AUTOSAR XML (schema 4-2-2)
package /DBC_SysDesc_Can_Network/Pkg_Cluster
  can cluster Can_Network: baudrate=500000, protocol-name=CAN
    can physical channel Can_Network_Channel: comm-connectors=Conn_Can_Network_CANNODE_0_BMS
      frame TMR_3: id 0x328, to BMS, frame-length=8, can-addressing-mode=STANDARD, can-frame-rx-behavior=ANY
        carries pdu TMR_3: packing-byte-order=big-endian, start-position=7, update-indication-bit-position=-1
        pdu TMR_3: length=8, transmission-mode-false-timing=cyclic-timing={time-offset=0.0, time-period=0.05}, transmission-mode-true-timing=cyclic-timing={time-offset=0.0, time-period=0.05}
          transmission-mode-conditions:
            {data-filter={data-filter-type=NEW-IS-WITHIN, max=1021, min=0, offset=0}, i-signal-in-i-pdu=TMR_VoltageHV}
            {data-filter={data-filter-type=NEW-IS-WITHIN, max=2044, min=0}, i-signal-in-i-pdu=TMR_CurrentHV}
          signal TMR_VoltageHV: start 12, 10 bit, big-endian, init-value=0, base-type=uint16, compu {raw=phys for phys 0..1021; unit V}, update-indication-bit-position=-1, to BMS  # HV voltage at the DC/AC converter"
          signal TMR_CurrentHV: start 7, 11 bit, big-endian, init-value=1023, base-type=uint16, compu {raw=phys+1023 for phys -1023..1021; unit Ampere}, update-indication-bit-position=-1, to BMS  # HV current at the DC/AC converter"
      frame EMS_4_G: id 0x4D9, to BMS, frame-length=8, can-addressing-mode=STANDARD, can-frame-rx-behavior=ANY  # Source network message is \"Cyclic, 100ms\". If no messages are received on source network, no messages are sent on the destination network."
        carries pdu EMS_4_G: packing-byte-order=big-endian, start-position=7, update-indication-bit-position=-1
        pdu EMS_4_G: length=8, transmission-mode-condition{data-filter={data-filter-type=NEW-IS-WITHIN, max=65532, min=0, offset=0}, i-signal-in-i-pdu=EMS_4_G_EngineSpeed_Actual}, transmission-mode-false-timing=cyclic-timing={time-offset=0.0, time-period=0.1}, transmission-mode-true-timing=cyclic-timing={time-offset=0.0, time-period=0.1}  # Source network message is \Cyclic, 100ms\. If no messages are received on source network, no messages are sent on the destination network.
          signal EMS_4_G_EngineSpeed_Actual: start 7, 16 bit, big-endian, init-value=0, base-type=uint16, compu {raw=phys*4 for phys 0..16383; unit rpm}, update-indication-bit-position=-1, to BMS  # PHEV:Actual Engine speed send by EMS to HCU"
      frame OBC_2: id 0x428, to BMS, frame-length=8, can-addressing-mode=STANDARD, can-frame-rx-behavior=ANY
        carries pdu OBC_2: packing-byte-order=big-endian, start-position=7, update-indication-bit-position=-1
        pdu OBC_2: length=8, transmission-mode-false-timing=cyclic-timing={time-offset=0.0, time-period=0.1}, transmission-mode-true-timing=cyclic-timing={time-offset=0.0, time-period=0.1}
          transmission-mode-conditions:
            {data-filter={data-filter-type=ALWAYS, max=1, min=0, offset=0}, i-signal-in-i-pdu=OBC_KL30_UnderVolt}
            {data-filter={data-filter-type=NEW-IS-WITHIN, max=20000, min=0, offset=0}, i-signal-in-i-pdu=OBC_InputVolt}
            {data-filter={data-filter-type=NEW-IS-WITHIN, max=8000, min=0, offset=0}, i-signal-in-i-pdu=OBC_InputCurr}
          signal OBC_KL30_UnderVolt: start 55, 1 bit, big-endian, init-value=0, base-type=uint8, compu {raw=phys for phys 0..1, 0=NOFAULT, 1=FAULT}, update-indication-bit-position=-1, to BMS  # KL30 under voltage"
          signal OBC_InputVolt: start 23, 16 bit, big-endian, init-value=0, base-type=uint16, compu {raw=phys*20 for phys 0..1000; unit V}, update-indication-bit-position=-1, to BMS  # OBC input voltage"
          signal OBC_InputCurr: start 7, 16 bit, big-endian, init-value=0, base-type=uint16, compu {raw=phys*20 for phys 0..400; unit Ampere}, update-indication-bit-position=-1, to BMS  # OBC input current"
      frame OBC_4: id 0x43C, to BMS, frame-length=8, can-addressing-mode=STANDARD, can-frame-rx-behavior=ANY
        carries pdu OBC_4: packing-byte-order=big-endian, start-position=7, update-indication-bit-position=-1
        pdu OBC_4: length=8, transmission-mode-false-timing=cyclic-timing={time-offset=0.0, time-period=0.1}, transmission-mode-true-timing=cyclic-timing={time-offset=0.0, time-period=0.1}
          transmission-mode-conditions:
            {data-filter={data-filter-type=ALWAYS, max=0, min=0, offset=0}, i-signal-in-i-pdu=OBC_ChargeSourceMode}
            {data-filter={data-filter-type=ALWAYS, max=255, min=0, offset=0}, i-signal-in-i-pdu=OBC_FaultCode}
            {data-filter={data-filter-type=NEW-IS-WITHIN, max=20000, min=0, offset=0}, i-signal-in-i-pdu=OBC_MaxOutputVoltage}
            {data-filter={data-filter-type=NEW-IS-WITHIN, max=8000, min=0, offset=0}, i-signal-in-i-pdu=OBC_MaxOutputCurrent}
          signal OBC_ChargeSourceMode: start 53, 2 bit, big-endian, init-value=0, base-type=uint8, compu-method=CompuMethod_OBC_ChargeSourceMode, update-indication-bit-position=-1, to BMS  # Charge Source Mode"
          signal OBC_FaultCode: start 39, 8 bit, big-endian, init-value=0, base-type=uint8, compu {raw=phys for phys 0..255}, update-indication-bit-position=-1, to BMS  # OBC fault matrix"
          signal OBC_MaxOutputVoltage: start 23, 16 bit, big-endian, init-value=0, base-type=uint16, compu {raw=phys*20 for phys 0..1000; unit V}, update-indication-bit-position=-1, to BMS  # OBC maximum output current"
          signal OBC_MaxOutputCurrent: start 7, 16 bit, big-endian, init-value=0, base-type=uint16, compu {raw=phys*20 for phys 0..400; unit Ampere}, update-indication-bit-position=-1, to BMS  # OBC maximum output voltage"
      frame ABS_ESP_G: id 0x502, to BMS, frame-length=7, can-addressing-mode=STANDARD, can-frame-rx-behavior=ANY  # Source network message is \"Cyclic, 100ms\". If no messages are received on source network, no messages are sent on the destination network."
        carries pdu ABS_ESP_G: packing-byte-order=big-endian, start-position=7, update-indication-bit-position=-1
        pdu ABS_ESP_G: length=7, transmission-mode-false-timing=cyclic-timing={time-offset=0.0, time-period=0.1}, transmission-mode-true-timing=cyclic-timing={time-offset=0.0, time-period=0.1}  # Source network message is \Cyclic, 100ms\. If no messages are received on source network, no messages are sent on the destination network.
          transmission-mode-conditions:
            {data-filter={data-filter-type=ALWAYS, max=1, min=0, offset=0}, i-signal-in-i-pdu=VehicleSpeedVSOSigValidData}
            {data-filter={data-filter-type=NEW-IS-WITHIN, max=8190, min=0, offset=0}, i-signal-in-i-pdu=VehicleSpeedVSOSig}
          signal VehicleSpeedVSOSigValidData: start 31, 1 bit, big-endian, init-value=1, base-type=uint8, compu {raw=phys for phys 0..1, 0=VALID, 1=NOTVALID}, update-indication-bit-position=-1, to BMS
          signal VehicleSpeedVSOSig: start 12, 13 bit, big-endian, init-value=0, base-type=uint16, compu {raw=phys*16 for phys 0..511.875; unit km_h}, update-indication-bit-position=-1, to BMS
      frame TMR_1: id 0x173, to BMS, frame-length=8, can-addressing-mode=STANDARD, can-frame-rx-behavior=ANY
        carries pdu TMR_1: packing-byte-order=big-endian, start-position=7, update-indication-bit-position=-1
        pdu TMR_1: length=8, transmission-mode-condition{data-filter={data-filter-type=ALWAYS, max=15, min=0, offset=0}, i-signal-in-i-pdu=TMR_State}, transmission-mode-false-timing=cyclic-timing={time-offset=0.0, time-period=0.01}, transmission-mode-true-timing=cyclic-timing={time-offset=0.0, time-period=0.01}
          signal TMR_State: start 55, 4 bit, big-endian, init-value=0, base-type=uint8, compu-method=CompuMethod_TMR_State, update-indication-bit-position=-1, to BMS  # actual state of TMR motor"
      frame OBC_1: id 0x425, to BMS, frame-length=8, can-addressing-mode=STANDARD, can-frame-rx-behavior=ANY
        carries pdu OBC_1: packing-byte-order=big-endian, start-position=7, update-indication-bit-position=-1
        pdu OBC_1: length=8, transmission-mode-false-timing=cyclic-timing={time-offset=0.0, time-period=0.1}, transmission-mode-true-timing=cyclic-timing={time-offset=0.0, time-period=0.1}
          transmission-mode-conditions:
            {data-filter={data-filter-type=ALWAYS, max=7, min=0, offset=0}, i-signal-in-i-pdu=OBC_FaultLevelSts}
            {data-filter={data-filter-type=NEW-IS-WITHIN, max=4000, min=0, offset=0}, i-signal-in-i-pdu=OBC_OutputPowerLimt}
            {data-filter={data-filter-type=NEW-IS-WITHIN, max=20000, min=0, offset=0}, i-signal-in-i-pdu=OBC_ChgVolt}
            {data-filter={data-filter-type=NEW-IS-WITHIN, max=8000, min=0, offset=0}, i-signal-in-i-pdu=OBC_ChgCurr}
          signal OBC_FaultLevelSts: start 41, 3 bit, big-endian, init-value=0, base-type=uint8, compu-method=CompuMethod_OBC_FaultLevelSts, update-indication-bit-position=-1, to BMS  # OBC fault states"
          signal OBC_OutputPowerLimt: start 39, 12 bit, big-endian, init-value=0, base-type=uint16, compu {raw=phys*10 for phys 0..400; unit KW}, update-indication-bit-position=-1, to BMS  # output power limit"
          signal OBC_ChgVolt: start 23, 16 bit, big-endian, init-value=0, base-type=uint16, compu {raw=phys*20 for phys 0..1000; unit V}, update-indication-bit-position=-1, to BMS  # output voltage"
          signal OBC_ChgCurr: start 7, 16 bit, big-endian, init-value=0, base-type=uint16, compu {raw=phys*20 for phys 0..400; unit Ampere}, update-indication-bit-position=-1, to BMS  # output current"
      frame TMF_3: id 0x31B, to BMS, frame-length=8, can-addressing-mode=STANDARD, can-frame-rx-behavior=ANY
        carries pdu TMF_3: packing-byte-order=big-endian, start-position=7, update-indication-bit-position=-1
        pdu TMF_3: length=8, transmission-mode-false-timing=cyclic-timing={time-offset=0.0, time-period=0.05}, transmission-mode-true-timing=cyclic-timing={time-offset=0.0, time-period=0.05}
          transmission-mode-conditions:
            {data-filter={data-filter-type=NEW-IS-WITHIN, max=1021, min=0, offset=0}, i-signal-in-i-pdu=TMF_UdcAct}
            {data-filter={data-filter-type=NEW-IS-WITHIN, max=2044, min=0}, i-signal-in-i-pdu=TMF_IdcAct}
          signal TMF_UdcAct: start 12, 10 bit, big-endian, init-value=0, base-type=uint16, compu {raw=phys for phys 0..1021; unit V}, update-indication-bit-position=-1, to BMS  # actual bus voltage"
          signal TMF_IdcAct: start 7, 11 bit, big-endian, init-value=1023, base-type=uint16, compu {raw=phys+1023 for phys -1023..1021; unit Ampere}, update-indication-bit-position=-1, to BMS  # actual HV current at generator"
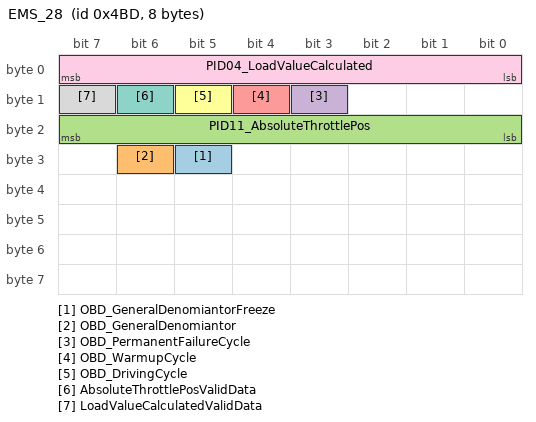
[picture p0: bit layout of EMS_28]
      frame EMS_28: id 0x4BD, to BMS, frame-length=8, can-addressing-mode=STANDARD, can-frame-rx-behavior=ANY  # Source network message is \"Cyclic, 100ms\". If no messages are received on source network, no messages are sent on the destination network."
        carries pdu EMS_28: packing-byte-order=big-endian, start-position=7, update-indication-bit-position=-1
        pdu EMS_28: length=8, transmission-mode-false-timing=cyclic-timing={time-offset=0.0, time-period=0.1}, transmission-mode-true-timing=cyclic-timing={time-offset=0.0, time-period=0.1}  # Source network message is \Cyclic, 100ms\. If no messages are received on source network, no messages are sent on the destination network.
          transmission-mode-conditions:
            {data-filter={data-filter-type=ALWAYS, max=1, min=0, offset=0}, i-signal-in-i-pdu=OBD_GeneralDenomiantorFreeze}
            {data-filter={data-filter-type=ALWAYS, max=1, min=0, offset=0}, i-signal-in-i-pdu=OBD_GeneralDenomiantor}
            {data-filter={data-filter-type=ALWAYS, max=255, min=0, offset=0}, i-signal-in-i-pdu=PID11_AbsoluteThrottlePos}
            {data-filter={data-filter-type=ALWAYS, max=1, min=0, offset=0}, i-signal-in-i-pdu=OBD_PermanentFailureCycle}
            {data-filter={data-filter-type=ALWAYS, max=1, min=0, offset=0}, i-signal-in-i-pdu=OBD_WarmupCycle}
            {data-filter={data-filter-type=ALWAYS, max=1, min=0, offset=0}, i-signal-in-i-pdu=OBD_DrivingCycle}
            {data-filter={data-filter-type=ALWAYS, max=1, min=0, offset=0}, i-signal-in-i-pdu=AbsoluteThrottlePosValidData}
            {data-filter={data-filter-type=ALWAYS, max=1, min=0, offset=0}, i-signal-in-i-pdu=LoadValueCalculatedValidData}
            {data-filter={data-filter-type=ALWAYS, max=255, min=0, offset=0}, i-signal-in-i-pdu=PID04_LoadValueCalculated}
          signal OBD_GeneralDenomiantorFreeze: start 29, 1 bit, big-endian, init-value=0, base-type=uint8, compu {raw=phys for phys 0..1, 0=NOTACTIVE, 1=ACTIVE}, update-indication-bit-position=-1, to BMS
          signal OBD_GeneralDenomiantor: start 30, 1 bit, big-endian, init-value=0, base-type=uint8, compu {raw=phys for phys 0..1, 0=NOTACTIVE, 1=ACTIVE}, update-indication-bit-position=-1, to BMS
          signal PID11_AbsoluteThrottlePos: start 23, 8 bit, big-endian, init-value=0, base-type=uint8, compu {raw=phys*2.551020408 for phys 0..99.96}, update-indication-bit-position=-1, to BMS  # ?????????¦Ë??"
          signal OBD_PermanentFailureCycle: start 11, 1 bit, big-endian, init-value=0, base-type=uint8, compu {raw=phys for phys 0..1, 0=NOTACTIVE, 1=ACTIVE}, update-indication-bit-position=-1, to BMS  # ???¨´????????"
          signal OBD_WarmupCycle: start 12, 1 bit, big-endian, init-value=0, base-type=uint8, compu {raw=phys for phys 0..1, 0=NOTACTIVE, 1=ACTIVE}, update-indication-bit-position=-1, to BMS  # ??????"
          signal OBD_DrivingCycle: start 13, 1 bit, big-endian, init-value=0, base-type=uint8, compu-method=CompuMethod_OBD_DrivingCycle, update-indication-bit-position=-1, to BMS  # DrivingCycle ??????"
          signal AbsoluteThrottlePosValidData: start 14, 1 bit, big-endian, init-value=0, base-type=uint8, compu {raw=phys for phys 0..1, 0=VALID, 1=INVALID}, update-indication-bit-position=-1, to BMS  # ?????????¦Ë????§¹¦Ë"
          signal LoadValueCalculatedValidData: start 15, 1 bit, big-endian, init-value=0, base-type=uint8, compu {raw=phys for phys 0..1, 0=VALID, 1=INVALID}, update-indication-bit-position=-1, to BMS  # ????????????§¹¦Ë"
          signal PID04_LoadValueCalculated: start 7, 8 bit, big-endian, init-value=0, base-type=uint8, compu {raw=phys*2.551020408 for phys 0..99.96}, update-indication-bit-position=-1, to BMS  # ??????????"
      frame CLM_2: id 0x535, to BMS, frame-length=8, can-addressing-mode=STANDARD, can-frame-rx-behavior=ANY  # Source network message is \"Cyclic, 100ms\". If no messages are received on source network, no messages are sent on the destination network."
        carries pdu CLM_2: packing-byte-order=big-endian, start-position=7, update-indication-bit-position=-1
        pdu CLM_2: length=8, transmission-mode-false-timing=cyclic-timing={time-offset=0.0, time-period=0.1}, transmission-mode-true-timing=cyclic-timing={time-offset=0.0, time-period=0.1}  # Source network message is \Cyclic, 100ms\. If no messages are received on source network, no messages are sent on the destination network.
          transmission-mode-conditions:
            {data-filter={data-filter-type=ALWAYS, max=250, min=0}, i-signal-in-i-pdu=ExternalTemperatureRaw_C}
            {data-filter={data-filter-type=ALWAYS, max=3, min=0, offset=0}, i-signal-in-i-pdu=ExternalTemperatureFailSts_GS}
          signal ExternalTemperatureRaw_C: start 55, 8 bit, big-endian, init-value=254, base-type=uint8, compu {raw=phys*2+80 for phys -40..85; unit C}, update-indication-bit-position=-1, to BMS  # Raw external temperature Invalid: When external temperature is fail, the signal value is 0xFF."
          signal ExternalTemperatureFailSts_GS: start 33, 2 bit, big-endian, init-value=0, base-type=uint8, compu-method=CompuMethod_ExternalTemperatureFailSts_GS, update-indication-bit-position=-1, to BMS  # ??????1?????? ???!mao!????????????"
      frame HCU_1_G: id 0x40A, to BMS, frame-length=8, can-addressing-mode=STANDARD, can-frame-rx-behavior=ANY
        carries pdu HCU_1_G: packing-byte-order=big-endian, start-position=7, update-indication-bit-position=-1
        pdu HCU_1_G: length=8, transmission-mode-false-timing=cyclic-timing={time-offset=0.0, time-period=0.1}, transmission-mode-true-timing=cyclic-timing={time-offset=0.0, time-period=0.1}
          transmission-mode-conditions:
            {data-filter={data-filter-type=ALWAYS, max=1, min=0, offset=0}, i-signal-in-i-pdu=HCU_PTReady}
            {data-filter={data-filter-type=ALWAYS, max=1, min=0, offset=0}, i-signal-in-i-pdu=HCU_HVReady}
          signal HCU_PTReady: start 49, 1 bit, big-endian, init-value=0, base-type=uint8, compu {raw=phys for phys 0..1, 0=LMPOFF, 1=LMPON}, update-indication-bit-position=-1, to BMS  # Drive Ready indication"
          signal HCU_HVReady: start 48, 1 bit, big-endian, init-value=0, base-type=uint8, compu {raw=phys for phys 0..1, 0=LMPOFF, 1=LMPON}, update-indication-bit-position=-1, to BMS  # HV Ready indication"
      frame TBOX_3: id 0x358, to BMS, frame-length=8, can-addressing-mode=STANDARD, can-frame-rx-behavior=ANY  # Source network message is \"Cyclic, 50ms\". If no messages are received on source network, no messages are sent on the destination network."
        carries pdu TBOX_3: packing-byte-order=big-endian, start-position=7, update-indication-bit-position=-1
        pdu TBOX_3: length=8, transmission-mode-condition{data-filter={data-filter-type=ALWAYS, max=1, min=0, offset=0}, i-signal-in-i-pdu=TBOX_ChargeAllow}, transmission-mode-false-timing=cyclic-timing={time-offset=0.0, time-period=0.05}, transmission-mode-true-timing=cyclic-timing={time-offset=0.0, time-period=0.05}  # Source network message is \Cyclic, 50ms\. If no messages are received on source network, no messages are sent on the destination network.
          signal TBOX_ChargeAllow: start 53, 1 bit, big-endian, init-value=0, base-type=uint8, compu {raw=phys for phys 0..1, 0=NOTALLOW, 1=ALLOW}, update-indication-bit-position=-1, to BMS
      frame DCDC_2: id 0x41E, to BMS, frame-length=8, can-addressing-mode=STANDARD, can-frame-rx-behavior=ANY
        carries pdu DCDC_2: packing-byte-order=big-endian, start-position=7, update-indication-bit-position=-1
        pdu DCDC_2: length=8, transmission-mode-false-timing=cyclic-timing={time-offset=0.0, time-period=0.1}, transmission-mode-true-timing=cyclic-timing={time-offset=0.0, time-period=0.1}
          transmission-mode-conditions:
            {data-filter={data-filter-type=NEW-IS-WITHIN, max=4000, min=0, offset=0}, i-signal-in-i-pdu=DCDC_HvCurr}
            {data-filter={data-filter-type=NEW-IS-WITHIN, max=10000, min=0, offset=0}, i-signal-in-i-pdu=DCDC_HvVolt}
          signal DCDC_HvCurr: start 23, 16 bit, big-endian, init-value=0, base-type=uint16, compu {raw=phys*10 for phys 0..400; unit Ampere}, update-indication-bit-position=-1, to BMS  # DCDC input current"
          signal DCDC_HvVolt: start 7, 16 bit, big-endian, init-value=0, base-type=uint16, compu {raw=phys*10 for phys 0..1000; unit V}, update-indication-bit-position=-1, to BMS  # DCDC input voltage"
      frame Diag_BMS_REQ: id 0x7E5, to BMS, frame-length=8, can-addressing-mode=STANDARD, can-frame-rx-behavior=ANY  # Source network message is \"NoMsgSendType\". If no messages are received on source network, no messages are sent on the destination network."
        carries pdu Diag_BMS_REQ: packing-byte-order=big-endian, start-position=7, update-indication-bit-position=-1
        dcm i pdu Diag_BMS_REQ: length=8, diag-pdu-type=DIAG-REQUEST  # Source network message is \NoMsgSendType\. If no messages are received on source network, no messages are sent on the destination network.
      frame ICM_1: id 0x430, to BMS, frame-length=8, can-addressing-mode=STANDARD, can-frame-rx-behavior=ANY  # Source network message is \"Cyclic, 20ms\". If no messages are received on source network, no messages are sent on the destination network."
        carries pdu ICM_1: packing-byte-order=big-endian, start-position=7, update-indication-bit-position=-1
        pdu ICM_1: length=8, transmission-mode-false-timing=cyclic-timing={time-offset=0.0, time-period=0.02}, transmission-mode-true-timing=cyclic-timing={time-offset=0.0, time-period=0.02}  # Source network message is \Cyclic, 20ms\. If no messages are received on source network, no messages are sent on the destination network.
          transmission-mode-conditions:
            {data-filter={data-filter-type=NEW-IS-WITHIN, max=999999, min=0, offset=0}, i-signal-in-i-pdu=TotalOdometer_km}
            {data-filter={data-filter-type=ALWAYS, max=254, min=0, offset=0}, i-signal-in-i-pdu=BatteryVoltage}
          signal TotalOdometer_km: start 43, 20 bit, big-endian, init-value=0, base-type=uint32, compu {raw=phys for phys 0..999999; unit km}, update-indication-bit-position=-1, to BMS
          signal BatteryVoltage: start 23, 8 bit, big-endian, init-value=0, base-type=uint8, compu {raw=phys*10 for phys 0..25.4; unit V}, update-indication-bit-position=-1, to BMS  # ????????????????"
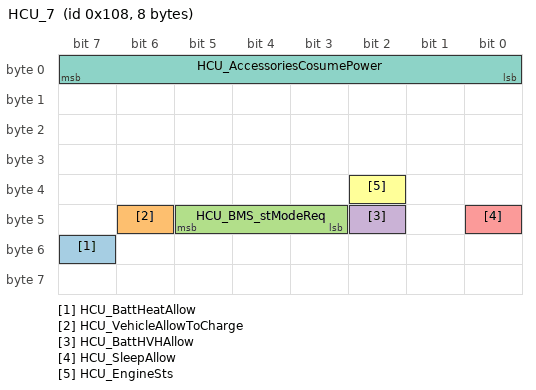
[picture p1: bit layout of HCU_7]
      frame HCU_7: id 0x108, to BMS, frame-length=8, can-addressing-mode=STANDARD, can-frame-rx-behavior=ANY
        carries pdu HCU_7: packing-byte-order=big-endian, start-position=7, update-indication-bit-position=-1
        pdu HCU_7: length=8, transmission-mode-false-timing=cyclic-timing={time-offset=0.0, time-period=0.01}, transmission-mode-true-timing=cyclic-timing={time-offset=0.0, time-period=0.01}
          transmission-mode-conditions:
            {data-filter={data-filter-type=ALWAYS, max=1, min=0, offset=0}, i-signal-in-i-pdu=HCU_BattHeatAllow}
            {data-filter={data-filter-type=ALWAYS, max=1, min=0, offset=0}, i-signal-in-i-pdu=HCU_VehicleAllowToCharge}
            {data-filter={data-filter-type=ALWAYS, max=7, min=0, offset=0}, i-signal-in-i-pdu=HCU_BMS_stModeReq}
            {data-filter={data-filter-type=ALWAYS, max=1, min=0, offset=0}, i-signal-in-i-pdu=HCU_BattHVHAllow}
            {data-filter={data-filter-type=ALWAYS, max=1, min=0, offset=0}, i-signal-in-i-pdu=HCU_SleepAllow}
            {data-filter={data-filter-type=ALWAYS, max=1, min=0, offset=0}, i-signal-in-i-pdu=HCU_EngineSts}
            {data-filter={data-filter-type=ALWAYS, max=200, min=0, offset=0}, i-signal-in-i-pdu=HCU_AccessoriesCosumePower}
          signal HCU_BattHeatAllow: start 55, 1 bit, big-endian, init-value=0, base-type=uint8, compu {raw=phys for phys 0..1, 0=NOREQUEST, 1=REQUEST}, update-indication-bit-position=-1, to BMS  # Battery pack heat request"
          signal HCU_VehicleAllowToCharge: start 46, 1 bit, big-endian, init-value=0, base-type=uint8, compu {raw=phys for phys 0..1, 0=NOTALLOWED, 1=ALLOWED}, update-indication-bit-position=-1, to BMS  # Indication of vehicle condition allow to charge or not"
          signal HCU_BMS_stModeReq: start 45, 3 bit, big-endian, init-value=0, base-type=uint8, compu-method=CompuMethod_HCU_BMS_stModeReq, update-indication-bit-position=-1, to BMS  # BMS recieves State request from HCU for power Up / power Down."
          signal HCU_BattHVHAllow: start 42, 1 bit, big-endian, init-value=0, base-type=uint8, compu {raw=phys for phys 0..1, 0=NOTALLOWED, 1=ALLOWED}, update-indication-bit-position=-1, to BMS  # high voltage heat allow"
          signal HCU_SleepAllow: start 40, 1 bit, big-endian, init-value=0, base-type=uint8, compu {raw=phys for phys 0..1, 0=ALLOWED, 1=NOTALLOWED}, update-indication-bit-position=-1, to BMS  # sleep allow command"
          signal HCU_EngineSts: start 34, 1 bit, big-endian, init-value=0, base-type=uint8, compu {raw=phys for phys 0..1, 0=NOTRUN, 1=RUN}, update-indication-bit-position=-1, to BMS  # actual engine status"
          signal HCU_AccessoriesCosumePower: start 7, 8 bit, big-endian, init-value=0, base-type=uint8, compu {raw=phys*10 for phys 0..20; unit KW}, update-indication-bit-position=-1, to BMS  # Accessories Consume Power"
      frame EMS_1_G: id 0x280, to BMS, frame-length=8, can-addressing-mode=STANDARD, can-frame-rx-behavior=ANY  # Source network message is \"Cyclic, 100ms\". If no messages are received on source network, no messages are sent on the destination network."
        carries pdu EMS_1_G: packing-byte-order=big-endian, start-position=7, update-indication-bit-position=-1
        pdu EMS_1_G: length=8, transmission-mode-false-timing=cyclic-timing={time-offset=0.0, time-period=0.1}, transmission-mode-true-timing=cyclic-timing={time-offset=0.0, time-period=0.1}  # Source network message is \Cyclic, 100ms\. If no messages are received on source network, no messages are sent on the destination network.
          transmission-mode-conditions:
            {data-filter={data-filter-type=ALWAYS, max=254, min=0}, i-signal-in-i-pdu=EngineCoolantTemperture}
            {data-filter={data-filter-type=ALWAYS, max=1, min=0, offset=0}, i-signal-in-i-pdu=EngineCoolantTempertureFailSts}
          signal EngineCoolantTemperture: start 23, 8 bit, big-endian, init-value=91, base-type=uint8, compu {raw=phys*1.333333333+64 for phys -48..142.5}, update-indication-bit-position=-1, to BMS
          signal EngineCoolantTempertureFailSts: start 11, 1 bit, big-endian, init-value=91, base-type=uint8, compu {raw=phys for phys 0..1, 0=FAILNOTPRESENT, 1=FAILPRESENT}, update-indication-bit-position=-1, to BMS
      frame DCDC_1: id 0x418, to BMS, frame-length=8, can-addressing-mode=STANDARD, can-frame-rx-behavior=ANY
        carries pdu DCDC_1: packing-byte-order=big-endian, start-position=7, update-indication-bit-position=-1
        pdu DCDC_1: length=8, transmission-mode-false-timing=cyclic-timing={time-offset=0.0, time-period=0.1}, transmission-mode-true-timing=cyclic-timing={time-offset=0.0, time-period=0.1}
          transmission-mode-conditions:
            {data-filter={data-filter-type=NEW-IS-WITHIN, max=510, min=0, offset=0}, i-signal-in-i-pdu=DCDC_LvSideCurr}
            {data-filter={data-filter-type=ALWAYS, max=253, min=0, offset=0}, i-signal-in-i-pdu=DCDC_LvSideVolt}
          signal DCDC_LvSideCurr: start 31, 9 bit, big-endian, init-value=0, base-type=uint16, compu {raw=phys for phys 0..510; unit Ampere}, update-indication-bit-position=-1, to BMS  # DCDC output current"
          signal DCDC_LvSideVolt: start 7, 8 bit, big-endian, init-value=0, base-type=uint8, compu {raw=phys*10 for phys 0..25.3; unit V}, update-indication-bit-position=-1, to BMS  # DCDC output voltage"
      frame DIAG_OBD_REQ_Broadcast: id 0x7DF, to BMS, frame-length=8, can-addressing-mode=STANDARD, can-frame-rx-behavior=ANY  # Source network message is \"NoMsgSendType,/\". If no messages are received on source network, no messages are sent on the destination network."
        carries pdu DIAG_OBD_REQ_Broadcast: packing-byte-order=big-endian, start-position=7, update-indication-bit-position=-1
        dcm i pdu DIAG_OBD_REQ_Broadcast: length=8, diag-pdu-type=DIAG-RESPONSE  # Source network message is \NoMsgSendType,/\. If no messages are received on source network, no messages are sent on the destination network.
      frame ISGF_3: id 0x312, to BMS, frame-length=8, can-addressing-mode=STANDARD, can-frame-rx-behavior=ANY
        carries pdu ISGF_3: packing-byte-order=big-endian, start-position=7, update-indication-bit-position=-1
        pdu ISGF_3: length=8, transmission-mode-false-timing=cyclic-timing={time-offset=0.0, time-period=0.05}, transmission-mode-true-timing=cyclic-timing={time-offset=0.0, time-period=0.05}
          transmission-mode-conditions:
            {data-filter={data-filter-type=NEW-IS-WITHIN, max=1021, min=0, offset=0}, i-signal-in-i-pdu=ISGF_UdcAct}
            {data-filter={data-filter-type=NEW-IS-WITHIN, max=2044, min=0}, i-signal-in-i-pdu=ISGF_IdcAct}
          signal ISGF_UdcAct: start 12, 10 bit, big-endian, init-value=0, base-type=uint16, compu {raw=phys for phys 0..1021; unit V}, update-indication-bit-position=-1, to BMS  # actual bus voltage"
          signal ISGF_IdcAct: start 7, 11 bit, big-endian, init-value=1023, base-type=uint16, compu {raw=phys+1023 for phys -1023..1021; unit Ampere}, update-indication-bit-position=-1, to BMS  # actual HV current at generator"
      frame TBOX_2: id 0x4F2, to BMS, frame-length=8, can-addressing-mode=STANDARD, can-frame-rx-behavior=ANY  # Source network message is \"NoMsgSendType, /\". If no messages are received on source network, no messages are sent on the destination network."
        carries pdu TBOX_2: packing-byte-order=big-endian, start-position=7, update-indication-bit-position=-1
        pdu TBOX_2: length=8, transmission-mode-condition{data-filter={data-filter-type=ALWAYS, max=3, min=0, offset=0}, i-signal-in-i-pdu=TBOX_BattHeatReq}  # Source network message is \NoMsgSendType, /\. If no messages are received on source network, no messages are sent on the destination network.
          signal TBOX_BattHeatReq: start 41, 2 bit, big-endian, init-value=0, base-type=uint8, compu {raw=phys for phys 0..3, 0=NOTACTIVE, 1=REQUEST, 2=NOREQUEST, 3=NOTUSED}, update-indication-bit-position=-1, to BMS  # ????????????"
      frame ISGF_1: id 0x146, to BMS, frame-length=8, can-addressing-mode=STANDARD, can-frame-rx-behavior=ANY
        carries pdu ISGF_1: packing-byte-order=big-endian, start-position=7, update-indication-bit-position=-1
        pdu ISGF_1: length=8, transmission-mode-condition{data-filter={data-filter-type=ALWAYS, max=15, min=0, offset=0}, i-signal-in-i-pdu=ISGF_ModeSt}, transmission-mode-false-timing=cyclic-timing={time-offset=0.0, time-period=0.01}, transmission-mode-true-timing=cyclic-timing={time-offset=0.0, time-period=0.01}
          signal ISGF_ModeSt: start 55, 4 bit, big-endian, init-value=0, base-type=uint8, compu-method=CompuMethod_ISGF_ModeSt, update-indication-bit-position=-1, to BMS  # actual state of ISG motor"
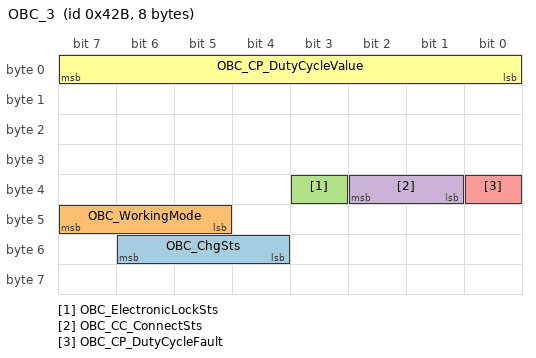
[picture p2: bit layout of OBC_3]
      frame OBC_3: id 0x42B, to BMS, frame-length=8, can-addressing-mode=STANDARD, can-frame-rx-behavior=ANY
        carries pdu OBC_3: packing-byte-order=big-endian, start-position=7, update-indication-bit-position=-1
        pdu OBC_3: length=8, transmission-mode-false-timing=cyclic-timing={time-offset=0.0, time-period=0.1}, transmission-mode-true-timing=cyclic-timing={time-offset=0.0, time-period=0.1}
          transmission-mode-conditions:
            {data-filter={data-filter-type=ALWAYS, max=7, min=0, offset=0}, i-signal-in-i-pdu=OBC_ChgSts}
            {data-filter={data-filter-type=ALWAYS, max=7, min=0, offset=0}, i-signal-in-i-pdu=OBC_WorkingMode}
            {data-filter={data-filter-type=ALWAYS, max=1, min=0, offset=0}, i-signal-in-i-pdu=OBC_ElectronicLockSts}
            {data-filter={data-filter-type=ALWAYS, max=3, min=0, offset=0}, i-signal-in-i-pdu=OBC_CC_ConnectSts}
            {data-filter={data-filter-type=ALWAYS, max=1, min=0, offset=0}, i-signal-in-i-pdu=OBC_CP_DutyCycleFault}
            {data-filter={data-filter-type=ALWAYS, max=100, min=0, offset=0}, i-signal-in-i-pdu=OBC_CP_DutyCycleValue}
          signal OBC_ChgSts: start 54, 3 bit, big-endian, init-value=0, base-type=uint8, compu-method=CompuMethod_OBC_ChgSts, update-indication-bit-position=-1, to BMS  # OBC charge stated"
          signal OBC_WorkingMode: start 47, 3 bit, big-endian, init-value=0, base-type=uint8, compu-method=CompuMethod_OBC_WorkingMode, update-indication-bit-position=-1, to BMS  # OBC working states"
          signal OBC_ElectronicLockSts: start 35, 1 bit, big-endian, init-value=0, base-type=uint8, compu {raw=phys for phys 0..1, 0=UNLOCK, 1=LOCK}, update-indication-bit-position=-1, to BMS  # Electronic Lock Sts"
          signal OBC_CC_ConnectSts: start 34, 2 bit, big-endian, init-value=0, base-type=uint8, compu-method=CompuMethod_OBC_CC_ConnectSts, update-indication-bit-position=-1, to BMS  # CC connect states"
          signal OBC_CP_DutyCycleFault: start 32, 1 bit, big-endian, init-value=0, base-type=uint8, compu {raw=phys for phys 0..1, 0=NOFAULT, 1=FAULT}, update-indication-bit-position=-1, to BMS  # CP pwm fault"
          signal OBC_CP_DutyCycleValue: start 7, 8 bit, big-endian, init-value=0, base-type=uint8, compu {raw=phys for phys 0..100; unit pct}, update-indication-bit-position=-1, to BMS  # CP pwm"
      frame TMF_1: id 0x15C, to BMS, frame-length=8, can-addressing-mode=STANDARD, can-frame-rx-behavior=ANY
        carries pdu TMF_1: packing-byte-order=big-endian, start-position=7, update-indication-bit-position=-1
        pdu TMF_1: length=8, transmission-mode-condition{data-filter={data-filter-type=ALWAYS, max=15, min=0, offset=0}, i-signal-in-i-pdu=TMF_ModeSt}, transmission-mode-false-timing=cyclic-timing={time-offset=0.0, time-period=0.01}, transmission-mode-true-timing=cyclic-timing={time-offset=0.0, time-period=0.01}
          signal TMF_ModeSt: start 55, 4 bit, big-endian, init-value=0, base-type=uint8, compu-method=CompuMethod_TMF_ModeSt, update-indication-bit-position=-1, to BMS  # actual state of TMF motor"
      frame ABM_1: id 0x320, to BMS, frame-length=4, can-addressing-mode=STANDARD, can-frame-rx-behavior=ANY  # Source network message is \"Cyclic, 500ms\". If no messages are received on source network, no messages are sent on the destination network."
        carries pdu ABM_1: packing-byte-order=big-endian, start-position=7, update-indication-bit-position=-1
        pdu ABM_1: length=4, transmission-mode-false-timing=cyclic-timing={time-offset=0.0, time-period=0.5}, transmission-mode-true-timing=cyclic-timing={time-offset=0.0, time-period=0.5}  # Source network message is \Cyclic, 500ms\. If no messages are received on source network, no messages are sent on the destination network.
          transmission-mode-conditions:
            {data-filter={data-filter-type=ALWAYS, max=255, min=0, offset=0}, i-signal-in-i-pdu=CrashOutputSts}
            {data-filter={data-filter-type=ALWAYS, max=255, min=0, offset=0}, i-signal-in-i-pdu=ABM_1_CheckSum}
            {data-filter={data-filter-type=ALWAYS, max=15, min=0, offset=0}, i-signal-in-i-pdu=ABM_1_MessageCounter}
          signal CrashOutputSts: start 31, 8 bit, big-endian, init-value=0, base-type=uint8, compu-method=CompuMethod_CrashOutputSts, update-indication-bit-position=-1, to BMS  # Crash????????bit???????: ?????§Ø???????????!dou!????????????????????¦Ë??????1.????????????????!dou!?????????????00001100"
          signal ABM_1_CheckSum: start 23, 8 bit, big-endian, init-value=0, base-type=uint8, compu {raw=phys for phys 0..255}, update-indication-bit-position=-1, to BMS  # ((Byte0+Byte1+Byte3) AND 0xFF) XOR 0xFF Note: Details Please refer to specification??Standard Specification for CAN Data Link Layer_v1.1??section 2.3.3"
          signal ABM_1_MessageCounter: start 15, 4 bit, big-endian, init-value=0, base-type=uint8, compu {raw=phys for phys 0..15}, update-indication-bit-position=-1, to BMS  # Rolling message counter(the maximum value of Alive counter is 15) Note: Details Please refer to specification??Standard Specification for CAN Data Link Layer_v1.1??section 2.3.1"
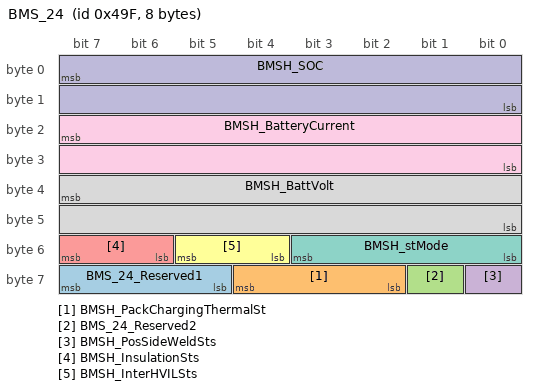
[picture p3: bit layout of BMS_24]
      frame BMS_24: id 0x49F, from BMS, frame-length=8, can-addressing-mode=STANDARD
        carries pdu BMS_24: packing-byte-order=big-endian, start-position=7, update-indication-bit-position=-1
        pdu BMS_24: length=8, transmission-mode-false-timing=cyclic-timing={time-offset=0.0, time-period=0.1}, transmission-mode-true-timing=cyclic-timing={time-offset=0.0, time-period=0.1}
          transmission-mode-conditions:
            {data-filter={data-filter-type=ALWAYS, max=0, min=0, offset=0}, i-signal-in-i-pdu=BMS_24_Reserved1}
            {data-filter={data-filter-type=ALWAYS, max=7, min=0, offset=0}, i-signal-in-i-pdu=BMSH_PackChargingThermalSt}
            {data-filter={data-filter-type=ALWAYS, max=0, min=0, offset=0}, i-signal-in-i-pdu=BMS_24_Reserved2}
            {data-filter={data-filter-type=ALWAYS, max=1, min=0, offset=0}, i-signal-in-i-pdu=BMS_24/BMSH_PosSideWeldSts}
            {data-filter={data-filter-type=ALWAYS, max=3, min=0, offset=0}, i-signal-in-i-pdu=BMS_24/BMSH_InsulationSts}
            {data-filter={data-filter-type=ALWAYS, max=3, min=0, offset=0}, i-signal-in-i-pdu=BMS_24/BMSH_InterHVILSts}
            {data-filter={data-filter-type=ALWAYS, max=15, min=0, offset=0}, i-signal-in-i-pdu=BMS_24/BMSH_stMode}
            {data-filter={data-filter-type=NEW-IS-WITHIN, max=20000, min=0, offset=0}, i-signal-in-i-pdu=BMS_24/BMSH_BattVolt}
            {data-filter={data-filter-type=NEW-IS-WITHIN, max=44000, min=20000}, i-signal-in-i-pdu=BMS_24/BMSH_BatteryCurrent}
            {data-filter={data-filter-type=NEW-IS-WITHIN, max=10000, min=0, offset=0}, i-signal-in-i-pdu=BMS_24/BMSH_SOC}
          signal BMS_24_Reserved1: start 63, 3 bit, big-endian, init-value=0, base-type=uint8, compu {raw=phys for phys 0}, update-indication-bit-position=-1
          signal BMSH_PackChargingThermalSt: start 60, 3 bit, big-endian, init-value=0, base-type=uint8, compu-method=CompuMethod_BMSH_PackChargingThermalSt, update-indication-bit-position=-1  # Pack Charging Thermal Status"
          signal BMS_24_Reserved2: start 57, 1 bit, big-endian, init-value=0, base-type=uint8, compu {raw=phys for phys 0}, update-indication-bit-position=-1
          signal BMSH_PosSideWeldSts: start 56, 1 bit, big-endian, init-value=0, base-type=uint8, compu {raw=phys for phys 0..1, 0=NOWELDED, 1=WELDED}, update-indication-bit-position=-1  # main Positive Side Weld Status"
          signal BMSH_InsulationSts: start 55, 2 bit, big-endian, init-value=0, base-type=uint8, compu-method=CompuMethod_BMSH_InsulationSts, update-indication-bit-position=-1  # Insulation Status"
          signal BMSH_InterHVILSts: start 53, 2 bit, big-endian, init-value=0, base-type=uint8, compu-method=CompuMethod_BMSH_InterHVILSts, update-indication-bit-position=-1  # Inter HV interlock Status"
          signal BMSH_stMode: start 51, 4 bit, big-endian, init-value=0, base-type=uint8, compu-method=CompuMethod_BMSH_stMode, update-indication-bit-position=-1  # state mode"
          signal BMSH_BattVolt: start 39, 16 bit, big-endian, init-value=0, base-type=uint16, compu {raw=phys*20 for phys 0..1000; unit V}, update-indication-bit-position=-1  # Battery Voltage"
          signal BMSH_BatteryCurrent: start 23, 16 bit, big-endian, init-value=32000, base-type=uint16, compu {raw=phys*20+32000 for phys -600..600; unit Ampere}, update-indication-bit-position=-1  # Battery Current"
          signal BMSH_SOC: start 7, 16 bit, big-endian, init-value=0, base-type=uint16, compu {raw=phys*100 for phys 0..100; unit pct}, update-indication-bit-position=-1  # SOC"
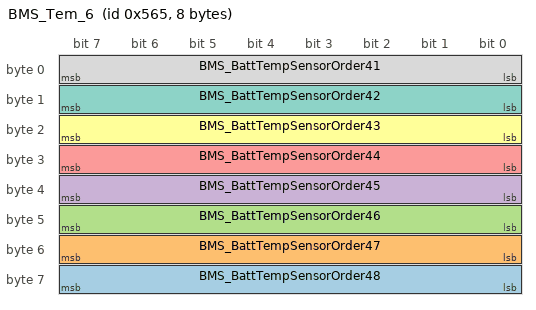
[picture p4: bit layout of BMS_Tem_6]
      frame BMS_Tem_6: id 0x565, from BMS, frame-length=8, can-addressing-mode=STANDARD
        carries pdu BMS_Tem_6: packing-byte-order=big-endian, start-position=7, update-indication-bit-position=-1
        pdu BMS_Tem_6: length=8, transmission-mode-false-timing=cyclic-timing={time-offset=0.0, time-period=1.0}, transmission-mode-true-timing=cyclic-timing={time-offset=0.0, time-period=1.0}
          transmission-mode-conditions:
            {data-filter={data-filter-type=ALWAYS, max=253, min=0}, i-signal-in-i-pdu=BMS_BattTempSensorOrder48}
            {data-filter={data-filter-type=ALWAYS, max=253, min=0}, i-signal-in-i-pdu=BMS_BattTempSensorOrder47}
            {data-filter={data-filter-type=ALWAYS, max=253, min=0}, i-signal-in-i-pdu=BMS_BattTempSensorOrder46}
            {data-filter={data-filter-type=ALWAYS, max=253, min=0}, i-signal-in-i-pdu=BMS_BattTempSensorOrder45}
            {data-filter={data-filter-type=ALWAYS, max=253, min=0}, i-signal-in-i-pdu=BMS_BattTempSensorOrder44}
            {data-filter={data-filter-type=ALWAYS, max=253, min=0}, i-signal-in-i-pdu=BMS_BattTempSensorOrder43}
            {data-filter={data-filter-type=ALWAYS, max=253, min=0}, i-signal-in-i-pdu=BMS_BattTempSensorOrder42}
            {data-filter={data-filter-type=ALWAYS, max=253, min=0}, i-signal-in-i-pdu=BMS_BattTempSensorOrder41}
          signal BMS_BattTempSensorOrder48: start 63, 8 bit, big-endian, init-value=0, base-type=uint8, compu {raw=phys+40 for phys -40..213; unit oC}, update-indication-bit-position=-1  # Battery Temperature Sensor Order48"
          signal BMS_BattTempSensorOrder47: start 55, 8 bit, big-endian, init-value=0, base-type=uint8, compu {raw=phys+40 for phys -40..213; unit oC}, update-indication-bit-position=-1  # Battery Temperature Sensor Order47"
          signal BMS_BattTempSensorOrder46: start 47, 8 bit, big-endian, init-value=0, base-type=uint8, compu {raw=phys+40 for phys -40..213; unit oC}, update-indication-bit-position=-1  # Battery Temperature Sensor Order46"
          signal BMS_BattTempSensorOrder45: start 39, 8 bit, big-endian, init-value=0, base-type=uint8, compu {raw=phys+40 for phys -40..213; unit oC}, update-indication-bit-position=-1  # Battery Temperature Sensor Order45"
          signal BMS_BattTempSensorOrder44: start 31, 8 bit, big-endian, init-value=0, base-type=uint8, compu {raw=phys+40 for phys -40..213; unit oC}, update-indication-bit-position=-1  # Battery Temperature Sensor Order44"
          signal BMS_BattTempSensorOrder43: start 23, 8 bit, big-endian, init-value=0, base-type=uint8, compu {raw=phys+40 for phys -40..213; unit oC}, update-indication-bit-position=-1  # Battery Temperature Sensor Order43"
          signal BMS_BattTempSensorOrder42: start 15, 8 bit, big-endian, init-value=0, base-type=uint8, compu {raw=phys+40 for phys -40..213; unit oC}, update-indication-bit-position=-1  # Battery Temperature Sensor Order42"
          signal BMS_BattTempSensorOrder41: start 7, 8 bit, big-endian, init-value=0, base-type=uint8, compu {raw=phys+40 for phys -40..213; unit oC}, update-indication-bit-position=-1  # Battery Temperature Sensor Order41"
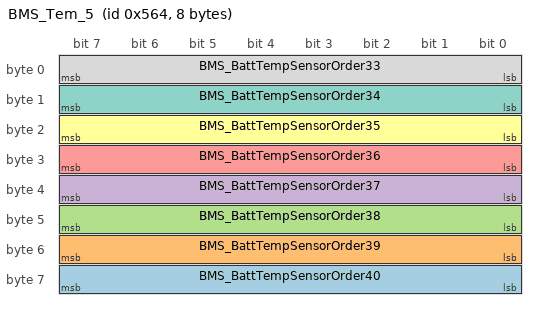
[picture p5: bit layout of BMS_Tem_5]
      frame BMS_Tem_5: id 0x564, from BMS, frame-length=8, can-addressing-mode=STANDARD
        carries pdu BMS_Tem_5: packing-byte-order=big-endian, start-position=7, update-indication-bit-position=-1
        pdu BMS_Tem_5: length=8, transmission-mode-false-timing=cyclic-timing={time-offset=0.0, time-period=1.0}, transmission-mode-true-timing=cyclic-timing={time-offset=0.0, time-period=1.0}
          transmission-mode-conditions:
            {data-filter={data-filter-type=ALWAYS, max=253, min=0}, i-signal-in-i-pdu=BMS_BattTempSensorOrder40}
            {data-filter={data-filter-type=ALWAYS, max=253, min=0}, i-signal-in-i-pdu=BMS_BattTempSensorOrder39}
            {data-filter={data-filter-type=ALWAYS, max=253, min=0}, i-signal-in-i-pdu=BMS_BattTempSensorOrder38}
            {data-filter={data-filter-type=ALWAYS, max=253, min=0}, i-signal-in-i-pdu=BMS_BattTempSensorOrder37}
            {data-filter={data-filter-type=ALWAYS, max=253, min=0}, i-signal-in-i-pdu=BMS_BattTempSensorOrder36}
            {data-filter={data-filter-type=ALWAYS, max=253, min=0}, i-signal-in-i-pdu=BMS_BattTempSensorOrder35}
            {data-filter={data-filter-type=ALWAYS, max=253, min=0}, i-signal-in-i-pdu=BMS_BattTempSensorOrder34}
            {data-filter={data-filter-type=ALWAYS, max=253, min=0}, i-signal-in-i-pdu=BMS_BattTempSensorOrder33}
          signal BMS_BattTempSensorOrder40: start 63, 8 bit, big-endian, init-value=0, base-type=uint8, compu {raw=phys+40 for phys -40..213; unit oC}, update-indication-bit-position=-1  # Battery Temperature Sensor Order40"
          signal BMS_BattTempSensorOrder39: start 55, 8 bit, big-endian, init-value=0, base-type=uint8, compu {raw=phys+40 for phys -40..213; unit oC}, update-indication-bit-position=-1  # Battery Temperature Sensor Order39"
          signal BMS_BattTempSensorOrder38: start 47, 8 bit, big-endian, init-value=0, base-type=uint8, compu {raw=phys+40 for phys -40..213; unit oC}, update-indication-bit-position=-1  # Battery Temperature Sensor Order38"
          signal BMS_BattTempSensorOrder37: start 39, 8 bit, big-endian, init-value=0, base-type=uint8, compu {raw=phys+40 for phys -40..213; unit oC}, update-indication-bit-position=-1  # Battery Temperature Sensor Order37"
          signal BMS_BattTempSensorOrder36: start 31, 8 bit, big-endian, init-value=0, base-type=uint8, compu {raw=phys+40 for phys -40..213; unit oC}, update-indication-bit-position=-1  # Battery Temperature Sensor Order36"
          signal BMS_BattTempSensorOrder35: start 23, 8 bit, big-endian, init-value=0, base-type=uint8, compu {raw=phys+40 for phys -40..213; unit oC}, update-indication-bit-position=-1  # Battery Temperature Sensor Order35"
          signal BMS_BattTempSensorOrder34: start 15, 8 bit, big-endian, init-value=0, base-type=uint8, compu {raw=phys+40 for phys -40..213; unit oC}, update-indication-bit-position=-1  # Battery Temperature Sensor Order34"
          signal BMS_BattTempSensorOrder33: start 7, 8 bit, big-endian, init-value=0, base-type=uint8, compu {raw=phys+40 for phys -40..213; unit oC}, update-indication-bit-position=-1  # Battery Temperature Sensor Order33"
      frame BMS_19: id 0x5B2, from BMS, frame-length=8, can-addressing-mode=STANDARD
        carries pdu BMS_19: packing-byte-order=big-endian, start-position=7, update-indication-bit-position=-1
        pdu BMS_19: length=8, transmission-mode-false-timing=cyclic-timing={time-offset=0.0, time-period=1.0}, transmission-mode-true-timing=cyclic-timing={time-offset=0.0, time-period=1.0}
          transmission-mode-conditions:
            {data-filter={data-filter-type=NEW-IS-WITHIN, max=0, min=0, offset=0}, i-signal-in-i-pdu=BMS_DTCOrder6}
            {data-filter={data-filter-type=NEW-IS-WITHIN, max=0, min=0, offset=0}, i-signal-in-i-pdu=BMS_DTCOrder5}
          signal BMS_DTCOrder6: start 39, 24 bit, big-endian, init-value=0, base-type=uint32, compu {raw=phys for phys 0}, update-indication-bit-position=-1  # DTC Order6"
          signal BMS_DTCOrder5: start 7, 24 bit, big-endian, init-value=0, base-type=uint32, compu {raw=phys for phys 0}, update-indication-bit-position=-1  # DTC Order5"
      frame Diag_BMS_RES: id 0x7ED, from BMS, frame-length=8, can-addressing-mode=STANDARD
        carries pdu Diag_BMS_RES: packing-byte-order=big-endian, start-position=7, update-indication-bit-position=-1
        dcm i pdu Diag_BMS_RES: length=8, diag-pdu-type=DIAG-RESPONSE
      frame BMS_18: id 0x5B1, from BMS, frame-length=8, can-addressing-mode=STANDARD
        carries pdu BMS_18: packing-byte-order=big-endian, start-position=7, update-indication-bit-position=-1
        pdu BMS_18: length=8, transmission-mode-false-timing=cyclic-timing={time-offset=0.0, time-period=1.0}, transmission-mode-true-timing=cyclic-timing={time-offset=0.0, time-period=1.0}
          transmission-mode-conditions:
            {data-filter={data-filter-type=NEW-IS-WITHIN, max=0, min=0, offset=0}, i-signal-in-i-pdu=BMS_DTCOrder4}
            {data-filter={data-filter-type=NEW-IS-WITHIN, max=0, min=0, offset=0}, i-signal-in-i-pdu=BMS_DTCOrder3}
          signal BMS_DTCOrder4: start 39, 24 bit, big-endian, init-value=0, base-type=uint32, compu {raw=phys for phys 0}, update-indication-bit-position=-1  # DTC Order4"
          signal BMS_DTCOrder3: start 7, 24 bit, big-endian, init-value=0, base-type=uint32, compu {raw=phys for phys 0}, update-indication-bit-position=-1  # DTC Order3"
      frame BMS_17: id 0x5B0, from BMS, frame-length=8, can-addressing-mode=STANDARD
        carries pdu BMS_17: packing-byte-order=big-endian, start-position=7, update-indication-bit-position=-1
        pdu BMS_17: length=8, transmission-mode-false-timing=cyclic-timing={time-offset=0.0, time-period=1.0}, transmission-mode-true-timing=cyclic-timing={time-offset=0.0, time-period=1.0}
          transmission-mode-conditions:
            {data-filter={data-filter-type=ALWAYS, max=255, min=0, offset=0}, i-signal-in-i-pdu=BMS_DTCTotalNum}
            {data-filter={data-filter-type=NEW-IS-WITHIN, max=0, min=0, offset=0}, i-signal-in-i-pdu=BMS_DTCOrder2}
            {data-filter={data-filter-type=NEW-IS-WITHIN, max=0, min=0, offset=0}, i-signal-in-i-pdu=BMS_DTCOrder1}
          signal BMS_DTCTotalNum: start 63, 8 bit, big-endian, init-value=0, base-type=uint8, compu {raw=phys for phys 0..255}, update-indication-bit-position=-1  # DTC Total Number"
          signal BMS_DTCOrder2: start 39, 24 bit, big-endian, init-value=0, base-type=uint32, compu {raw=phys for phys 0}, update-indication-bit-position=-1  # DTC Order2"
          signal BMS_DTCOrder1: start 7, 24 bit, big-endian, init-value=0, base-type=uint32, compu {raw=phys for phys 0}, update-indication-bit-position=-1  # DTC Order1"
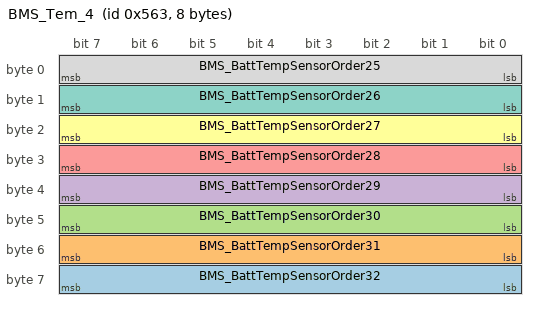
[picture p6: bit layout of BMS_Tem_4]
      frame BMS_Tem_4: id 0x563, from BMS, frame-length=8, can-addressing-mode=STANDARD
        carries pdu BMS_Tem_4: packing-byte-order=big-endian, start-position=7, update-indication-bit-position=-1
        pdu BMS_Tem_4: length=8, transmission-mode-false-timing=cyclic-timing={time-offset=0.0, time-period=1.0}, transmission-mode-true-timing=cyclic-timing={time-offset=0.0, time-period=1.0}
          transmission-mode-conditions:
            {data-filter={data-filter-type=ALWAYS, max=253, min=0}, i-signal-in-i-pdu=BMS_BattTempSensorOrder32}
            {data-filter={data-filter-type=ALWAYS, max=253, min=0}, i-signal-in-i-pdu=BMS_BattTempSensorOrder31}
            {data-filter={data-filter-type=ALWAYS, max=253, min=0}, i-signal-in-i-pdu=BMS_BattTempSensorOrder30}
            {data-filter={data-filter-type=ALWAYS, max=253, min=0}, i-signal-in-i-pdu=BMS_BattTempSensorOrder29}
            {data-filter={data-filter-type=ALWAYS, max=253, min=0}, i-signal-in-i-pdu=BMS_BattTempSensorOrder28}
            {data-filter={data-filter-type=ALWAYS, max=253, min=0}, i-signal-in-i-pdu=BMS_BattTempSensorOrder27}
            {data-filter={data-filter-type=ALWAYS, max=253, min=0}, i-signal-in-i-pdu=BMS_BattTempSensorOrder26}
            {data-filter={data-filter-type=ALWAYS, max=253, min=0}, i-signal-in-i-pdu=BMS_BattTempSensorOrder25}
          signal BMS_BattTempSensorOrder32: start 63, 8 bit, big-endian, init-value=0, base-type=uint8, compu {raw=phys+40 for phys -40..213; unit oC}, update-indication-bit-position=-1  # Battery Temperature Sensor Order32"
          signal BMS_BattTempSensorOrder31: start 55, 8 bit, big-endian, init-value=0, base-type=uint8, compu {raw=phys+40 for phys -40..213; unit oC}, update-indication-bit-position=-1  # Battery Temperature Sensor Order31"
          signal BMS_BattTempSensorOrder30: start 47, 8 bit, big-endian, init-value=0, base-type=uint8, compu {raw=phys+40 for phys -40..213; unit oC}, update-indication-bit-position=-1  # Battery Temperature Sensor Order30"
          signal BMS_BattTempSensorOrder29: start 39, 8 bit, big-endian, init-value=0, base-type=uint8, compu {raw=phys+40 for phys -40..213; unit oC}, update-indication-bit-position=-1  # Battery Temperature Sensor Order29"
          signal BMS_BattTempSensorOrder28: start 31, 8 bit, big-endian, init-value=0, base-type=uint8, compu {raw=phys+40 for phys -40..213; unit oC}, update-indication-bit-position=-1  # Battery Temperature Sensor Order28"
          signal BMS_BattTempSensorOrder27: start 23, 8 bit, big-endian, init-value=0, base-type=uint8, compu {raw=phys+40 for phys -40..213; unit oC}, update-indication-bit-position=-1  # Battery Temperature Sensor Order27"
          signal BMS_BattTempSensorOrder26: start 15, 8 bit, big-endian, init-value=0, base-type=uint8, compu {raw=phys+40 for phys -40..213; unit oC}, update-indication-bit-position=-1  # Battery Temperature Sensor Order26"
          signal BMS_BattTempSensorOrder25: start 7, 8 bit, big-endian, init-value=0, base-type=uint8, compu {raw=phys+40 for phys -40..213; unit oC}, update-indication-bit-position=-1  # Battery Temperature Sensor Order25"
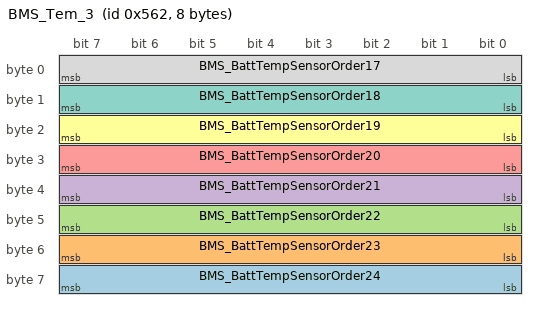
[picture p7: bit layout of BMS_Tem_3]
      frame BMS_Tem_3: id 0x562, from BMS, frame-length=8, can-addressing-mode=STANDARD
        carries pdu BMS_Tem_3: packing-byte-order=big-endian, start-position=7, update-indication-bit-position=-1
        pdu BMS_Tem_3: length=8, transmission-mode-false-timing=cyclic-timing={time-offset=0.0, time-period=1.0}, transmission-mode-true-timing=cyclic-timing={time-offset=0.0, time-period=1.0}
          transmission-mode-conditions:
            {data-filter={data-filter-type=ALWAYS, max=253, min=0}, i-signal-in-i-pdu=BMS_BattTempSensorOrder24}
            {data-filter={data-filter-type=ALWAYS, max=253, min=0}, i-signal-in-i-pdu=BMS_BattTempSensorOrder23}
            {data-filter={data-filter-type=ALWAYS, max=253, min=0}, i-signal-in-i-pdu=BMS_BattTempSensorOrder22}
            {data-filter={data-filter-type=ALWAYS, max=253, min=0}, i-signal-in-i-pdu=BMS_BattTempSensorOrder21}
            {data-filter={data-filter-type=ALWAYS, max=253, min=0}, i-signal-in-i-pdu=BMS_BattTempSensorOrder20}
            {data-filter={data-filter-type=ALWAYS, max=253, min=0}, i-signal-in-i-pdu=BMS_BattTempSensorOrder19}
            {data-filter={data-filter-type=ALWAYS, max=253, min=0}, i-signal-in-i-pdu=BMS_BattTempSensorOrder18}
            {data-filter={data-filter-type=ALWAYS, max=253, min=0}, i-signal-in-i-pdu=BMS_BattTempSensorOrder17}
          signal BMS_BattTempSensorOrder24: start 63, 8 bit, big-endian, init-value=0, base-type=uint8, compu {raw=phys+40 for phys -40..213; unit oC}, update-indication-bit-position=-1  # Battery Temperature Sensor Order24"
          signal BMS_BattTempSensorOrder23: start 55, 8 bit, big-endian, init-value=0, base-type=uint8, compu {raw=phys+40 for phys -40..213; unit oC}, update-indication-bit-position=-1  # Battery Temperature Sensor Order23"
          signal BMS_BattTempSensorOrder22: start 47, 8 bit, big-endian, init-value=0, base-type=uint8, compu {raw=phys+40 for phys -40..213; unit oC}, update-indication-bit-position=-1  # Battery Temperature Sensor Order22"
          signal BMS_BattTempSensorOrder21: start 39, 8 bit, big-endian, init-value=0, base-type=uint8, compu {raw=phys+40 for phys -40..213; unit oC}, update-indication-bit-position=-1  # Battery Temperature Sensor Order21"
          signal BMS_BattTempSensorOrder20: start 31, 8 bit, big-endian, init-value=0, base-type=uint8, compu {raw=phys+40 for phys -40..213; unit oC}, update-indication-bit-position=-1  # Battery Temperature Sensor Order20"
          signal BMS_BattTempSensorOrder19: start 23, 8 bit, big-endian, init-value=0, base-type=uint8, compu {raw=phys+40 for phys -40..213; unit oC}, update-indication-bit-position=-1  # Battery Temperature Sensor Order19"
          signal BMS_BattTempSensorOrder18: start 15, 8 bit, big-endian, init-value=0, base-type=uint8, compu {raw=phys+40 for phys -40..213; unit oC}, update-indication-bit-position=-1  # Battery Temperature Sensor Order18"
          signal BMS_BattTempSensorOrder17: start 7, 8 bit, big-endian, init-value=0, base-type=uint8, compu {raw=phys+40 for phys -40..213; unit oC}, update-indication-bit-position=-1  # Battery Temperature Sensor Order17"
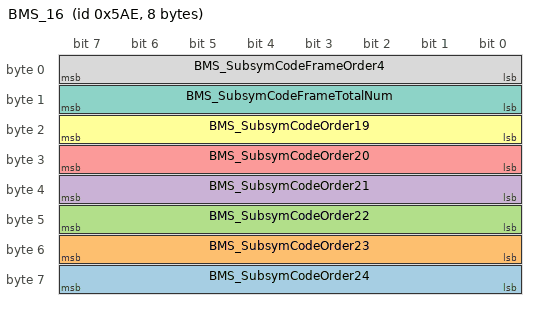
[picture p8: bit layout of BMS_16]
      frame BMS_16: id 0x5AE, from BMS, frame-length=8, can-addressing-mode=STANDARD
        carries pdu BMS_16: packing-byte-order=big-endian, start-position=7, update-indication-bit-position=-1
        pdu BMS_16: length=8, transmission-mode-false-timing=cyclic-timing={time-offset=0.0, time-period=1.0}, transmission-mode-true-timing=cyclic-timing={time-offset=0.0, time-period=1.0}
          transmission-mode-conditions:
            {data-filter={data-filter-type=ALWAYS, max=255, min=0, offset=0}, i-signal-in-i-pdu=BMS_SubsymCodeOrder24}
            {data-filter={data-filter-type=ALWAYS, max=255, min=0, offset=0}, i-signal-in-i-pdu=BMS_SubsymCodeOrder23}
            {data-filter={data-filter-type=ALWAYS, max=255, min=0, offset=0}, i-signal-in-i-pdu=BMS_SubsymCodeOrder22}
            {data-filter={data-filter-type=ALWAYS, max=255, min=0, offset=0}, i-signal-in-i-pdu=BMS_SubsymCodeOrder21}
            {data-filter={data-filter-type=ALWAYS, max=255, min=0, offset=0}, i-signal-in-i-pdu=BMS_SubsymCodeOrder20}
            {data-filter={data-filter-type=ALWAYS, max=255, min=0, offset=0}, i-signal-in-i-pdu=BMS_SubsymCodeOrder19}
            {data-filter={data-filter-type=ALWAYS, max=255, min=0, offset=0}, i-signal-in-i-pdu=BMS_16/BMS_SubsymCodeFrameTotalNum}
            {data-filter={data-filter-type=ALWAYS, max=255, min=0, offset=0}, i-signal-in-i-pdu=BMS_SubsymCodeFrameOrder4}
          signal BMS_SubsymCodeOrder24: start 63, 8 bit, big-endian, init-value=0, base-type=uint8, compu {raw=phys for phys 0..255}, update-indication-bit-position=-1  # Subsym Code number Order24"
          signal BMS_SubsymCodeOrder23: start 55, 8 bit, big-endian, init-value=0, base-type=uint8, compu {raw=phys for phys 0..255}, update-indication-bit-position=-1  # Subsym Code number Order23"
          signal BMS_SubsymCodeOrder22: start 47, 8 bit, big-endian, init-value=0, base-type=uint8, compu {raw=phys for phys 0..255}, update-indication-bit-position=-1  # Subsym Code number Order22"
          signal BMS_SubsymCodeOrder21: start 39, 8 bit, big-endian, init-value=0, base-type=uint8, compu {raw=phys for phys 0..255}, update-indication-bit-position=-1  # Subsym Code number Order21"
          signal BMS_SubsymCodeOrder20: start 31, 8 bit, big-endian, init-value=0, base-type=uint8, compu {raw=phys for phys 0..255}, update-indication-bit-position=-1  # Subsym Code number Order20"
          signal BMS_SubsymCodeOrder19: start 23, 8 bit, big-endian, init-value=0, base-type=uint8, compu {raw=phys for phys 0..255}, update-indication-bit-position=-1  # Subsym Code number Order19"
          signal BMS_SubsymCodeFrameTotalNum: start 15, 8 bit, big-endian, init-value=0, base-type=uint8, compu {raw=phys for phys 0..255}, update-indication-bit-position=-1  # Subsym Code Frame Total Number"
          signal BMS_SubsymCodeFrameOrder4: start 7, 8 bit, big-endian, init-value=0, base-type=uint8, compu {raw=phys for phys 0..255}, update-indication-bit-position=-1  # Subsym Code Frame Order4"
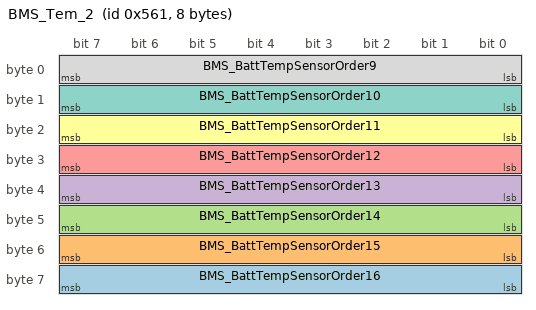
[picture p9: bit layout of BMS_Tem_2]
      frame BMS_Tem_2: id 0x561, from BMS, frame-length=8, can-addressing-mode=STANDARD
        carries pdu BMS_Tem_2: packing-byte-order=big-endian, start-position=7, update-indication-bit-position=-1
        pdu BMS_Tem_2: length=8, transmission-mode-false-timing=cyclic-timing={time-offset=0.0, time-period=1.0}, transmission-mode-true-timing=cyclic-timing={time-offset=0.0, time-period=1.0}
          transmission-mode-conditions:
            {data-filter={data-filter-type=ALWAYS, max=253, min=0}, i-signal-in-i-pdu=BMS_BattTempSensorOrder16}
            {data-filter={data-filter-type=ALWAYS, max=253, min=0}, i-signal-in-i-pdu=BMS_BattTempSensorOrder15}
            {data-filter={data-filter-type=ALWAYS, max=253, min=0}, i-signal-in-i-pdu=BMS_BattTempSensorOrder14}
            {data-filter={data-filter-type=ALWAYS, max=253, min=0}, i-signal-in-i-pdu=BMS_BattTempSensorOrder13}
            {data-filter={data-filter-type=ALWAYS, max=253, min=0}, i-signal-in-i-pdu=BMS_BattTempSensorOrder12}
            {data-filter={data-filter-type=ALWAYS, max=253, min=0}, i-signal-in-i-pdu=BMS_BattTempSensorOrder11}
            {data-filter={data-filter-type=ALWAYS, max=253, min=0}, i-signal-in-i-pdu=BMS_BattTempSensorOrder10}
            {data-filter={data-filter-type=ALWAYS, max=253, min=0}, i-signal-in-i-pdu=BMS_BattTempSensorOrder9}
          signal BMS_BattTempSensorOrder16: start 63, 8 bit, big-endian, init-value=0, base-type=uint8, compu {raw=phys+40 for phys -40..213; unit oC}, update-indication-bit-position=-1  # Battery Temperature Sensor Order16"
          signal BMS_BattTempSensorOrder15: start 55, 8 bit, big-endian, init-value=0, base-type=uint8, compu {raw=phys+40 for phys -40..213; unit oC}, update-indication-bit-position=-1  # Battery Temperature Sensor Order15"
          signal BMS_BattTempSensorOrder14: start 47, 8 bit, big-endian, init-value=0, base-type=uint8, compu {raw=phys+40 for phys -40..213; unit oC}, update-indication-bit-position=-1  # Battery Temperature Sensor Order14"
          signal BMS_BattTempSensorOrder13: start 39, 8 bit, big-endian, init-value=0, base-type=uint8, compu {raw=phys+40 for phys -40..213; unit oC}, update-indication-bit-position=-1  # Battery Temperature Sensor Order13"
          signal BMS_BattTempSensorOrder12: start 31, 8 bit, big-endian, init-value=0, base-type=uint8, compu {raw=phys+40 for phys -40..213; unit oC}, update-indication-bit-position=-1  # Battery Temperature Sensor Order12"
          signal BMS_BattTempSensorOrder11: start 23, 8 bit, big-endian, init-value=0, base-type=uint8, compu {raw=phys+40 for phys -40..213; unit oC}, update-indication-bit-position=-1  # Battery Temperature Sensor Order11"
          signal BMS_BattTempSensorOrder10: start 15, 8 bit, big-endian, init-value=0, base-type=uint8, compu {raw=phys+40 for phys -40..213; unit oC}, update-indication-bit-position=-1  # Battery Temperature Sensor Order10"
          signal BMS_BattTempSensorOrder9: start 7, 8 bit, big-endian, init-value=0, base-type=uint8, compu {raw=phys+40 for phys -40..213; unit oC}, update-indication-bit-position=-1  # Battery Temperature Sensor Order9"
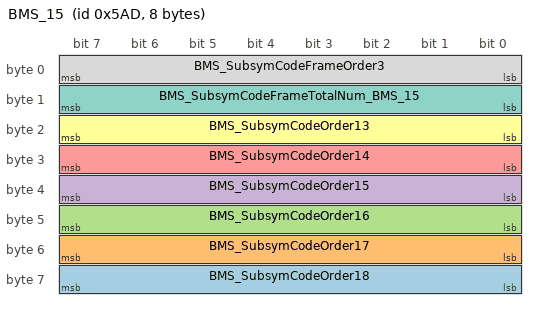
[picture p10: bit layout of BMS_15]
      frame BMS_15: id 0x5AD, from BMS, frame-length=8, can-addressing-mode=STANDARD
        carries pdu BMS_15: packing-byte-order=big-endian, start-position=7, update-indication-bit-position=-1
        pdu BMS_15: length=8, transmission-mode-false-timing=cyclic-timing={time-offset=0.0, time-period=1.0}, transmission-mode-true-timing=cyclic-timing={time-offset=0.0, time-period=1.0}
          transmission-mode-conditions:
            {data-filter={data-filter-type=ALWAYS, max=255, min=0, offset=0}, i-signal-in-i-pdu=BMS_SubsymCodeOrder18}
            {data-filter={data-filter-type=ALWAYS, max=255, min=0, offset=0}, i-signal-in-i-pdu=BMS_SubsymCodeOrder17}
            {data-filter={data-filter-type=ALWAYS, max=255, min=0, offset=0}, i-signal-in-i-pdu=BMS_SubsymCodeOrder16}
            {data-filter={data-filter-type=ALWAYS, max=255, min=0, offset=0}, i-signal-in-i-pdu=BMS_SubsymCodeOrder15}
            {data-filter={data-filter-type=ALWAYS, max=255, min=0, offset=0}, i-signal-in-i-pdu=BMS_SubsymCodeOrder14}
            {data-filter={data-filter-type=ALWAYS, max=255, min=0, offset=0}, i-signal-in-i-pdu=BMS_SubsymCodeOrder13}
            {data-filter={data-filter-type=ALWAYS, max=255, min=0, offset=0}, i-signal-in-i-pdu=BMS_15/BMS_SubsymCodeFrameTotalNum}
            {data-filter={data-filter-type=ALWAYS, max=255, min=0, offset=0}, i-signal-in-i-pdu=BMS_SubsymCodeFrameOrder3}
          signal BMS_SubsymCodeOrder18: start 63, 8 bit, big-endian, init-value=0, base-type=uint8, compu {raw=phys for phys 0..255}, update-indication-bit-position=-1  # Subsym Code number Order18"
          signal BMS_SubsymCodeOrder17: start 55, 8 bit, big-endian, init-value=0, base-type=uint8, compu {raw=phys for phys 0..255}, update-indication-bit-position=-1  # Subsym Code number Order17"
          signal BMS_SubsymCodeOrder16: start 47, 8 bit, big-endian, init-value=0, base-type=uint8, compu {raw=phys for phys 0..255}, update-indication-bit-position=-1  # Subsym Code number Order16"
          signal BMS_SubsymCodeOrder15: start 39, 8 bit, big-endian, init-value=0, base-type=uint8, compu {raw=phys for phys 0..255}, update-indication-bit-position=-1  # Subsym Code number Order15"
          signal BMS_SubsymCodeOrder14: start 31, 8 bit, big-endian, init-value=0, base-type=uint8, compu {raw=phys for phys 0..255}, update-indication-bit-position=-1  # Subsym Code number Order14"
          signal BMS_SubsymCodeOrder13: start 23, 8 bit, big-endian, init-value=0, base-type=uint8, compu {raw=phys for phys 0..255}, update-indication-bit-position=-1  # Subsym Code number Order13"
          signal BMS_SubsymCodeFrameTotalNum_BMS_15: start 15, 8 bit, big-endian, init-value=0, base-type=uint8, compu {raw=phys for phys 0..255}, update-indication-bit-position=-1  # Subsym Code Frame Total Number"
          signal BMS_SubsymCodeFrameOrder3: start 7, 8 bit, big-endian, init-value=0, base-type=uint8, compu {raw=phys for phys 0..255}, update-indication-bit-position=-1  # Subsym Code Frame Order3"
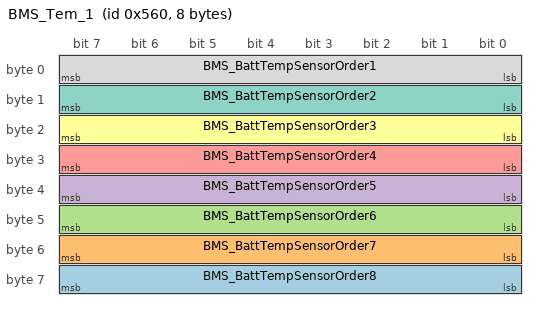
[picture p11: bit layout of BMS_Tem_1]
      frame BMS_Tem_1: id 0x560, from BMS, frame-length=8, can-addressing-mode=STANDARD
        carries pdu BMS_Tem_1: packing-byte-order=big-endian, start-position=7, update-indication-bit-position=-1
        pdu BMS_Tem_1: length=8, transmission-mode-false-timing=cyclic-timing={time-offset=0.0, time-period=1.0}, transmission-mode-true-timing=cyclic-timing={time-offset=0.0, time-period=1.0}
          transmission-mode-conditions:
            {data-filter={data-filter-type=ALWAYS, max=253, min=0}, i-signal-in-i-pdu=BMS_BattTempSensorOrder8}
            {data-filter={data-filter-type=ALWAYS, max=253, min=0}, i-signal-in-i-pdu=BMS_BattTempSensorOrder7}
            {data-filter={data-filter-type=ALWAYS, max=253, min=0}, i-signal-in-i-pdu=BMS_BattTempSensorOrder6}
            {data-filter={data-filter-type=ALWAYS, max=253, min=0}, i-signal-in-i-pdu=BMS_BattTempSensorOrder5}
            {data-filter={data-filter-type=ALWAYS, max=253, min=0}, i-signal-in-i-pdu=BMS_BattTempSensorOrder4}
            {data-filter={data-filter-type=ALWAYS, max=253, min=0}, i-signal-in-i-pdu=BMS_BattTempSensorOrder3}
            {data-filter={data-filter-type=ALWAYS, max=253, min=0}, i-signal-in-i-pdu=BMS_BattTempSensorOrder2}
            {data-filter={data-filter-type=ALWAYS, max=253, min=0}, i-signal-in-i-pdu=BMS_BattTempSensorOrder1}
          signal BMS_BattTempSensorOrder8: start 63, 8 bit, big-endian, init-value=0, base-type=uint8, compu {raw=phys+40 for phys -40..213; unit oC}, update-indication-bit-position=-1  # Battery Temperature Sensor Order8"
          signal BMS_BattTempSensorOrder7: start 55, 8 bit, big-endian, init-value=0, base-type=uint8, compu {raw=phys+40 for phys -40..213; unit oC}, update-indication-bit-position=-1  # Battery Temperature Sensor Order7"
          signal BMS_BattTempSensorOrder6: start 47, 8 bit, big-endian, init-value=0, base-type=uint8, compu {raw=phys+40 for phys -40..213; unit oC}, update-indication-bit-position=-1  # Battery Temperature Sensor Order6"
          signal BMS_BattTempSensorOrder5: start 39, 8 bit, big-endian, init-value=0, base-type=uint8, compu {raw=phys+40 for phys -40..213; unit oC}, update-indication-bit-position=-1  # Battery Temperature Sensor Order5"
          signal BMS_BattTempSensorOrder4: start 31, 8 bit, big-endian, init-value=0, base-type=uint8, compu {raw=phys+40 for phys -40..213; unit oC}, update-indication-bit-position=-1  # Battery Temperature Sensor Order4"
          signal BMS_BattTempSensorOrder3: start 23, 8 bit, big-endian, init-value=0, base-type=uint8, compu {raw=phys+40 for phys -40..213; unit oC}, update-indication-bit-position=-1  # Battery Temperature Sensor Order3"
          signal BMS_BattTempSensorOrder2: start 15, 8 bit, big-endian, init-value=0, base-type=uint8, compu {raw=phys+40 for phys -40..213; unit oC}, update-indication-bit-position=-1  # Battery Temperature Sensor Order2"
          signal BMS_BattTempSensorOrder1: start 7, 8 bit, big-endian, init-value=0, base-type=uint8, compu {raw=phys+40 for phys -40..213; unit oC}, update-indication-bit-position=-1  # Battery Temperature Sensor Order1"
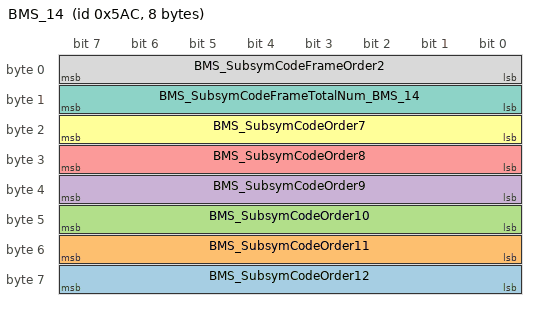
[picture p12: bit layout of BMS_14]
      frame BMS_14: id 0x5AC, from BMS, frame-length=8, can-addressing-mode=STANDARD
        carries pdu BMS_14: packing-byte-order=big-endian, start-position=7, update-indication-bit-position=-1
        pdu BMS_14: length=8, transmission-mode-false-timing=cyclic-timing={time-offset=0.0, time-period=1.0}, transmission-mode-true-timing=cyclic-timing={time-offset=0.0, time-period=1.0}
          transmission-mode-conditions:
            {data-filter={data-filter-type=ALWAYS, max=255, min=0, offset=0}, i-signal-in-i-pdu=BMS_SubsymCodeOrder12}
            {data-filter={data-filter-type=ALWAYS, max=255, min=0, offset=0}, i-signal-in-i-pdu=BMS_SubsymCodeOrder11}
            {data-filter={data-filter-type=ALWAYS, max=255, min=0, offset=0}, i-signal-in-i-pdu=BMS_SubsymCodeOrder10}
            {data-filter={data-filter-type=ALWAYS, max=255, min=0, offset=0}, i-signal-in-i-pdu=BMS_SubsymCodeOrder9}
            {data-filter={data-filter-type=ALWAYS, max=255, min=0, offset=0}, i-signal-in-i-pdu=BMS_SubsymCodeOrder8}
            {data-filter={data-filter-type=ALWAYS, max=255, min=0, offset=0}, i-signal-in-i-pdu=BMS_SubsymCodeOrder7}
            {data-filter={data-filter-type=ALWAYS, max=255, min=0, offset=0}, i-signal-in-i-pdu=BMS_14/BMS_SubsymCodeFrameTotalNum}
            {data-filter={data-filter-type=ALWAYS, max=255, min=0, offset=0}, i-signal-in-i-pdu=BMS_SubsymCodeFrameOrder2}
          signal BMS_SubsymCodeOrder12: start 63, 8 bit, big-endian, init-value=0, base-type=uint8, compu {raw=phys for phys 0..255}, update-indication-bit-position=-1  # Subsym Code number Order12"
          signal BMS_SubsymCodeOrder11: start 55, 8 bit, big-endian, init-value=0, base-type=uint8, compu {raw=phys for phys 0..255}, update-indication-bit-position=-1  # Subsym Code number Order11"
          signal BMS_SubsymCodeOrder10: start 47, 8 bit, big-endian, init-value=0, base-type=uint8, compu {raw=phys for phys 0..255}, update-indication-bit-position=-1  # Subsym Code number Order10"
          signal BMS_SubsymCodeOrder9: start 39, 8 bit, big-endian, init-value=0, base-type=uint8, compu {raw=phys for phys 0..255}, update-indication-bit-position=-1  # Subsym Code number Order9"
          signal BMS_SubsymCodeOrder8: start 31, 8 bit, big-endian, init-value=0, base-type=uint8, compu {raw=phys for phys 0..255}, update-indication-bit-position=-1  # Subsym Code number Order8"
          signal BMS_SubsymCodeOrder7: start 23, 8 bit, big-endian, init-value=0, base-type=uint8, compu {raw=phys for phys 0..255}, update-indication-bit-position=-1  # Subsym Code number Order7"
          signal BMS_SubsymCodeFrameTotalNum_BMS_14: start 15, 8 bit, big-endian, init-value=0, base-type=uint8, compu {raw=phys for phys 0..255}, update-indication-bit-position=-1  # Subsym Code Frame Total Number"
          signal BMS_SubsymCodeFrameOrder2: start 7, 8 bit, big-endian, init-value=0, base-type=uint8, compu {raw=phys for phys 0..255}, update-indication-bit-position=-1  # Subsym Code Frame Order2"
      frame BMS_Vol_9: id 0x548, from BMS, frame-length=8, can-addressing-mode=STANDARD
        carries pdu BMS_Vol_9: packing-byte-order=big-endian, start-position=7, update-indication-bit-position=-1
        pdu BMS_Vol_9: length=8, transmission-mode-false-timing=cyclic-timing={time-offset=0.0, time-period=1.0}, transmission-mode-true-timing=cyclic-timing={time-offset=0.0, time-period=1.0}
          transmission-mode-conditions:
            {data-filter={data-filter-type=NEW-IS-WITHIN, max=5000, min=0, offset=0}, i-signal-in-i-pdu=BMS_BattCellOrder36Vol}
            {data-filter={data-filter-type=NEW-IS-WITHIN, max=5000, min=0, offset=0}, i-signal-in-i-pdu=BMS_BattCellOrder35Vol}
            {data-filter={data-filter-type=NEW-IS-WITHIN, max=5000, min=0, offset=0}, i-signal-in-i-pdu=BMS_BattCellOrder34Vol}
            {data-filter={data-filter-type=NEW-IS-WITHIN, max=5000, min=0, offset=0}, i-signal-in-i-pdu=BMS_BattCellOrder33Vol}
          signal BMS_BattCellOrder36Vol: start 55, 16 bit, big-endian, init-value=0, base-type=uint16, compu {raw=phys for phys 0..5000; unit mV}, update-indication-bit-position=-1  # Battery Cell voltage Order36"
          signal BMS_BattCellOrder35Vol: start 39, 16 bit, big-endian, init-value=0, base-type=uint16, compu {raw=phys for phys 0..5000; unit mV}, update-indication-bit-position=-1  # Battery Cell voltage Order35"
          signal BMS_BattCellOrder34Vol: start 23, 16 bit, big-endian, init-value=0, base-type=uint16, compu {raw=phys for phys 0..5000; unit mV}, update-indication-bit-position=-1  # Battery Cell voltage Order34"
          signal BMS_BattCellOrder33Vol: start 7, 16 bit, big-endian, init-value=0, base-type=uint16, compu {raw=phys for phys 0..5000; unit mV}, update-indication-bit-position=-1  # Battery Cell voltage Order33"
      frame BMS_21: id 0x5C1, from BMS, frame-length=8, can-addressing-mode=STANDARD
        carries pdu BMS_21: packing-byte-order=big-endian, start-position=7, update-indication-bit-position=-1
        pdu BMS_21: length=8, transmission-mode-false-timing=cyclic-timing={time-offset=0.0, time-period=1.0}, transmission-mode-true-timing=cyclic-timing={time-offset=0.0, time-period=1.0}
          transmission-mode-conditions:
            {data-filter={data-filter-type=NEW-IS-WITHIN, max=16777210, min=0, offset=0}, i-signal-in-i-pdu=BMSH_BPTotalDischargeEnergy}
            {data-filter={data-filter-type=NEW-IS-WITHIN, max=1048570, min=0, offset=0}, i-signal-in-i-pdu=BMSH_TotalFeedbackEnergy}
            {data-filter={data-filter-type=NEW-IS-WITHIN, max=1048570, min=0, offset=0}, i-signal-in-i-pdu=BMSH_TotalChargeEnergy}
          signal BMSH_BPTotalDischargeEnergy: start 47, 24 bit, big-endian, init-value=0, base-type=uint32, compu {raw=phys*10 for phys 0..1677721; unit KWH}, update-indication-bit-position=-1  # Battery Pack Total Discharge Energy"
          signal BMSH_TotalFeedbackEnergy: start 19, 20 bit, big-endian, init-value=0, base-type=uint32, compu {raw=phys*10 for phys 0..104857; unit KWH}, update-indication-bit-position=-1  # Total Feedback Energy"
          signal BMSH_TotalChargeEnergy: start 7, 20 bit, big-endian, init-value=0, base-type=uint32, compu {raw=phys*10 for phys 0..104857; unit KWH}, update-indication-bit-position=-1  # Total Charge Energy"
      frame BMS_Vol_8: id 0x547, from BMS, frame-length=8, can-addressing-mode=STANDARD
        carries pdu BMS_Vol_8: packing-byte-order=big-endian, start-position=7, update-indication-bit-position=-1
        pdu BMS_Vol_8: length=8, transmission-mode-false-timing=cyclic-timing={time-offset=0.0, time-period=1.0}, transmission-mode-true-timing=cyclic-timing={time-offset=0.0, time-period=1.0}
          transmission-mode-conditions:
            {data-filter={data-filter-type=NEW-IS-WITHIN, max=5000, min=0, offset=0}, i-signal-in-i-pdu=BMS_BattCellOrder32Vol}
            {data-filter={data-filter-type=NEW-IS-WITHIN, max=5000, min=0, offset=0}, i-signal-in-i-pdu=BMS_BattCellOrder31Vol}
            {data-filter={data-filter-type=NEW-IS-WITHIN, max=5000, min=0, offset=0}, i-signal-in-i-pdu=BMS_BattCellOrder30Vol}
            {data-filter={data-filter-type=NEW-IS-WITHIN, max=5000, min=0, offset=0}, i-signal-in-i-pdu=BMS_BattCellOrder29Vol}
          signal BMS_BattCellOrder32Vol: start 55, 16 bit, big-endian, init-value=0, base-type=uint16, compu {raw=phys for phys 0..5000; unit mV}, update-indication-bit-position=-1  # Battery Cell voltage Order32"
          signal BMS_BattCellOrder31Vol: start 39, 16 bit, big-endian, init-value=0, base-type=uint16, compu {raw=phys for phys 0..5000; unit mV}, update-indication-bit-position=-1  # Battery Cell voltage Order31"
          signal BMS_BattCellOrder30Vol: start 23, 16 bit, big-endian, init-value=0, base-type=uint16, compu {raw=phys for phys 0..5000; unit mV}, update-indication-bit-position=-1  # Battery Cell voltage Order30"
          signal BMS_BattCellOrder29Vol: start 7, 16 bit, big-endian, init-value=0, base-type=uint16, compu {raw=phys for phys 0..5000; unit mV}, update-indication-bit-position=-1  # Battery Cell voltage Order29"
      frame BMS_20: id 0x5C0, from BMS, frame-length=8, can-addressing-mode=STANDARD
        carries pdu BMS_20: packing-byte-order=big-endian, start-position=7, update-indication-bit-position=-1
        pdu BMS_20: length=8, transmission-mode-false-timing=cyclic-timing={time-offset=0.0, time-period=1.0}, transmission-mode-true-timing=cyclic-timing={time-offset=0.0, time-period=1.0}
          transmission-mode-conditions:
            {data-filter={data-filter-type=ALWAYS, max=0, min=0, offset=0}, i-signal-in-i-pdu=BMSH_19_Reserved1}
            {data-filter={data-filter-type=ALWAYS, max=255, min=0, offset=0}, i-signal-in-i-pdu=BMSH_CellSensor_TotalNum}
            {data-filter={data-filter-type=NEW-IS-WITHIN, max=65500, min=0, offset=0}, i-signal-in-i-pdu=BMSH_SingleFeedbackEnergy}
            {data-filter={data-filter-type=NEW-IS-WITHIN, max=65500, min=0, offset=0}, i-signal-in-i-pdu=BMSH_SingleDisChargeEnergy}
            {data-filter={data-filter-type=NEW-IS-WITHIN, max=65500, min=0, offset=0}, i-signal-in-i-pdu=BMSH_SingleChargeEnergy}
          signal BMSH_19_Reserved1: start 63, 8 bit, big-endian, init-value=0, base-type=uint8, compu {raw=phys for phys 0}, update-indication-bit-position=-1
          signal BMSH_CellSensor_TotalNum: start 55, 8 bit, big-endian, init-value=0, base-type=uint8, compu {raw=phys for phys 0..255}, update-indication-bit-position=-1  # Cell voltage Sensor Total Number"
          signal BMSH_SingleFeedbackEnergy: start 39, 16 bit, big-endian, init-value=0, base-type=uint16, compu {raw=phys*100 for phys 0..655; unit KWH}, update-indication-bit-position=-1  # Single Feedback Energy"
          signal BMSH_SingleDisChargeEnergy: start 23, 16 bit, big-endian, init-value=0, base-type=uint16, compu {raw=phys*100 for phys 0..655; unit KWH}, update-indication-bit-position=-1  # Single DisCharge Energy"
          signal BMSH_SingleChargeEnergy: start 7, 16 bit, big-endian, init-value=0, base-type=uint16, compu {raw=phys*100 for phys 0..655; unit KWH}, update-indication-bit-position=-1  # Single Charge Energy"
      frame BMS_Vol_7: id 0x546, from BMS, frame-length=8, can-addressing-mode=STANDARD
        carries pdu BMS_Vol_7: packing-byte-order=big-endian, start-position=7, update-indication-bit-position=-1
        pdu BMS_Vol_7: length=8, transmission-mode-false-timing=cyclic-timing={time-offset=0.0, time-period=1.0}, transmission-mode-true-timing=cyclic-timing={time-offset=0.0, time-period=1.0}
          transmission-mode-conditions:
            {data-filter={data-filter-type=NEW-IS-WITHIN, max=5000, min=0, offset=0}, i-signal-in-i-pdu=BMS_BattCellOrder28Vol}
            {data-filter={data-filter-type=NEW-IS-WITHIN, max=5000, min=0, offset=0}, i-signal-in-i-pdu=BMS_BattCellOrder27Vol}
            {data-filter={data-filter-type=NEW-IS-WITHIN, max=5000, min=0, offset=0}, i-signal-in-i-pdu=BMS_BattCellOrder26Vol}
            {data-filter={data-filter-type=NEW-IS-WITHIN, max=5000, min=0, offset=0}, i-signal-in-i-pdu=BMS_BattCellOrder25Vol}
          signal BMS_BattCellOrder28Vol: start 55, 16 bit, big-endian, init-value=0, base-type=uint16, compu {raw=phys for phys 0..5000; unit mV}, update-indication-bit-position=-1  # Battery Cell voltage Order28"
          signal BMS_BattCellOrder27Vol: start 39, 16 bit, big-endian, init-value=0, base-type=uint16, compu {raw=phys for phys 0..5000; unit mV}, update-indication-bit-position=-1  # Battery Cell voltage Order27"
          signal BMS_BattCellOrder26Vol: start 23, 16 bit, big-endian, init-value=0, base-type=uint16, compu {raw=phys for phys 0..5000; unit mV}, update-indication-bit-position=-1  # Battery Cell voltage Order26"
          signal BMS_BattCellOrder25Vol: start 7, 16 bit, big-endian, init-value=0, base-type=uint16, compu {raw=phys for phys 0..5000; unit mV}, update-indication-bit-position=-1  # Battery Cell voltage Order25"
      frame BMS_Vol_6: id 0x545, from BMS, frame-length=8, can-addressing-mode=STANDARD
        carries pdu BMS_Vol_6: packing-byte-order=big-endian, start-position=7, update-indication-bit-position=-1
        pdu BMS_Vol_6: length=8, transmission-mode-false-timing=cyclic-timing={time-offset=0.0, time-period=1.0}, transmission-mode-true-timing=cyclic-timing={time-offset=0.0, time-period=1.0}
          transmission-mode-conditions:
            {data-filter={data-filter-type=NEW-IS-WITHIN, max=5000, min=0, offset=0}, i-signal-in-i-pdu=BMS_BattCellOrder24Vol}
            {data-filter={data-filter-type=NEW-IS-WITHIN, max=5000, min=0, offset=0}, i-signal-in-i-pdu=BMS_BattCellOrder23Vol}
            {data-filter={data-filter-type=NEW-IS-WITHIN, max=5000, min=0, offset=0}, i-signal-in-i-pdu=BMS_BattCellOrder22Vol}
            {data-filter={data-filter-type=NEW-IS-WITHIN, max=5000, min=0, offset=0}, i-signal-in-i-pdu=BMS_BattCellOrder21Vol}
          signal BMS_BattCellOrder24Vol: start 55, 16 bit, big-endian, init-value=0, base-type=uint16, compu {raw=phys for phys 0..5000; unit mV}, update-indication-bit-position=-1  # Battery Cell voltage Order24"
          signal BMS_BattCellOrder23Vol: start 39, 16 bit, big-endian, init-value=0, base-type=uint16, compu {raw=phys for phys 0..5000; unit mV}, update-indication-bit-position=-1  # Battery Cell voltage Order23"
          signal BMS_BattCellOrder22Vol: start 23, 16 bit, big-endian, init-value=0, base-type=uint16, compu {raw=phys for phys 0..5000; unit mV}, update-indication-bit-position=-1  # Battery Cell voltage Order22"
          signal BMS_BattCellOrder21Vol: start 7, 16 bit, big-endian, init-value=0, base-type=uint16, compu {raw=phys for phys 0..5000; unit mV}, update-indication-bit-position=-1  # Battery Cell voltage Order21"
      frame BMS_Vol_5: id 0x544, from BMS, frame-length=8, can-addressing-mode=STANDARD
        carries pdu BMS_Vol_5: packing-byte-order=big-endian, start-position=7, update-indication-bit-position=-1
        pdu BMS_Vol_5: length=8, transmission-mode-false-timing=cyclic-timing={time-offset=0.0, time-period=1.0}, transmission-mode-true-timing=cyclic-timing={time-offset=0.0, time-period=1.0}
          transmission-mode-conditions:
            {data-filter={data-filter-type=NEW-IS-WITHIN, max=5000, min=0, offset=0}, i-signal-in-i-pdu=BMS_BattCellOrder20Vol}
            {data-filter={data-filter-type=NEW-IS-WITHIN, max=5000, min=0, offset=0}, i-signal-in-i-pdu=BMS_BattCellOrder19Vol}
            {data-filter={data-filter-type=NEW-IS-WITHIN, max=5000, min=0, offset=0}, i-signal-in-i-pdu=BMS_BattCellOrder18Vol}
            {data-filter={data-filter-type=NEW-IS-WITHIN, max=5000, min=0, offset=0}, i-signal-in-i-pdu=BMS_BattCellOrder17Vol}
          signal BMS_BattCellOrder20Vol: start 55, 16 bit, big-endian, init-value=0, base-type=uint16, compu {raw=phys for phys 0..5000; unit mV}, update-indication-bit-position=-1  # Battery Cell voltage Order20"
          signal BMS_BattCellOrder19Vol: start 39, 16 bit, big-endian, init-value=0, base-type=uint16, compu {raw=phys for phys 0..5000; unit mV}, update-indication-bit-position=-1  # Battery Cell voltage Order19"
          signal BMS_BattCellOrder18Vol: start 23, 16 bit, big-endian, init-value=0, base-type=uint16, compu {raw=phys for phys 0..5000; unit mV}, update-indication-bit-position=-1  # Battery Cell voltage Order18"
          signal BMS_BattCellOrder17Vol: start 7, 16 bit, big-endian, init-value=0, base-type=uint16, compu {raw=phys for phys 0..5000; unit mV}, update-indication-bit-position=-1  # Battery Cell voltage Order17"
      frame BMS_Vol_4: id 0x543, from BMS, frame-length=8, can-addressing-mode=STANDARD
        carries pdu BMS_Vol_4: packing-byte-order=big-endian, start-position=7, update-indication-bit-position=-1
        pdu BMS_Vol_4: length=8, transmission-mode-false-timing=cyclic-timing={time-offset=0.0, time-period=1.0}, transmission-mode-true-timing=cyclic-timing={time-offset=0.0, time-period=1.0}
          transmission-mode-conditions:
            {data-filter={data-filter-type=NEW-IS-WITHIN, max=5000, min=0, offset=0}, i-signal-in-i-pdu=BMS_BattCellOrder16Vol}
            {data-filter={data-filter-type=NEW-IS-WITHIN, max=5000, min=0, offset=0}, i-signal-in-i-pdu=BMS_BattCellOrder15Vol}
            {data-filter={data-filter-type=NEW-IS-WITHIN, max=5000, min=0, offset=0}, i-signal-in-i-pdu=BMS_BattCellOrder14Vol}
            {data-filter={data-filter-type=NEW-IS-WITHIN, max=5000, min=0, offset=0}, i-signal-in-i-pdu=BMS_BattCellOrder13Vol}
          signal BMS_BattCellOrder16Vol: start 55, 16 bit, big-endian, init-value=0, base-type=uint16, compu {raw=phys for phys 0..5000; unit mV}, update-indication-bit-position=-1  # Battery Cell voltage Order16"
          signal BMS_BattCellOrder15Vol: start 39, 16 bit, big-endian, init-value=0, base-type=uint16, compu {raw=phys for phys 0..5000; unit mV}, update-indication-bit-position=-1  # Battery Cell voltage Order15"
          signal BMS_BattCellOrder14Vol: start 23, 16 bit, big-endian, init-value=0, base-type=uint16, compu {raw=phys for phys 0..5000; unit mV}, update-indication-bit-position=-1  # Battery Cell voltage Order14"
          signal BMS_BattCellOrder13Vol: start 7, 16 bit, big-endian, init-value=0, base-type=uint16, compu {raw=phys for phys 0..5000; unit mV}, update-indication-bit-position=-1  # Battery Cell voltage Order13"
      frame BMS_Vol_3: id 0x542, from BMS, frame-length=8, can-addressing-mode=STANDARD
        carries pdu BMS_Vol_3: packing-byte-order=big-endian, start-position=7, update-indication-bit-position=-1
        pdu BMS_Vol_3: length=8, transmission-mode-false-timing=cyclic-timing={time-offset=0.0, time-period=1.0}, transmission-mode-true-timing=cyclic-timing={time-offset=0.0, time-period=1.0}
          transmission-mode-conditions:
            {data-filter={data-filter-type=NEW-IS-WITHIN, max=5000, min=0, offset=0}, i-signal-in-i-pdu=BMS_BattCellOrder12Vol}
            {data-filter={data-filter-type=NEW-IS-WITHIN, max=5000, min=0, offset=0}, i-signal-in-i-pdu=BMS_BattCellOrder11Vol}
            {data-filter={data-filter-type=NEW-IS-WITHIN, max=5000, min=0, offset=0}, i-signal-in-i-pdu=BMS_BattCellOrder10Vol}
            {data-filter={data-filter-type=NEW-IS-WITHIN, max=5000, min=0, offset=0}, i-signal-in-i-pdu=BMS_BattCellOrder9Vol}
          signal BMS_BattCellOrder12Vol: start 55, 16 bit, big-endian, init-value=0, base-type=uint16, compu {raw=phys for phys 0..5000; unit mV}, update-indication-bit-position=-1  # Battery Cell voltage Order12"
          signal BMS_BattCellOrder11Vol: start 39, 16 bit, big-endian, init-value=0, base-type=uint16, compu {raw=phys for phys 0..5000; unit mV}, update-indication-bit-position=-1  # Battery Cell voltage Order11"
          signal BMS_BattCellOrder10Vol: start 23, 16 bit, big-endian, init-value=0, base-type=uint16, compu {raw=phys for phys 0..5000; unit mV}, update-indication-bit-position=-1  # Battery Cell voltage Order10"
          signal BMS_BattCellOrder9Vol: start 7, 16 bit, big-endian, init-value=0, base-type=uint16, compu {raw=phys for phys 0..5000; unit mV}, update-indication-bit-position=-1  # Battery Cell voltage Order9"
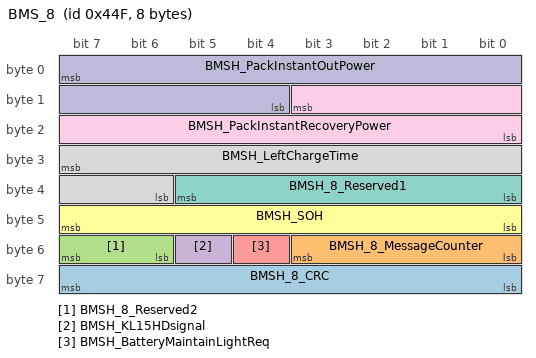
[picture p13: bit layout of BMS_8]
      frame BMS_8: id 0x44F, from BMS, frame-length=8, can-addressing-mode=STANDARD
        carries pdu BMS_8: packing-byte-order=big-endian, start-position=7, update-indication-bit-position=-1
        pdu BMS_8: length=8, transmission-mode-false-timing=cyclic-timing={time-offset=0.0, time-period=0.1}, transmission-mode-true-timing=cyclic-timing={time-offset=0.0, time-period=0.1}
          transmission-mode-conditions:
            {data-filter={data-filter-type=ALWAYS, max=255, min=0, offset=0}, i-signal-in-i-pdu=BMSH_8_CRC}
            {data-filter={data-filter-type=ALWAYS, max=15, min=0, offset=0}, i-signal-in-i-pdu=BMSH_8_MessageCounter}
            {data-filter={data-filter-type=ALWAYS, max=0, min=0, offset=0}, i-signal-in-i-pdu=BMSH_8_Reserved2}
            {data-filter={data-filter-type=ALWAYS, max=1, min=0, offset=0}, i-signal-in-i-pdu=BMSH_KL15HDsignal}
            {data-filter={data-filter-type=ALWAYS, max=1, min=0, offset=0}, i-signal-in-i-pdu=BMSH_BatteryMaintainLightReq}
            {data-filter={data-filter-type=ALWAYS, max=100, min=0, offset=0}, i-signal-in-i-pdu=BMSH_SOH}
            {data-filter={data-filter-type=ALWAYS, max=0, min=0, offset=0}, i-signal-in-i-pdu=BMSH_8_Reserved1}
            {data-filter={data-filter-type=NEW-IS-WITHIN, max=1022, min=0, offset=0}, i-signal-in-i-pdu=BMSH_LeftChargeTime}
            {data-filter={data-filter-type=NEW-IS-WITHIN, max=3200, min=0, offset=0}, i-signal-in-i-pdu=BMSH_PackInstantRecoveryPower}
            {data-filter={data-filter-type=NEW-IS-WITHIN, max=3200, min=0, offset=0}, i-signal-in-i-pdu=BMSH_PackInstantOutPower}
          signal BMSH_8_CRC: start 63, 8 bit, big-endian, init-value=0, base-type=uint8, compu {raw=phys for phys 0..255}, update-indication-bit-position=-1  # SAE J1850 CRC-8"
          signal BMSH_8_MessageCounter: start 51, 4 bit, big-endian, init-value=0, base-type=uint8, compu {raw=phys for phys 0..15}, update-indication-bit-position=-1  # Alivecounter"
          signal BMSH_8_Reserved2: start 55, 2 bit, big-endian, init-value=0, base-type=uint8, compu {raw=phys for phys 0}, update-indication-bit-position=-1
          signal BMSH_KL15HDsignal: start 53, 1 bit, big-endian, init-value=0, base-type=uint8, compu {raw=phys for phys 0..1, 0=BMSKL15OFF, 1=BMSKL15ON}, update-indication-bit-position=-1  # BMS KL15 flag"
          signal BMSH_BatteryMaintainLightReq: start 52, 1 bit, big-endian, init-value=0, base-type=uint8, compu {raw=phys for phys 0..1, 0=NOREQUEST, 1=MAINTAINREQUEST}, update-indication-bit-position=-1  # Battery Maintain Light Request"
          signal BMSH_SOH: start 47, 8 bit, big-endian, init-value=0, base-type=uint8, compu {raw=phys for phys 0..100; unit pct}, update-indication-bit-position=-1  # Battery SOH"
          signal BMSH_8_Reserved1: start 37, 6 bit, big-endian, init-value=0, base-type=uint8, compu {raw=phys for phys 0}, update-indication-bit-position=-1
          signal BMSH_LeftChargeTime: start 31, 10 bit, big-endian, init-value=1022, base-type=uint16, compu {raw=phys for phys 0..1022, 1=CHARGINGMAINTAIN; unit Minute}, update-indication-bit-position=-1  # Left Charge Time 0x1:charging maintain"
          signal BMSH_PackInstantRecoveryPower: start 11, 12 bit, big-endian, init-value=0, base-type=uint16, compu {raw=phys*10 for phys 0..320; unit KW}, update-indication-bit-position=-1  # Pack instantaneous Recovery Power"
          signal BMSH_PackInstantOutPower: start 7, 12 bit, big-endian, init-value=0, base-type=uint16, compu {raw=phys*10 for phys 0..320; unit KW}, update-indication-bit-position=-1  # Pack instantaneous Output Power"
      frame BMS_Vol_2: id 0x541, from BMS, frame-length=8, can-addressing-mode=STANDARD
        carries pdu BMS_Vol_2: packing-byte-order=big-endian, start-position=7, update-indication-bit-position=-1
        pdu BMS_Vol_2: length=8, transmission-mode-false-timing=cyclic-timing={time-offset=0.0, time-period=1.0}, transmission-mode-true-timing=cyclic-timing={time-offset=0.0, time-period=1.0}
          transmission-mode-conditions:
            {data-filter={data-filter-type=NEW-IS-WITHIN, max=5000, min=0, offset=0}, i-signal-in-i-pdu=BMS_BattCellOrder8Vol}
            {data-filter={data-filter-type=NEW-IS-WITHIN, max=5000, min=0, offset=0}, i-signal-in-i-pdu=BMS_BattCellOrder7Vol}
            {data-filter={data-filter-type=NEW-IS-WITHIN, max=5000, min=0, offset=0}, i-signal-in-i-pdu=BMS_BattCellOrder6Vol}
            {data-filter={data-filter-type=NEW-IS-WITHIN, max=5000, min=0, offset=0}, i-signal-in-i-pdu=BMS_BattCellOrder5Vol}
          signal BMS_BattCellOrder8Vol: start 55, 16 bit, big-endian, init-value=0, base-type=uint16, compu {raw=phys for phys 0..5000; unit mV}, update-indication-bit-position=-1  # Battery Cell voltage Order8"
          signal BMS_BattCellOrder7Vol: start 39, 16 bit, big-endian, init-value=0, base-type=uint16, compu {raw=phys for phys 0..5000; unit mV}, update-indication-bit-position=-1  # Battery Cell voltage Order7"
          signal BMS_BattCellOrder6Vol: start 23, 16 bit, big-endian, init-value=0, base-type=uint16, compu {raw=phys for phys 0..5000; unit mV}, update-indication-bit-position=-1  # Battery Cell voltage Order6"
          signal BMS_BattCellOrder5Vol: start 7, 16 bit, big-endian, init-value=0, base-type=uint16, compu {raw=phys for phys 0..5000; unit mV}, update-indication-bit-position=-1  # Battery Cell voltage Order5"
      frame BMS_Vol_1: id 0x540, from BMS, frame-length=8, can-addressing-mode=STANDARD
        carries pdu BMS_Vol_1: packing-byte-order=big-endian, start-position=7, update-indication-bit-position=-1
        pdu BMS_Vol_1: length=8, transmission-mode-false-timing=cyclic-timing={time-offset=0.0, time-period=1.0}, transmission-mode-true-timing=cyclic-timing={time-offset=0.0, time-period=1.0}
          transmission-mode-conditions:
            {data-filter={data-filter-type=NEW-IS-WITHIN, max=5000, min=0, offset=0}, i-signal-in-i-pdu=BMS_BattCellOrder4Vol}
            {data-filter={data-filter-type=NEW-IS-WITHIN, max=5000, min=0, offset=0}, i-signal-in-i-pdu=BMS_BattCellOrder3Vol}
            {data-filter={data-filter-type=NEW-IS-WITHIN, max=5000, min=0, offset=0}, i-signal-in-i-pdu=BMS_BattCellOrder2Vol}
            {data-filter={data-filter-type=NEW-IS-WITHIN, max=5000, min=0, offset=0}, i-signal-in-i-pdu=BMS_BattCellOrder1Vol}
          signal BMS_BattCellOrder4Vol: start 55, 16 bit, big-endian, init-value=0, base-type=uint16, compu {raw=phys for phys 0..5000; unit mV}, update-indication-bit-position=-1  # Battery Cell voltage Order4"
          signal BMS_BattCellOrder3Vol: start 39, 16 bit, big-endian, init-value=0, base-type=uint16, compu {raw=phys for phys 0..5000; unit mV}, update-indication-bit-position=-1  # Battery Cell voltage Order3"
          signal BMS_BattCellOrder2Vol: start 23, 16 bit, big-endian, init-value=0, base-type=uint16, compu {raw=phys for phys 0..5000; unit mV}, update-indication-bit-position=-1  # Battery Cell voltage Order2"
          signal BMS_BattCellOrder1Vol: start 7, 16 bit, big-endian, init-value=0, base-type=uint16, compu {raw=phys for phys 0..5000; unit mV}, update-indication-bit-position=-1  # Battery Cell voltage Order1"
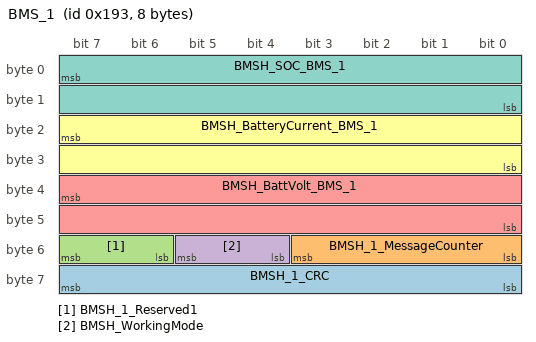
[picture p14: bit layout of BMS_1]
      frame BMS_1: id 0x193, from BMS, frame-length=8, can-addressing-mode=STANDARD
        carries pdu BMS_1: packing-byte-order=big-endian, start-position=7, update-indication-bit-position=-1
        pdu BMS_1: length=8, transmission-mode-false-timing=cyclic-timing={time-offset=0.0, time-period=0.01}, transmission-mode-true-timing=cyclic-timing={time-offset=0.0, time-period=0.01}
          transmission-mode-conditions:
            {data-filter={data-filter-type=ALWAYS, max=255, min=0, offset=0}, i-signal-in-i-pdu=BMSH_1_CRC}
            {data-filter={data-filter-type=ALWAYS, max=15, min=0, offset=0}, i-signal-in-i-pdu=BMSH_1_MessageCounter}
            {data-filter={data-filter-type=ALWAYS, max=0, min=0, offset=0}, i-signal-in-i-pdu=BMSH_1_Reserved1}
            {data-filter={data-filter-type=ALWAYS, max=3, min=0, offset=0}, i-signal-in-i-pdu=BMSH_WorkingMode}
            {data-filter={data-filter-type=NEW-IS-WITHIN, max=20000, min=0, offset=0}, i-signal-in-i-pdu=BMS_1/BMSH_BattVolt}
            {data-filter={data-filter-type=NEW-IS-WITHIN, max=44000, min=20000}, i-signal-in-i-pdu=BMS_1/BMSH_BatteryCurrent}
            {data-filter={data-filter-type=NEW-IS-WITHIN, max=10000, min=0, offset=0}, i-signal-in-i-pdu=BMS_1/BMSH_SOC}
          signal BMSH_1_CRC: start 63, 8 bit, big-endian, init-value=0, base-type=uint8, compu {raw=phys for phys 0..255}, update-indication-bit-position=-1  # SAE J1850 CRC-8"
          signal BMSH_1_MessageCounter: start 51, 4 bit, big-endian, init-value=0, base-type=uint8, compu {raw=phys for phys 0..15}, update-indication-bit-position=-1  # Alivecounter"
          signal BMSH_1_Reserved1: start 55, 2 bit, big-endian, init-value=0, base-type=uint8, compu {raw=phys for phys 0}, update-indication-bit-position=-1
          signal BMSH_WorkingMode: start 53, 2 bit, big-endian, init-value=0, base-type=uint8, compu-method=CompuMethod_BMSH_WorkingMode, update-indication-bit-position=-1  # Working Mode"
          signal BMSH_BattVolt_BMS_1: start 39, 16 bit, big-endian, init-value=0, base-type=uint16, compu {raw=phys*20 for phys 0..1000; unit V}, update-indication-bit-position=-1  # Battery voltage"
          signal BMSH_BatteryCurrent_BMS_1: start 23, 16 bit, big-endian, init-value=32000, base-type=uint16, compu {raw=phys*20+32000 for phys -600..600; unit Ampere}, update-indication-bit-position=-1  # Battery Current"
          signal BMSH_SOC_BMS_1: start 7, 16 bit, big-endian, init-value=0, base-type=uint16, compu {raw=phys*100 for phys 0..100; unit pct}, update-indication-bit-position=-1  # State of charge"
      frame BMS_Vol_20: id 0x553, from BMS, frame-length=8, can-addressing-mode=STANDARD
        carries pdu BMS_Vol_20: packing-byte-order=big-endian, start-position=7, update-indication-bit-position=-1
        pdu BMS_Vol_20: length=8, transmission-mode-false-timing=cyclic-timing={time-offset=0.0, time-period=1.0}, transmission-mode-true-timing=cyclic-timing={time-offset=0.0, time-period=1.0}
          transmission-mode-conditions:
            {data-filter={data-filter-type=NEW-IS-WITHIN, max=5000, min=0, offset=0}, i-signal-in-i-pdu=BMS_BattCellOrder80Vol}
            {data-filter={data-filter-type=NEW-IS-WITHIN, max=5000, min=0, offset=0}, i-signal-in-i-pdu=BMS_BattCellOrder79Vol}
            {data-filter={data-filter-type=NEW-IS-WITHIN, max=5000, min=0, offset=0}, i-signal-in-i-pdu=BMS_BattCellOrder78Vol}
            {data-filter={data-filter-type=NEW-IS-WITHIN, max=5000, min=0, offset=0}, i-signal-in-i-pdu=BMS_BattCellOrder77Vol}
          signal BMS_BattCellOrder80Vol: start 55, 16 bit, big-endian, init-value=0, base-type=uint16, compu {raw=phys for phys 0..5000; unit mV}, update-indication-bit-position=-1  # Battery Cell voltage Order80"
          signal BMS_BattCellOrder79Vol: start 39, 16 bit, big-endian, init-value=0, base-type=uint16, compu {raw=phys for phys 0..5000; unit mV}, update-indication-bit-position=-1  # Battery Cell voltage Order79"
          signal BMS_BattCellOrder78Vol: start 23, 16 bit, big-endian, init-value=0, base-type=uint16, compu {raw=phys for phys 0..5000; unit mV}, update-indication-bit-position=-1  # Battery Cell voltage Order78"
          signal BMS_BattCellOrder77Vol: start 7, 16 bit, big-endian, init-value=0, base-type=uint16, compu {raw=phys for phys 0..5000; unit mV}, update-indication-bit-position=-1  # Battery Cell voltage Order77"
      frame BMS_Vol_19: id 0x552, from BMS, frame-length=8, can-addressing-mode=STANDARD
        carries pdu BMS_Vol_19: packing-byte-order=big-endian, start-position=7, update-indication-bit-position=-1
        pdu BMS_Vol_19: length=8, transmission-mode-false-timing=cyclic-timing={time-offset=0.0, time-period=1.0}, transmission-mode-true-timing=cyclic-timing={time-offset=0.0, time-period=1.0}
          transmission-mode-conditions:
            {data-filter={data-filter-type=NEW-IS-WITHIN, max=5000, min=0, offset=0}, i-signal-in-i-pdu=BMS_BattCellOrder76Vol}
            {data-filter={data-filter-type=NEW-IS-WITHIN, max=5000, min=0, offset=0}, i-signal-in-i-pdu=BMS_BattCellOrder75Vol}
            {data-filter={data-filter-type=NEW-IS-WITHIN, max=5000, min=0, offset=0}, i-signal-in-i-pdu=BMS_BattCellOrder74Vol}
            {data-filter={data-filter-type=NEW-IS-WITHIN, max=5000, min=0, offset=0}, i-signal-in-i-pdu=BMS_BattCellOrder73Vol}
          signal BMS_BattCellOrder76Vol: start 55, 16 bit, big-endian, init-value=0, base-type=uint16, compu {raw=phys for phys 0..5000; unit mV}, update-indication-bit-position=-1  # Battery Cell voltage Order76"
          signal BMS_BattCellOrder75Vol: start 39, 16 bit, big-endian, init-value=0, base-type=uint16, compu {raw=phys for phys 0..5000; unit mV}, update-indication-bit-position=-1  # Battery Cell voltage Order75"
          signal BMS_BattCellOrder74Vol: start 23, 16 bit, big-endian, init-value=0, base-type=uint16, compu {raw=phys for phys 0..5000; unit mV}, update-indication-bit-position=-1  # Battery Cell voltage Order74"
          signal BMS_BattCellOrder73Vol: start 7, 16 bit, big-endian, init-value=0, base-type=uint16, compu {raw=phys for phys 0..5000; unit mV}, update-indication-bit-position=-1  # Battery Cell voltage Order73"
      frame BMS_Vol_18: id 0x551, from BMS, frame-length=8, can-addressing-mode=STANDARD
        carries pdu BMS_Vol_18: packing-byte-order=big-endian, start-position=7, update-indication-bit-position=-1
        pdu BMS_Vol_18: length=8, transmission-mode-false-timing=cyclic-timing={time-offset=0.0, time-period=1.0}, transmission-mode-true-timing=cyclic-timing={time-offset=0.0, time-period=1.0}
          transmission-mode-conditions:
            {data-filter={data-filter-type=NEW-IS-WITHIN, max=5000, min=0, offset=0}, i-signal-in-i-pdu=BMS_BattCellOrder72Vol}
            {data-filter={data-filter-type=NEW-IS-WITHIN, max=5000, min=0, offset=0}, i-signal-in-i-pdu=BMS_BattCellOrder71Vol}
            {data-filter={data-filter-type=NEW-IS-WITHIN, max=5000, min=0, offset=0}, i-signal-in-i-pdu=BMS_BattCellOrder70Vol}
            {data-filter={data-filter-type=NEW-IS-WITHIN, max=5000, min=0, offset=0}, i-signal-in-i-pdu=BMS_BattCellOrder69Vol}
          signal BMS_BattCellOrder72Vol: start 55, 16 bit, big-endian, init-value=0, base-type=uint16, compu {raw=phys for phys 0..5000; unit mV}, update-indication-bit-position=-1  # Battery Cell voltage Order72"
          signal BMS_BattCellOrder71Vol: start 39, 16 bit, big-endian, init-value=0, base-type=uint16, compu {raw=phys for phys 0..5000; unit mV}, update-indication-bit-position=-1  # Battery Cell voltage Order71"
          signal BMS_BattCellOrder70Vol: start 23, 16 bit, big-endian, init-value=0, base-type=uint16, compu {raw=phys for phys 0..5000; unit mV}, update-indication-bit-position=-1  # Battery Cell voltage Order70"
          signal BMS_BattCellOrder69Vol: start 7, 16 bit, big-endian, init-value=0, base-type=uint16, compu {raw=phys for phys 0..5000; unit mV}, update-indication-bit-position=-1  # Battery Cell voltage Order69"
      frame BMS_Vol_17: id 0x550, from BMS, frame-length=8, can-addressing-mode=STANDARD
        carries pdu BMS_Vol_17: packing-byte-order=big-endian, start-position=7, update-indication-bit-position=-1
        pdu BMS_Vol_17: length=8, transmission-mode-false-timing=cyclic-timing={time-offset=0.0, time-period=1.0}, transmission-mode-true-timing=cyclic-timing={time-offset=0.0, time-period=1.0}
          transmission-mode-conditions:
            {data-filter={data-filter-type=NEW-IS-WITHIN, max=5000, min=0, offset=0}, i-signal-in-i-pdu=BMS_BattCellOrder68Vol}
            {data-filter={data-filter-type=NEW-IS-WITHIN, max=5000, min=0, offset=0}, i-signal-in-i-pdu=BMS_BattCellOrder67Vol}
            {data-filter={data-filter-type=NEW-IS-WITHIN, max=5000, min=0, offset=0}, i-signal-in-i-pdu=BMS_BattCellOrder66Vol}
            {data-filter={data-filter-type=NEW-IS-WITHIN, max=5000, min=0, offset=0}, i-signal-in-i-pdu=BMS_BattCellOrder65Vol}
          signal BMS_BattCellOrder68Vol: start 55, 16 bit, big-endian, init-value=0, base-type=uint16, compu {raw=phys for phys 0..5000; unit mV}, update-indication-bit-position=-1  # Battery Cell voltage Order68"
          signal BMS_BattCellOrder67Vol: start 39, 16 bit, big-endian, init-value=0, base-type=uint16, compu {raw=phys for phys 0..5000; unit mV}, update-indication-bit-position=-1  # Battery Cell voltage Order67"
          signal BMS_BattCellOrder66Vol: start 23, 16 bit, big-endian, init-value=0, base-type=uint16, compu {raw=phys for phys 0..5000; unit mV}, update-indication-bit-position=-1  # Battery Cell voltage Order66"
          signal BMS_BattCellOrder65Vol: start 7, 16 bit, big-endian, init-value=0, base-type=uint16, compu {raw=phys for phys 0..5000; unit mV}, update-indication-bit-position=-1  # Battery Cell voltage Order65"
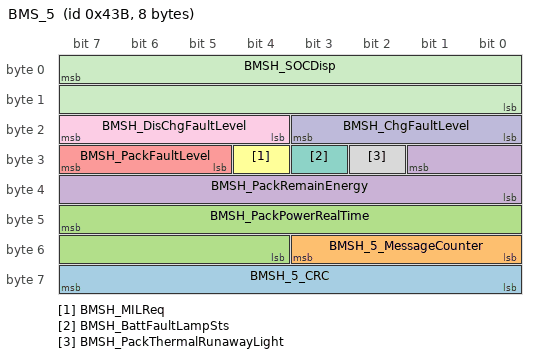
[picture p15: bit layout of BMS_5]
      frame BMS_5: id 0x43B, from BMS, frame-length=8, can-addressing-mode=STANDARD
        carries pdu BMS_5: packing-byte-order=big-endian, start-position=7, update-indication-bit-position=-1
        pdu BMS_5: length=8, transmission-mode-false-timing=cyclic-timing={time-offset=0.0, time-period=0.1}, transmission-mode-true-timing=cyclic-timing={time-offset=0.0, time-period=0.1}
          transmission-mode-conditions:
            {data-filter={data-filter-type=ALWAYS, max=255, min=0, offset=0}, i-signal-in-i-pdu=BMSH_5_CRC}
            {data-filter={data-filter-type=ALWAYS, max=15, min=0, offset=0}, i-signal-in-i-pdu=BMSH_5_MessageCounter}
            {data-filter={data-filter-type=NEW-IS-WITHIN, max=2400, min=1600}, i-signal-in-i-pdu=BMSH_PackPowerRealTime}
            {data-filter={data-filter-type=NEW-IS-WITHIN, max=1000, min=0, offset=0}, i-signal-in-i-pdu=BMSH_PackRemainEnergy}
            {data-filter={data-filter-type=ALWAYS, max=7, min=0, offset=0}, i-signal-in-i-pdu=BMSH_PackFaultLevel}
            {data-filter={data-filter-type=ALWAYS, max=1, min=0, offset=0}, i-signal-in-i-pdu=BMSH_MILReq}
            {data-filter={data-filter-type=ALWAYS, max=1, min=0, offset=0}, i-signal-in-i-pdu=BMSH_BattFaultLampSts}
            {data-filter={data-filter-type=ALWAYS, max=1, min=0, offset=0}, i-signal-in-i-pdu=BMSH_PackThermalRunawayLight}
            {data-filter={data-filter-type=ALWAYS, max=15, min=0, offset=0}, i-signal-in-i-pdu=BMSH_DisChgFaultLevel}
            {data-filter={data-filter-type=ALWAYS, max=15, min=0, offset=0}, i-signal-in-i-pdu=BMSH_ChgFaultLevel}
            {data-filter={data-filter-type=NEW-IS-WITHIN, max=10000, min=0, offset=0}, i-signal-in-i-pdu=BMSH_SOCDisp}
          signal BMSH_5_CRC: start 63, 8 bit, big-endian, init-value=0, base-type=uint8, compu {raw=phys for phys 0..255}, update-indication-bit-position=-1  # SAE J1850 CRC-8"
          signal BMSH_5_MessageCounter: start 51, 4 bit, big-endian, init-value=0, base-type=uint8, compu {raw=phys for phys 0..15}, update-indication-bit-position=-1  # Alivecounter"
          signal BMSH_PackPowerRealTime: start 47, 12 bit, big-endian, init-value=2000, base-type=uint16, compu {raw=phys+2000 for phys -400..400; unit Kw}, update-indication-bit-position=-1  # Pack Power RealTime"
          signal BMSH_PackRemainEnergy: start 25, 10 bit, big-endian, init-value=0, base-type=uint16, compu {raw=phys*10 for phys 0..100; unit KwH}, update-indication-bit-position=-1  # Pack Remain Energy"
          signal BMSH_PackFaultLevel: start 31, 3 bit, big-endian, init-value=0, base-type=uint8, compu-method=CompuMethod_BMSH_PackFaultLevel, update-indication-bit-position=-1  # Pack Fault Level"
          signal BMSH_MILReq: start 28, 1 bit, big-endian, init-value=0, base-type=uint8, compu {raw=phys for phys 0..1, 0=INACTIVE, 1=ACTIVE}, update-indication-bit-position=-1  # MIL request"
          signal BMSH_BattFaultLampSts: start 27, 1 bit, big-endian, init-value=0, base-type=uint8, compu {raw=phys for phys 0..1, 0=LAMPOFF, 1=LAMPON}, update-indication-bit-position=-1  # Battery system Fault Lamp Status"
          signal BMSH_PackThermalRunawayLight: start 26, 1 bit, big-endian, init-value=0, base-type=uint8, compu {raw=phys for phys 0..1, 0=LAMPOFF, 1=LAMPON}, update-indication-bit-position=-1  # Pack Thermal Runaway Light"
          signal BMSH_DisChgFaultLevel: start 23, 4 bit, big-endian, init-value=0, base-type=uint8, compu-method=CompuMethod_BMSH_DisChgFaultLevel, update-indication-bit-position=-1  # DisCharge Fault Level"
          signal BMSH_ChgFaultLevel: start 19, 4 bit, big-endian, init-value=0, base-type=uint8, compu-method=CompuMethod_BMSH_ChgFaultLevel, update-indication-bit-position=-1  # Charge Fault Level"
          signal BMSH_SOCDisp: start 7, 16 bit, big-endian, init-value=0, base-type=uint16, compu {raw=phys*100 for phys 0..100; unit pct}, update-indication-bit-position=-1  # SOC display"
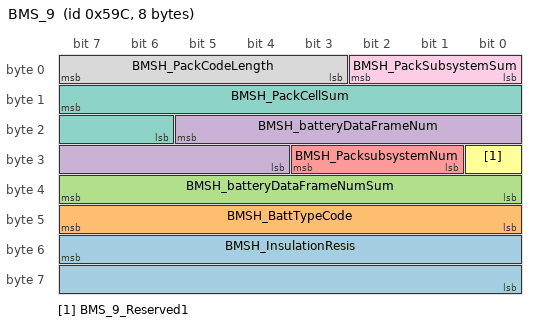
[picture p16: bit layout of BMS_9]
      frame BMS_9: id 0x59C, from BMS, frame-length=8, can-addressing-mode=STANDARD
        carries pdu BMS_9: packing-byte-order=big-endian, start-position=7, update-indication-bit-position=-1
        pdu BMS_9: length=8, transmission-mode-false-timing=cyclic-timing={time-offset=0.0, time-period=1.0}, transmission-mode-true-timing=cyclic-timing={time-offset=0.0, time-period=1.0}
          transmission-mode-conditions:
            {data-filter={data-filter-type=NEW-IS-WITHIN, max=6553, min=0, offset=0}, i-signal-in-i-pdu=BMSH_InsulationResis}
            {data-filter={data-filter-type=ALWAYS, max=255, min=0, offset=0}, i-signal-in-i-pdu=BMSH_BattTypeCode}
            {data-filter={data-filter-type=ALWAYS, max=255, min=0, offset=0}, i-signal-in-i-pdu=BMSH_batteryDataFrameNumSum}
            {data-filter={data-filter-type=NEW-IS-WITHIN, max=1023, min=0, offset=0}, i-signal-in-i-pdu=BMSH_batteryDataFrameNum}
            {data-filter={data-filter-type=ALWAYS, max=7, min=0, offset=0}, i-signal-in-i-pdu=BMSH_PacksubsystemNum}
            {data-filter={data-filter-type=ALWAYS, max=0, min=0, offset=0}, i-signal-in-i-pdu=BMS_9_Reserved1}
            {data-filter={data-filter-type=NEW-IS-WITHIN, max=1023, min=0, offset=0}, i-signal-in-i-pdu=BMSH_PackCellSum}
            {data-filter={data-filter-type=ALWAYS, max=31, min=0, offset=0}, i-signal-in-i-pdu=BMSH_PackCodeLength}
            {data-filter={data-filter-type=ALWAYS, max=7, min=0, offset=0}, i-signal-in-i-pdu=BMSH_PackSubsystemSum}
          signal BMSH_InsulationResis: start 55, 16 bit, big-endian, init-value=0, base-type=uint16, compu {raw=phys*0.1 for phys 0..65533; unit k}, update-indication-bit-position=-1  # Insulation Resistance"
          signal BMSH_BattTypeCode: start 47, 8 bit, big-endian, init-value=0, base-type=uint8, compu-method=CompuMethod_BMSH_BattTypeCode, update-indication-bit-position=-1  # Batt Type Code"
          signal BMSH_batteryDataFrameNumSum: start 39, 8 bit, big-endian, init-value=0, base-type=uint8, compu {raw=phys for phys 0..255}, update-indication-bit-position=-1  # battery Data Frame Number Sum"
          signal BMSH_batteryDataFrameNum: start 21, 10 bit, big-endian, init-value=0, base-type=uint16, compu {raw=phys for phys 0..1023}, update-indication-bit-position=-1  # battery DataFrame Number"
          signal BMSH_PacksubsystemNum: start 27, 3 bit, big-endian, init-value=0, base-type=uint8, compu {raw=phys for phys 0..7}, update-indication-bit-position=-1  # Pack subsystem Number"
          signal BMS_9_Reserved1: start 24, 1 bit, big-endian, init-value=0, base-type=uint8, compu {raw=phys for phys 0}, update-indication-bit-position=-1
          signal BMSH_PackCellSum: start 15, 10 bit, big-endian, init-value=0, base-type=uint16, compu {raw=phys for phys 0..1023}, update-indication-bit-position=-1  # Pack Cell Sum"
          signal BMSH_PackCodeLength: start 7, 5 bit, big-endian, init-value=0, base-type=uint8, compu {raw=phys for phys 0..31}, update-indication-bit-position=-1  # Pack Code Length"
          signal BMSH_PackSubsystemSum: start 2, 3 bit, big-endian, init-value=0, base-type=uint8, compu {raw=phys for phys 0..7}, update-indication-bit-position=-1  # Pack Subsystem Sum"
      frame BMS_Vol_16: id 0x54F, from BMS, frame-length=8, can-addressing-mode=STANDARD
        carries pdu BMS_Vol_16: packing-byte-order=big-endian, start-position=7, update-indication-bit-position=-1
        pdu BMS_Vol_16: length=8, transmission-mode-false-timing=cyclic-timing={time-offset=0.0, time-period=1.0}, transmission-mode-true-timing=cyclic-timing={time-offset=0.0, time-period=1.0}
          transmission-mode-conditions:
            {data-filter={data-filter-type=NEW-IS-WITHIN, max=5000, min=0, offset=0}, i-signal-in-i-pdu=BMS_BattCellOrder64Vol}
            {data-filter={data-filter-type=NEW-IS-WITHIN, max=5000, min=0, offset=0}, i-signal-in-i-pdu=BMS_BattCellOrder63Vol}
            {data-filter={data-filter-type=NEW-IS-WITHIN, max=5000, min=0, offset=0}, i-signal-in-i-pdu=BMS_BattCellOrder62Vol}
            {data-filter={data-filter-type=NEW-IS-WITHIN, max=5000, min=0, offset=0}, i-signal-in-i-pdu=BMS_BattCellOrder61Vol}
          signal BMS_BattCellOrder64Vol: start 55, 16 bit, big-endian, init-value=0, base-type=uint16, compu {raw=phys for phys 0..5000; unit mV}, update-indication-bit-position=-1  # Battery Cell voltage Order64"
          signal BMS_BattCellOrder63Vol: start 39, 16 bit, big-endian, init-value=0, base-type=uint16, compu {raw=phys for phys 0..5000; unit mV}, update-indication-bit-position=-1  # Battery Cell voltage Order63"
          signal BMS_BattCellOrder62Vol: start 23, 16 bit, big-endian, init-value=0, base-type=uint16, compu {raw=phys for phys 0..5000; unit mV}, update-indication-bit-position=-1  # Battery Cell voltage Order62"
          signal BMS_BattCellOrder61Vol: start 7, 16 bit, big-endian, init-value=0, base-type=uint16, compu {raw=phys for phys 0..5000; unit mV}, update-indication-bit-position=-1  # Battery Cell voltage Order61"
      frame BMS_Vol_15: id 0x54E, from BMS, frame-length=8, can-addressing-mode=STANDARD
        carries pdu BMS_Vol_15: packing-byte-order=big-endian, start-position=7, update-indication-bit-position=-1
        pdu BMS_Vol_15: length=8, transmission-mode-false-timing=cyclic-timing={time-offset=0.0, time-period=1.0}, transmission-mode-true-timing=cyclic-timing={time-offset=0.0, time-period=1.0}
          transmission-mode-conditions:
            {data-filter={data-filter-type=NEW-IS-WITHIN, max=5000, min=0, offset=0}, i-signal-in-i-pdu=BMS_BattCellOrder60Vol}
            {data-filter={data-filter-type=NEW-IS-WITHIN, max=5000, min=0, offset=0}, i-signal-in-i-pdu=BMS_BattCellOrder59Vol}
            {data-filter={data-filter-type=NEW-IS-WITHIN, max=5000, min=0, offset=0}, i-signal-in-i-pdu=BMS_BattCellOrder58Vol}
            {data-filter={data-filter-type=NEW-IS-WITHIN, max=5000, min=0, offset=0}, i-signal-in-i-pdu=BMS_BattCellOrder57Vol}
          signal BMS_BattCellOrder60Vol: start 55, 16 bit, big-endian, init-value=0, base-type=uint16, compu {raw=phys for phys 0..5000; unit mV}, update-indication-bit-position=-1  # Battery Cell voltage Order60"
          signal BMS_BattCellOrder59Vol: start 39, 16 bit, big-endian, init-value=0, base-type=uint16, compu {raw=phys for phys 0..5000; unit mV}, update-indication-bit-position=-1  # Battery Cell voltage Order59"
          signal BMS_BattCellOrder58Vol: start 23, 16 bit, big-endian, init-value=0, base-type=uint16, compu {raw=phys for phys 0..5000; unit mV}, update-indication-bit-position=-1  # Battery Cell voltage Order58"
          signal BMS_BattCellOrder57Vol: start 7, 16 bit, big-endian, init-value=0, base-type=uint16, compu {raw=phys for phys 0..5000; unit mV}, update-indication-bit-position=-1  # Battery Cell voltage Order57"
      frame BMS_Vol_14: id 0x54D, from BMS, frame-length=8, can-addressing-mode=STANDARD
        carries pdu BMS_Vol_14: packing-byte-order=big-endian, start-position=7, update-indication-bit-position=-1
        pdu BMS_Vol_14: length=8, transmission-mode-false-timing=cyclic-timing={time-offset=0.0, time-period=1.0}, transmission-mode-true-timing=cyclic-timing={time-offset=0.0, time-period=1.0}
          transmission-mode-conditions:
            {data-filter={data-filter-type=NEW-IS-WITHIN, max=5000, min=0, offset=0}, i-signal-in-i-pdu=BMS_BattCellOrder56Vol}
            {data-filter={data-filter-type=NEW-IS-WITHIN, max=5000, min=0, offset=0}, i-signal-in-i-pdu=BMS_BattCellOrder55Vol}
            {data-filter={data-filter-type=NEW-IS-WITHIN, max=5000, min=0, offset=0}, i-signal-in-i-pdu=BMS_BattCellOrder54Vol}
            {data-filter={data-filter-type=NEW-IS-WITHIN, max=5000, min=0, offset=0}, i-signal-in-i-pdu=BMS_BattCellOrder53Vol}
          signal BMS_BattCellOrder56Vol: start 55, 16 bit, big-endian, init-value=0, base-type=uint16, compu {raw=phys for phys 0..5000; unit mV}, update-indication-bit-position=-1  # Battery Cell voltage Order56"
          signal BMS_BattCellOrder55Vol: start 39, 16 bit, big-endian, init-value=0, base-type=uint16, compu {raw=phys for phys 0..5000; unit mV}, update-indication-bit-position=-1  # Battery Cell voltage Order55"
          signal BMS_BattCellOrder54Vol: start 23, 16 bit, big-endian, init-value=0, base-type=uint16, compu {raw=phys for phys 0..5000; unit mV}, update-indication-bit-position=-1  # Battery Cell voltage Order54"
          signal BMS_BattCellOrder53Vol: start 7, 16 bit, big-endian, init-value=0, base-type=uint16, compu {raw=phys for phys 0..5000; unit mV}, update-indication-bit-position=-1  # Battery Cell voltage Order53"
      frame BMS_2: id 0x19B, from BMS, frame-length=8, can-addressing-mode=STANDARD
        carries pdu BMS_2: packing-byte-order=big-endian, start-position=7, update-indication-bit-position=-1
        pdu BMS_2: length=8, transmission-mode-false-timing=cyclic-timing={time-offset=0.0, time-period=0.01}, transmission-mode-true-timing=cyclic-timing={time-offset=0.0, time-period=0.01}
          transmission-mode-conditions:
            {data-filter={data-filter-type=ALWAYS, max=255, min=0, offset=0}, i-signal-in-i-pdu=BMSH_2_CRC}
            {data-filter={data-filter-type=ALWAYS, max=15, min=0, offset=0}, i-signal-in-i-pdu=BMSH_2_MessageCounter}
            {data-filter={data-filter-type=ALWAYS, max=1, min=0, offset=0}, i-signal-in-i-pdu=BMSH_BookSetReq}
            {data-filter={data-filter-type=ALWAYS, max=1, min=0, offset=0}, i-signal-in-i-pdu=BMSH_PTCRelayWeldSts}
            {data-filter={data-filter-type=ALWAYS, max=1, min=0, offset=0}, i-signal-in-i-pdu=BMSH_CHGPrechargeWeldSts}
            {data-filter={data-filter-type=ALWAYS, max=1, min=0, offset=0}, i-signal-in-i-pdu=BMSH_PreChargeWeldSts}
            {data-filter={data-filter-type=ALWAYS, max=1, min=0, offset=0}, i-signal-in-i-pdu=BMSH_NegSideWeldSts}
            {data-filter={data-filter-type=ALWAYS, max=1, min=0, offset=0}, i-signal-in-i-pdu=BMS_2/BMSH_PosSideWeldSts}
            {data-filter={data-filter-type=ALWAYS, max=1, min=0, offset=0}, i-signal-in-i-pdu=BMSH_PTCRelaySts}
            {data-filter={data-filter-type=ALWAYS, max=1, min=0, offset=0}, i-signal-in-i-pdu=BMSH_CHGPrechargeRelaySts}
            {data-filter={data-filter-type=ALWAYS, max=1, min=0, offset=0}, i-signal-in-i-pdu=BMSH_PrechargeRelaySts}
            {data-filter={data-filter-type=ALWAYS, max=1, min=0, offset=0}, i-signal-in-i-pdu=BMSH_NegMainRelaySts}
            {data-filter={data-filter-type=ALWAYS, max=1, min=0, offset=0}, i-signal-in-i-pdu=BMSH_PosMainRelaySts}
            {data-filter={data-filter-type=ALWAYS, max=1, min=0, offset=0}, i-signal-in-i-pdu=BMSH_IntelligentChargeReq}
            {data-filter={data-filter-type=ALWAYS, max=7, min=0, offset=0}, i-signal-in-i-pdu=BMSH_OBCPrechgSt}
            {data-filter={data-filter-type=ALWAYS, max=7, min=0, offset=0}, i-signal-in-i-pdu=BMSH_MainPrechgSt}
            {data-filter={data-filter-type=ALWAYS, max=3, min=0, offset=0}, i-signal-in-i-pdu=BMS_2/BMSH_InsulationSts}
            {data-filter={data-filter-type=ALWAYS, max=3, min=0, offset=0}, i-signal-in-i-pdu=BMSH_VehicleHVILSts}
            {data-filter={data-filter-type=ALWAYS, max=3, min=0, offset=0}, i-signal-in-i-pdu=BMS_2/BMSH_InterHVILSts}
            {data-filter={data-filter-type=ALWAYS, max=15, min=0, offset=0}, i-signal-in-i-pdu=BMS_2/BMSH_stMode}
            {data-filter={data-filter-type=ALWAYS, max=100, min=0, offset=0}, i-signal-in-i-pdu=Reserved_BMSH_SOH}
            {data-filter={data-filter-type=NEW-IS-WITHIN, max=20000, min=0, offset=0}, i-signal-in-i-pdu=BMSH_HVBusVolt}
          signal BMSH_2_CRC: start 63, 8 bit, big-endian, init-value=0, base-type=uint8, compu {raw=phys for phys 0..255}, update-indication-bit-position=-1  # SAE J1850 CRC-8"
          signal BMSH_2_MessageCounter: start 51, 4 bit, big-endian, init-value=0, base-type=uint8, compu {raw=phys for phys 0..15}, update-indication-bit-position=-1  # Alivecounter"
          signal BMSH_BookSetReq: start 55, 1 bit, big-endian, init-value=0, base-type=uint8, compu {raw=phys for phys 0..1, 0=NOREQUEST, 1=REQUEST}, update-indication-bit-position=-1  # Book charge Set Request"
          signal BMSH_PTCRelayWeldSts: start 54, 1 bit, big-endian, init-value=0, base-type=uint8, compu {raw=phys for phys 0..1, 0=NOWELDED, 1=WELDED}, update-indication-bit-position=-1  # PTC Relay Weld Sts"
          signal BMSH_CHGPrechargeWeldSts: start 53, 1 bit, big-endian, init-value=0, base-type=uint8, compu {raw=phys for phys 0..1, 0=NOWELDED, 1=WELDED}, update-indication-bit-position=-1  # charge Precharge Weld Status"
          signal BMSH_PreChargeWeldSts: start 52, 1 bit, big-endian, init-value=0, base-type=uint8, compu {raw=phys for phys 0..1, 0=NOWELDED, 1=WELDED}, update-indication-bit-position=-1  # main precharge Weld Status"
          signal BMSH_NegSideWeldSts: start 47, 1 bit, big-endian, init-value=0, base-type=uint8, compu {raw=phys for phys 0..1, 0=NOWELDED, 1=WELDED}, update-indication-bit-position=-1  # main negtive Side Weld Status"
          signal BMSH_PosSideWeldSts_BMS_2: start 46, 1 bit, big-endian, init-value=0, base-type=uint8, compu {raw=phys for phys 0..1, 0=NOWELDED, 1=WELDED}, update-indication-bit-position=-1  # main Positive Side Weld Status"
          signal BMSH_PTCRelaySts: start 45, 1 bit, big-endian, init-value=0, base-type=uint8, compu {raw=phys for phys 0..1, 0=OPEN, 1=CLOSED}, update-indication-bit-position=-1  # PTC Relay Sts"
          signal BMSH_CHGPrechargeRelaySts: start 44, 1 bit, big-endian, init-value=0, base-type=uint8, compu {raw=phys for phys 0..1, 0=OPEN, 1=CLOSED}, update-indication-bit-position=-1  # charge precharge relay status"
          signal BMSH_PrechargeRelaySts: start 43, 1 bit, big-endian, init-value=0, base-type=uint8, compu {raw=phys for phys 0..1, 0=OPEN, 1=CLOSED}, update-indication-bit-position=-1  # main precharge relay status"
          signal BMSH_NegMainRelaySts: start 42, 1 bit, big-endian, init-value=0, base-type=uint8, compu {raw=phys for phys 0..1, 0=OPEN, 1=CLOSED}, update-indication-bit-position=-1  # main negtive relay status"
          signal BMSH_PosMainRelaySts: start 41, 1 bit, big-endian, init-value=0, base-type=uint8, compu {raw=phys for phys 0..1, 0=OPEN, 1=CLOSED}, update-indication-bit-position=-1  # main positive relay status"
          signal BMSH_IntelligentChargeReq: start 40, 1 bit, big-endian, init-value=0, base-type=uint8, compu {raw=phys for phys 0..1, 0=NOREQUEST_DEFAULT_, 1=REQUEST}, update-indication-bit-position=-1  # 12V Battery Intelligent Charge Request"
          signal BMSH_OBCPrechgSt: start 39, 3 bit, big-endian, init-value=0, base-type=uint8, compu-method=CompuMethod_BMSH_OBCPrechgSt, update-indication-bit-position=-1  # OBC precharge status"
          signal BMSH_MainPrechgSt: start 36, 3 bit, big-endian, init-value=0, base-type=uint8, compu-method=CompuMethod_BMSH_MainPrechgSt, update-indication-bit-position=-1  # main precharge status"
          signal BMSH_InsulationSts_BMS_2: start 33, 2 bit, big-endian, init-value=0, base-type=uint8, compu-method=CompuMethod_BMSH_InsulationSts_BMS_2, update-indication-bit-position=-1  # HV Insulation Status"
          signal BMSH_VehicleHVILSts: start 31, 2 bit, big-endian, init-value=0, base-type=uint8, compu-method=CompuMethod_BMSH_VehicleHVILSts, update-indication-bit-position=-1  # Vehicle HV interlock Status"
          signal BMSH_InterHVILSts_BMS_2: start 29, 2 bit, big-endian, init-value=0, base-type=uint8, compu-method=CompuMethod_BMSH_InterHVILSts_BMS_2, update-indication-bit-position=-1  # Inter HV interlock Status"
          signal BMSH_stMode_BMS_2: start 27, 4 bit, big-endian, init-value=0, base-type=uint8, compu-method=CompuMethod_BMSH_stMode_BMS_2, update-indication-bit-position=-1  # state mode"
          signal Reserved_BMSH_SOH: start 23, 8 bit, big-endian, init-value=0, base-type=uint8, compu {raw=phys for phys 0..100; unit pct}, update-indication-bit-position=-1  # Battery of health"
          signal BMSH_HVBusVolt: start 7, 16 bit, big-endian, init-value=0, base-type=uint16, compu {raw=phys*20 for phys 0..1000; unit V}, update-indication-bit-position=-1  # HV Bus Voltage"
      frame BMS_Vol_13: id 0x54C, from BMS, frame-length=8, can-addressing-mode=STANDARD
        carries pdu BMS_Vol_13: packing-byte-order=big-endian, start-position=7, update-indication-bit-position=-1
        pdu BMS_Vol_13: length=8, transmission-mode-false-timing=cyclic-timing={time-offset=0.0, time-period=1.0}, transmission-mode-true-timing=cyclic-timing={time-offset=0.0, time-period=1.0}
          transmission-mode-conditions:
            {data-filter={data-filter-type=NEW-IS-WITHIN, max=5000, min=0, offset=0}, i-signal-in-i-pdu=BMS_BattCellOrder52Vol}
            {data-filter={data-filter-type=NEW-IS-WITHIN, max=5000, min=0, offset=0}, i-signal-in-i-pdu=BMS_BattCellOrder51Vol}
            {data-filter={data-filter-type=NEW-IS-WITHIN, max=5000, min=0, offset=0}, i-signal-in-i-pdu=BMS_BattCellOrder50Vol}
            {data-filter={data-filter-type=NEW-IS-WITHIN, max=5000, min=0, offset=0}, i-signal-in-i-pdu=BMS_BattCellOrder49Vol}
          signal BMS_BattCellOrder52Vol: start 55, 16 bit, big-endian, init-value=0, base-type=uint16, compu {raw=phys for phys 0..5000; unit mV}, update-indication-bit-position=-1  # Battery Cell voltage Order52"
          signal BMS_BattCellOrder51Vol: start 39, 16 bit, big-endian, init-value=0, base-type=uint16, compu {raw=phys for phys 0..5000; unit mV}, update-indication-bit-position=-1  # Battery Cell voltage Order51"
          signal BMS_BattCellOrder50Vol: start 23, 16 bit, big-endian, init-value=0, base-type=uint16, compu {raw=phys for phys 0..5000; unit mV}, update-indication-bit-position=-1  # Battery Cell voltage Order50"
          signal BMS_BattCellOrder49Vol: start 7, 16 bit, big-endian, init-value=0, base-type=uint16, compu {raw=phys for phys 0..5000; unit mV}, update-indication-bit-position=-1  # Battery Cell voltage Order49"
      frame BMS_Vol_12: id 0x54B, from BMS, frame-length=8, can-addressing-mode=STANDARD
        carries pdu BMS_Vol_12: packing-byte-order=big-endian, start-position=7, update-indication-bit-position=-1
        pdu BMS_Vol_12: length=8, transmission-mode-false-timing=cyclic-timing={time-offset=0.0, time-period=1.0}, transmission-mode-true-timing=cyclic-timing={time-offset=0.0, time-period=1.0}
          transmission-mode-conditions:
            {data-filter={data-filter-type=NEW-IS-WITHIN, max=5000, min=0, offset=0}, i-signal-in-i-pdu=BMS_BattCellOrder48Vol}
            {data-filter={data-filter-type=NEW-IS-WITHIN, max=5000, min=0, offset=0}, i-signal-in-i-pdu=BMS_BattCellOrder47Vol}
            {data-filter={data-filter-type=NEW-IS-WITHIN, max=5000, min=0, offset=0}, i-signal-in-i-pdu=BMS_BattCellOrder46Vol}
            {data-filter={data-filter-type=NEW-IS-WITHIN, max=5000, min=0, offset=0}, i-signal-in-i-pdu=BMS_BattCellOrder45Vol}
          signal BMS_BattCellOrder48Vol: start 55, 16 bit, big-endian, init-value=0, base-type=uint16, compu {raw=phys for phys 0..5000; unit mV}, update-indication-bit-position=-1  # Battery Cell voltage Order48"
          signal BMS_BattCellOrder47Vol: start 39, 16 bit, big-endian, init-value=0, base-type=uint16, compu {raw=phys for phys 0..5000; unit mV}, update-indication-bit-position=-1  # Battery Cell voltage Order47"
          signal BMS_BattCellOrder46Vol: start 23, 16 bit, big-endian, init-value=0, base-type=uint16, compu {raw=phys for phys 0..5000; unit mV}, update-indication-bit-position=-1  # Battery Cell voltage Order46"
          signal BMS_BattCellOrder45Vol: start 7, 16 bit, big-endian, init-value=0, base-type=uint16, compu {raw=phys for phys 0..5000; unit mV}, update-indication-bit-position=-1  # Battery Cell voltage Order45"
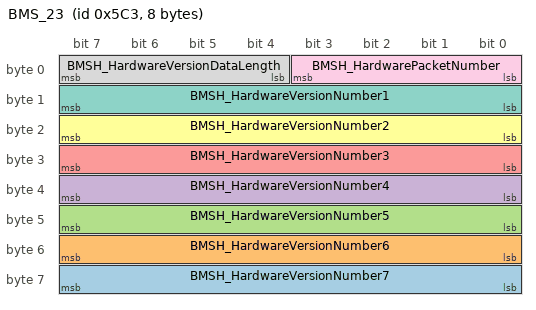
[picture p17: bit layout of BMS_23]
      frame BMS_23: id 0x5C3, from BMS, frame-length=8, can-addressing-mode=STANDARD
        carries pdu BMS_23: packing-byte-order=big-endian, start-position=7, update-indication-bit-position=-1
        pdu BMS_23: length=8, transmission-mode-false-timing=cyclic-timing={time-offset=0.0, time-period=1.0}, transmission-mode-true-timing=cyclic-timing={time-offset=0.0, time-period=1.0}
          transmission-mode-conditions:
            {data-filter={data-filter-type=ALWAYS, max=255, min=0, offset=0}, i-signal-in-i-pdu=BMSH_HardwareVersionNumber7}
            {data-filter={data-filter-type=ALWAYS, max=255, min=0, offset=0}, i-signal-in-i-pdu=BMSH_HardwareVersionNumber6}
            {data-filter={data-filter-type=ALWAYS, max=255, min=0, offset=0}, i-signal-in-i-pdu=BMSH_HardwareVersionNumber5}
            {data-filter={data-filter-type=ALWAYS, max=255, min=0, offset=0}, i-signal-in-i-pdu=BMSH_HardwareVersionNumber4}
            {data-filter={data-filter-type=ALWAYS, max=255, min=0, offset=0}, i-signal-in-i-pdu=BMSH_HardwareVersionNumber3}
            {data-filter={data-filter-type=ALWAYS, max=255, min=0, offset=0}, i-signal-in-i-pdu=BMSH_HardwareVersionNumber2}
            {data-filter={data-filter-type=ALWAYS, max=255, min=0, offset=0}, i-signal-in-i-pdu=BMSH_HardwareVersionNumber1}
            {data-filter={data-filter-type=ALWAYS, max=15, min=0, offset=0}, i-signal-in-i-pdu=BMSH_HardwareVersionDataLength}
            {data-filter={data-filter-type=ALWAYS, max=15, min=0, offset=0}, i-signal-in-i-pdu=BMSH_HardwarePacketNumber}
          signal BMSH_HardwareVersionNumber7: start 63, 8 bit, big-endian, init-value=0, base-type=uint8, compu {raw=phys for phys 0..255}, update-indication-bit-position=-1  # Hardware Version Number7 ASCII code"
          signal BMSH_HardwareVersionNumber6: start 55, 8 bit, big-endian, init-value=0, base-type=uint8, compu {raw=phys for phys 0..255}, update-indication-bit-position=-1  # Hardware Version Number6 ASCII code"
          signal BMSH_HardwareVersionNumber5: start 47, 8 bit, big-endian, init-value=0, base-type=uint8, compu {raw=phys for phys 0..255}, update-indication-bit-position=-1  # Hardware Version Number5 ASCII code"
          signal BMSH_HardwareVersionNumber4: start 39, 8 bit, big-endian, init-value=0, base-type=uint8, compu {raw=phys for phys 0..255}, update-indication-bit-position=-1  # Hardware Version Number4 ASCII code"
          signal BMSH_HardwareVersionNumber3: start 31, 8 bit, big-endian, init-value=0, base-type=uint8, compu {raw=phys for phys 0..255}, update-indication-bit-position=-1  # Hardware Version Number3 ASCII code"
          signal BMSH_HardwareVersionNumber2: start 23, 8 bit, big-endian, init-value=0, base-type=uint8, compu {raw=phys for phys 0..255}, update-indication-bit-position=-1  # Hardware Version Number2 ASCII code"
          signal BMSH_HardwareVersionNumber1: start 15, 8 bit, big-endian, init-value=0, base-type=uint8, compu {raw=phys for phys 0..255}, update-indication-bit-position=-1  # Hardware Version Number1 ASCII code"
          signal BMSH_HardwareVersionDataLength: start 7, 4 bit, big-endian, init-value=0, base-type=uint8, compu {raw=phys for phys 0..15}, update-indication-bit-position=-1  # Hardware Version Data Length"
          signal BMSH_HardwarePacketNumber: start 3, 4 bit, big-endian, init-value=0, base-type=uint8, compu {raw=phys for phys 0..15}, update-indication-bit-position=-1  # Hardware Packet Number"
      frame BMS_Vol_11: id 0x54A, from BMS, frame-length=8, can-addressing-mode=STANDARD
        carries pdu BMS_Vol_11: packing-byte-order=big-endian, start-position=7, update-indication-bit-position=-1
        pdu BMS_Vol_11: length=8, transmission-mode-false-timing=cyclic-timing={time-offset=0.0, time-period=1.0}, transmission-mode-true-timing=cyclic-timing={time-offset=0.0, time-period=1.0}
          transmission-mode-conditions:
            {data-filter={data-filter-type=NEW-IS-WITHIN, max=5000, min=0, offset=0}, i-signal-in-i-pdu=BMS_BattCellOrder44Vol}
            {data-filter={data-filter-type=NEW-IS-WITHIN, max=5000, min=0, offset=0}, i-signal-in-i-pdu=BMS_BattCellOrder43Vol}
            {data-filter={data-filter-type=NEW-IS-WITHIN, max=5000, min=0, offset=0}, i-signal-in-i-pdu=BMS_BattCellOrder42Vol}
            {data-filter={data-filter-type=NEW-IS-WITHIN, max=5000, min=0, offset=0}, i-signal-in-i-pdu=BMS_BattCellOrder41Vol}
          signal BMS_BattCellOrder44Vol: start 55, 16 bit, big-endian, init-value=0, base-type=uint16, compu {raw=phys for phys 0..5000; unit mV}, update-indication-bit-position=-1  # Battery Cell voltage Order44"
          signal BMS_BattCellOrder43Vol: start 39, 16 bit, big-endian, init-value=0, base-type=uint16, compu {raw=phys for phys 0..5000; unit mV}, update-indication-bit-position=-1  # Battery Cell voltage Order43"
          signal BMS_BattCellOrder42Vol: start 23, 16 bit, big-endian, init-value=0, base-type=uint16, compu {raw=phys for phys 0..5000; unit mV}, update-indication-bit-position=-1  # Battery Cell voltage Order42"
          signal BMS_BattCellOrder41Vol: start 7, 16 bit, big-endian, init-value=0, base-type=uint16, compu {raw=phys for phys 0..5000; unit mV}, update-indication-bit-position=-1  # Battery Cell voltage Order41"
      frame BMS_25: id 0x4AF, from BMS, frame-length=8, can-addressing-mode=STANDARD
        carries pdu BMS_25: packing-byte-order=big-endian, start-position=7, update-indication-bit-position=-1
        pdu BMS_25: length=8, transmission-mode-false-timing=cyclic-timing={time-offset=0.0, time-period=0.1}, transmission-mode-true-timing=cyclic-timing={time-offset=0.0, time-period=0.1}
          transmission-mode-conditions:
            {data-filter={data-filter-type=NEW-IS-WITHIN, max=0, min=0, offset=0}, i-signal-in-i-pdu=BMS_25_Reserved1}
            {data-filter={data-filter-type=ALWAYS, max=254, min=0, offset=0}, i-signal-in-i-pdu=BMSH_SelfHeatPowerReq}
            {data-filter={data-filter-type=NEW-IS-WITHIN, max=3000, min=0}, i-signal-in-i-pdu=BMSH_OBDBattTempAvg}
            {data-filter={data-filter-type=NEW-IS-WITHIN, max=20000, min=0, offset=0}, i-signal-in-i-pdu=BMSH_HVV4Volt}
            {data-filter={data-filter-type=NEW-IS-WITHIN, max=20000, min=0, offset=0}, i-signal-in-i-pdu=BMSH_HVV3Volt}
          signal BMS_25_Reserved1: start 51, 12 bit, big-endian, init-value=0, base-type=uint16, compu {raw=phys for phys 0}, update-indication-bit-position=-1
          signal BMSH_SelfHeatPowerReq: start 43, 8 bit, big-endian, init-value=0, base-type=uint8, compu {raw=phys*25 for phys 0..10.16; unit kw}, update-indication-bit-position=-1  # BMS Self_Heat Power Request"
          signal BMSH_OBDBattTempAvg: start 39, 12 bit, big-endian, init-value=1500, base-type=uint16, compu {raw=phys*10+1500 for phys -150..150; unit oC}, update-indication-bit-position=-1  # OBD Battery Temperature Average"
          signal BMSH_HVV4Volt: start 23, 16 bit, big-endian, init-value=0, base-type=uint16, compu {raw=phys*20 for phys 0..1000; unit V}, update-indication-bit-position=-1  # HV V4 Voltage"
          signal BMSH_HVV3Volt: start 7, 16 bit, big-endian, init-value=0, base-type=uint16, compu {raw=phys*20 for phys 0..1000; unit V}, update-indication-bit-position=-1  # HV V3 Voltage"
      frame BMS_Vol_10: id 0x549, from BMS, frame-length=8, can-addressing-mode=STANDARD
        carries pdu BMS_Vol_10: packing-byte-order=big-endian, start-position=7, update-indication-bit-position=-1
        pdu BMS_Vol_10: length=8, transmission-mode-false-timing=cyclic-timing={time-offset=0.0, time-period=1.0}, transmission-mode-true-timing=cyclic-timing={time-offset=0.0, time-period=1.0}
          transmission-mode-conditions:
            {data-filter={data-filter-type=NEW-IS-WITHIN, max=5000, min=0, offset=0}, i-signal-in-i-pdu=BMS_BattCellOrder40Vol}
            {data-filter={data-filter-type=NEW-IS-WITHIN, max=5000, min=0, offset=0}, i-signal-in-i-pdu=BMS_BattCellOrder39Vol}
            {data-filter={data-filter-type=NEW-IS-WITHIN, max=5000, min=0, offset=0}, i-signal-in-i-pdu=BMS_BattCellOrder38Vol}
            {data-filter={data-filter-type=NEW-IS-WITHIN, max=5000, min=0, offset=0}, i-signal-in-i-pdu=BMS_BattCellOrder37Vol}
          signal BMS_BattCellOrder40Vol: start 55, 16 bit, big-endian, init-value=0, base-type=uint16, compu {raw=phys for phys 0..5000; unit mV}, update-indication-bit-position=-1  # Battery Cell voltage Order40"
          signal BMS_BattCellOrder39Vol: start 39, 16 bit, big-endian, init-value=0, base-type=uint16, compu {raw=phys for phys 0..5000; unit mV}, update-indication-bit-position=-1  # Battery Cell voltage Order39"
          signal BMS_BattCellOrder38Vol: start 23, 16 bit, big-endian, init-value=0, base-type=uint16, compu {raw=phys for phys 0..5000; unit mV}, update-indication-bit-position=-1  # Battery Cell voltage Order38"
          signal BMS_BattCellOrder37Vol: start 7, 16 bit, big-endian, init-value=0, base-type=uint16, compu {raw=phys for phys 0..5000; unit mV}, update-indication-bit-position=-1  # Battery Cell voltage Order37"
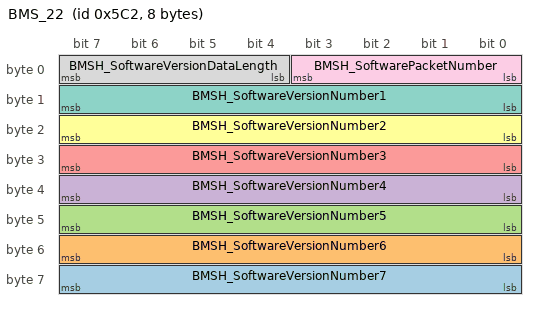
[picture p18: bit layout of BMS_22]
      frame BMS_22: id 0x5C2, from BMS, frame-length=8, can-addressing-mode=STANDARD
        carries pdu BMS_22: packing-byte-order=big-endian, start-position=7, update-indication-bit-position=-1
        pdu BMS_22: length=8, transmission-mode-false-timing=cyclic-timing={time-offset=0.0, time-period=1.0}, transmission-mode-true-timing=cyclic-timing={time-offset=0.0, time-period=1.0}
          transmission-mode-conditions:
            {data-filter={data-filter-type=ALWAYS, max=255, min=0, offset=0}, i-signal-in-i-pdu=BMSH_SoftwareVersionNumber7}
            {data-filter={data-filter-type=ALWAYS, max=255, min=0, offset=0}, i-signal-in-i-pdu=BMSH_SoftwareVersionNumber6}
            {data-filter={data-filter-type=ALWAYS, max=255, min=0, offset=0}, i-signal-in-i-pdu=BMSH_SoftwareVersionNumber5}
            {data-filter={data-filter-type=ALWAYS, max=255, min=0, offset=0}, i-signal-in-i-pdu=BMSH_SoftwareVersionNumber4}
            {data-filter={data-filter-type=ALWAYS, max=255, min=0, offset=0}, i-signal-in-i-pdu=BMSH_SoftwareVersionNumber3}
            {data-filter={data-filter-type=ALWAYS, max=255, min=0, offset=0}, i-signal-in-i-pdu=BMSH_SoftwareVersionNumber2}
            {data-filter={data-filter-type=ALWAYS, max=255, min=0, offset=0}, i-signal-in-i-pdu=BMSH_SoftwareVersionNumber1}
            {data-filter={data-filter-type=ALWAYS, max=15, min=0, offset=0}, i-signal-in-i-pdu=BMSH_SoftwareVersionDataLength}
            {data-filter={data-filter-type=ALWAYS, max=15, min=0, offset=0}, i-signal-in-i-pdu=BMSH_SoftwarePacketNumber}
          signal BMSH_SoftwareVersionNumber7: start 63, 8 bit, big-endian, init-value=0, base-type=uint8, compu {raw=phys for phys 0..255}, update-indication-bit-position=-1  # Software Version Number7 ASCII code"
          signal BMSH_SoftwareVersionNumber6: start 55, 8 bit, big-endian, init-value=0, base-type=uint8, compu {raw=phys for phys 0..255}, update-indication-bit-position=-1  # Software Version Number6 ASCII code"
          signal BMSH_SoftwareVersionNumber5: start 47, 8 bit, big-endian, init-value=0, base-type=uint8, compu {raw=phys for phys 0..255}, update-indication-bit-position=-1  # Software Version Number5 ASCII code"
          signal BMSH_SoftwareVersionNumber4: start 39, 8 bit, big-endian, init-value=0, base-type=uint8, compu {raw=phys for phys 0..255}, update-indication-bit-position=-1  # Software Version Number4 ASCII code"
          signal BMSH_SoftwareVersionNumber3: start 31, 8 bit, big-endian, init-value=0, base-type=uint8, compu {raw=phys for phys 0..255}, update-indication-bit-position=-1  # Software Version Number3 ASCII code"
          signal BMSH_SoftwareVersionNumber2: start 23, 8 bit, big-endian, init-value=0, base-type=uint8, compu {raw=phys for phys 0..255}, update-indication-bit-position=-1  # Software Version Number2 ASCII code"
          signal BMSH_SoftwareVersionNumber1: start 15, 8 bit, big-endian, init-value=0, base-type=uint8, compu {raw=phys for phys 0..255}, update-indication-bit-position=-1  # Software Version Number1 ASCII code"
          signal BMSH_SoftwareVersionDataLength: start 7, 4 bit, big-endian, init-value=0, base-type=uint8, compu {raw=phys for phys 0..15}, update-indication-bit-position=-1  # Software Version Data Length"
          signal BMSH_SoftwarePacketNumber: start 3, 4 bit, big-endian, init-value=0, base-type=uint8, compu {raw=phys for phys 0..15}, update-indication-bit-position=-1  # Software Packet Number"
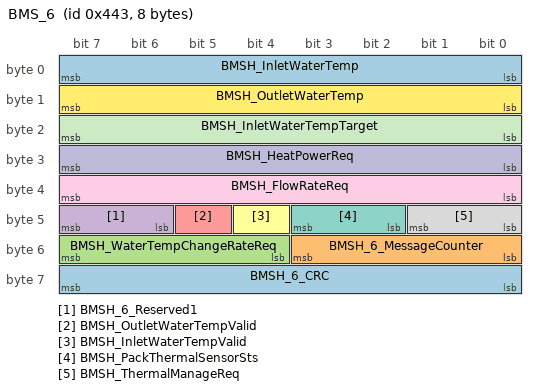
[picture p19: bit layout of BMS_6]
      frame BMS_6: id 0x443, from BMS, frame-length=8, can-addressing-mode=STANDARD
        carries pdu BMS_6: packing-byte-order=big-endian, start-position=7, update-indication-bit-position=-1
        pdu BMS_6: length=8, transmission-mode-false-timing=cyclic-timing={time-offset=0.0, time-period=0.1}, transmission-mode-true-timing=cyclic-timing={time-offset=0.0, time-period=0.1}
          transmission-mode-conditions:
            {data-filter={data-filter-type=ALWAYS, max=255, min=0, offset=0}, i-signal-in-i-pdu=BMSH_6_CRC}
            {data-filter={data-filter-type=ALWAYS, max=15, min=0, offset=0}, i-signal-in-i-pdu=BMSH_6_MessageCounter}
            {data-filter={data-filter-type=ALWAYS, max=15, min=0, offset=0}, i-signal-in-i-pdu=BMSH_WaterTempChangeRateReq}
            {data-filter={data-filter-type=ALWAYS, max=0, min=0, offset=0}, i-signal-in-i-pdu=BMSH_6_Reserved1}
            {data-filter={data-filter-type=ALWAYS, max=1, min=0, offset=0}, i-signal-in-i-pdu=BMSH_OutletWaterTempValid}
            {data-filter={data-filter-type=ALWAYS, max=1, min=0, offset=0}, i-signal-in-i-pdu=BMSH_InletWaterTempValid}
            {data-filter={data-filter-type=ALWAYS, max=3, min=0, offset=0}, i-signal-in-i-pdu=BMSH_PackThermalSensorSts}
            {data-filter={data-filter-type=ALWAYS, max=3, min=0, offset=0}, i-signal-in-i-pdu=BMSH_ThermalManageReq}
            {data-filter={data-filter-type=ALWAYS, max=200, min=0, offset=0}, i-signal-in-i-pdu=BMSH_FlowRateReq}
            {data-filter={data-filter-type=ALWAYS, max=254, min=0, offset=0}, i-signal-in-i-pdu=BMSH_HeatPowerReq}
            {data-filter={data-filter-type=ALWAYS, max=165, min=0}, i-signal-in-i-pdu=BMSH_InletWaterTempTarget}
            {data-filter={data-filter-type=ALWAYS, max=165, min=0}, i-signal-in-i-pdu=BMSH_OutletWaterTemp}
            {data-filter={data-filter-type=ALWAYS, max=165, min=0}, i-signal-in-i-pdu=BMSH_InletWaterTemp}
          signal BMSH_6_CRC: start 63, 8 bit, big-endian, init-value=0, base-type=uint8, compu {raw=phys for phys 0..255}, update-indication-bit-position=-1  # SAE J1850 CRC-8"
          signal BMSH_6_MessageCounter: start 51, 4 bit, big-endian, init-value=0, base-type=uint8, compu {raw=phys for phys 0..15}, update-indication-bit-position=-1  # Alivecounter"
          signal BMSH_WaterTempChangeRateReq: start 55, 4 bit, big-endian, init-value=0, base-type=uint8, compu {raw=phys for phys 0..15; unit oC_s}, update-indication-bit-position=-1  # Water Temp Change Rate Request"
          signal BMSH_6_Reserved1: start 47, 2 bit, big-endian, init-value=0, base-type=uint8, compu {raw=phys for phys 0}, update-indication-bit-position=-1
          signal BMSH_OutletWaterTempValid: start 45, 1 bit, big-endian, init-value=0, base-type=uint8, compu {raw=phys for phys 0..1, 0=VALID, 1=NOTVALID}, update-indication-bit-position=-1  # Outlet Water Temperature Valid"
          signal BMSH_InletWaterTempValid: start 44, 1 bit, big-endian, init-value=0, base-type=uint8, compu {raw=phys for phys 0..1, 0=VALID, 1=NOTVALID}, update-indication-bit-position=-1  # Inlet Water Temperature Valid"
          signal BMSH_PackThermalSensorSts: start 43, 2 bit, big-endian, init-value=0, base-type=uint8, compu-method=CompuMethod_BMSH_PackThermalSensorSts, update-indication-bit-position=-1  # Pack Thermal Temperature Sensor Status"
          signal BMSH_ThermalManageReq: start 41, 2 bit, big-endian, init-value=0, base-type=uint8, compu-method=CompuMethod_BMSH_ThermalManageReq, update-indication-bit-position=-1  # Thermal Manage Request"
          signal BMSH_FlowRateReq: start 39, 8 bit, big-endian, init-value=0, base-type=uint8, compu {raw=phys*10 for phys 0..20; unit L_min}, update-indication-bit-position=-1  # Flow Rate Request"
          signal BMSH_HeatPowerReq: start 31, 8 bit, big-endian, init-value=0, base-type=uint8, compu {raw=phys*25 for phys 0..10.16; unit kw}, update-indication-bit-position=-1  # Heat Power Request"
          signal BMSH_InletWaterTempTarget: start 23, 8 bit, big-endian, init-value=40, base-type=uint8, compu {raw=phys+40 for phys -40..125; unit oC}, update-indication-bit-position=-1  # Inlet Water Temperature Target"
          signal BMSH_OutletWaterTemp: start 15, 8 bit, big-endian, init-value=40, base-type=uint8, compu {raw=phys+40 for phys -40..125; unit oC}, update-indication-bit-position=-1  # Outlet Water Temperature"
          signal BMSH_InletWaterTemp: start 7, 8 bit, big-endian, init-value=40, base-type=uint8, compu {raw=phys+40 for phys -40..125; unit oC}, update-indication-bit-position=-1  # Inlet Water Temperature"
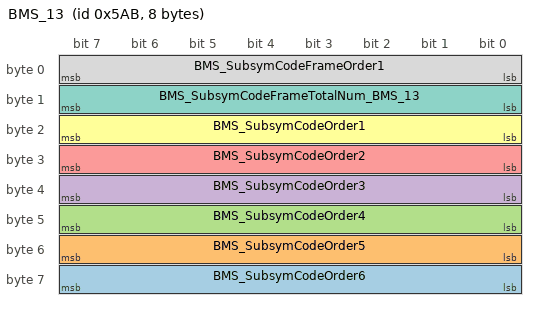
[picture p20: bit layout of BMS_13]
      frame BMS_13: id 0x5AB, from BMS, frame-length=8, can-addressing-mode=STANDARD
        carries pdu BMS_13: packing-byte-order=big-endian, start-position=7, update-indication-bit-position=-1
        pdu BMS_13: length=8, transmission-mode-false-timing=cyclic-timing={time-offset=0.0, time-period=1.0}, transmission-mode-true-timing=cyclic-timing={time-offset=0.0, time-period=1.0}
          transmission-mode-conditions:
            {data-filter={data-filter-type=ALWAYS, max=255, min=0, offset=0}, i-signal-in-i-pdu=BMS_SubsymCodeOrder6}
            {data-filter={data-filter-type=ALWAYS, max=255, min=0, offset=0}, i-signal-in-i-pdu=BMS_SubsymCodeOrder5}
            {data-filter={data-filter-type=ALWAYS, max=255, min=0, offset=0}, i-signal-in-i-pdu=BMS_SubsymCodeOrder4}
            {data-filter={data-filter-type=ALWAYS, max=255, min=0, offset=0}, i-signal-in-i-pdu=BMS_SubsymCodeOrder3}
            {data-filter={data-filter-type=ALWAYS, max=255, min=0, offset=0}, i-signal-in-i-pdu=BMS_SubsymCodeOrder2}
            {data-filter={data-filter-type=ALWAYS, max=255, min=0, offset=0}, i-signal-in-i-pdu=BMS_SubsymCodeOrder1}
            {data-filter={data-filter-type=ALWAYS, max=255, min=0, offset=0}, i-signal-in-i-pdu=BMS_13/BMS_SubsymCodeFrameTotalNum}
            {data-filter={data-filter-type=ALWAYS, max=255, min=0, offset=0}, i-signal-in-i-pdu=BMS_SubsymCodeFrameOrder1}
          signal BMS_SubsymCodeOrder6: start 63, 8 bit, big-endian, init-value=0, base-type=uint8, compu {raw=phys for phys 0..255}, update-indication-bit-position=-1  # Subsym Code number Order6"
          signal BMS_SubsymCodeOrder5: start 55, 8 bit, big-endian, init-value=0, base-type=uint8, compu {raw=phys for phys 0..255}, update-indication-bit-position=-1  # Subsym Code number Order5"
          signal BMS_SubsymCodeOrder4: start 47, 8 bit, big-endian, init-value=0, base-type=uint8, compu {raw=phys for phys 0..255}, update-indication-bit-position=-1  # Subsym Code number Order4"
          signal BMS_SubsymCodeOrder3: start 39, 8 bit, big-endian, init-value=0, base-type=uint8, compu {raw=phys for phys 0..255}, update-indication-bit-position=-1  # Subsym Code number Order3"
          signal BMS_SubsymCodeOrder2: start 31, 8 bit, big-endian, init-value=0, base-type=uint8, compu {raw=phys for phys 0..255}, update-indication-bit-position=-1  # Subsym Code number Order2"
          signal BMS_SubsymCodeOrder1: start 23, 8 bit, big-endian, init-value=0, base-type=uint8, compu {raw=phys for phys 0..255}, update-indication-bit-position=-1  # Subsym Code number Order1"
          signal BMS_SubsymCodeFrameTotalNum_BMS_13: start 15, 8 bit, big-endian, init-value=0, base-type=uint8, compu {raw=phys for phys 0..255}, update-indication-bit-position=-1  # Subsym Code Frame Total Number"
          signal BMS_SubsymCodeFrameOrder1: start 7, 8 bit, big-endian, init-value=0, base-type=uint8, compu {raw=phys for phys 0..255}, update-indication-bit-position=-1  # Subsym Code Frame Order1"
      frame BMS_12: id 0x5AA, from BMS, frame-length=8, can-addressing-mode=STANDARD
        carries pdu BMS_12: packing-byte-order=big-endian, start-position=7, update-indication-bit-position=-1
        pdu BMS_12: length=8, transmission-mode-false-timing=cyclic-timing={time-offset=0.0, time-period=1.0}, transmission-mode-true-timing=cyclic-timing={time-offset=0.0, time-period=1.0}
          transmission-mode-conditions:
            {data-filter={data-filter-type=ALWAYS, max=1, min=0, offset=0}, i-signal-in-i-pdu=BMSH_BalanceActive}
            {data-filter={data-filter-type=ALWAYS, max=1, min=0, offset=0}, i-signal-in-i-pdu=BMSH_Battery_Uniformity}
            {data-filter={data-filter-type=ALWAYS, max=1, min=0, offset=0}, i-signal-in-i-pdu=BMSH_StoredEnergySys}
            {data-filter={data-filter-type=ALWAYS, max=1, min=0, offset=0}, i-signal-in-i-pdu=BMSH_Charge_Over}
            {data-filter={data-filter-type=ALWAYS, max=1, min=0, offset=0}, i-signal-in-i-pdu=BMSH_HVILcuitFailure}
            {data-filter={data-filter-type=ALWAYS, max=1, min=0, offset=0}, i-signal-in-i-pdu=BMSH_Battery_Mismatching}
            {data-filter={data-filter-type=ALWAYS, max=3, min=0, offset=0}, i-signal-in-i-pdu=BMSH_BatteryTempLightSts}
            {data-filter={data-filter-type=ALWAYS, max=3, min=0, offset=0}, i-signal-in-i-pdu=BMSH_Charge_Over_Current}
            {data-filter={data-filter-type=ALWAYS, max=3, min=0, offset=0}, i-signal-in-i-pdu=BMSH_Discharge_Over_Current}
            {data-filter={data-filter-type=ALWAYS, max=3, min=0, offset=0}, i-signal-in-i-pdu=BMSH_IsocircuitFailure}
            {data-filter={data-filter-type=ALWAYS, max=1, min=0, offset=0}, i-signal-in-i-pdu=BMSH_Cell_Voltage_Uniformity}
            {data-filter={data-filter-type=ALWAYS, max=3, min=0, offset=0}, i-signal-in-i-pdu=BMSH_LowSOC}
            {data-filter={data-filter-type=ALWAYS, max=3, min=0, offset=0}, i-signal-in-i-pdu=BMSH_CellUnderVol}
            {data-filter={data-filter-type=ALWAYS, max=3, min=0, offset=0}, i-signal-in-i-pdu=BMSH_CellOverVol}
            {data-filter={data-filter-type=ALWAYS, max=3, min=0, offset=0}, i-signal-in-i-pdu=BMSH_OverSOC}
            {data-filter={data-filter-type=ALWAYS, max=3, min=0, offset=0}, i-signal-in-i-pdu=BMSH_Battery_Under_Voltage}
            {data-filter={data-filter-type=ALWAYS, max=3, min=0, offset=0}, i-signal-in-i-pdu=BMSH_Battery_Over_Voltage}
            {data-filter={data-filter-type=ALWAYS, max=3, min=0, offset=0}, i-signal-in-i-pdu=BMSH_Low_Temperature}
            {data-filter={data-filter-type=ALWAYS, max=3, min=0, offset=0}, i-signal-in-i-pdu=BMSH_Over_Temperature}
            {data-filter={data-filter-type=NEW-IS-WITHIN, max=20000, min=0, offset=0}, i-signal-in-i-pdu=BMSH_PacksubsystemVolt}
            {data-filter={data-filter-type=ALWAYS, max=1, min=0, offset=0}, i-signal-in-i-pdu=BMSH_SOC_Jump}
            {data-filter={data-filter-type=NEW-IS-WITHIN, max=26000, min=6000}, i-signal-in-i-pdu=BMSH_PacksubsystemCurrent}
            {data-filter={data-filter-type=ALWAYS, max=1, min=0, offset=0}, i-signal-in-i-pdu=BMSH_TempUniformity}
          signal BMSH_BalanceActive: start 63, 1 bit, big-endian, init-value=0, base-type=uint8, compu {raw=phys for phys 0..1, 0=NORMAL, 1=ACTIVE}, update-indication-bit-position=-1  # Balance Active"
          signal BMSH_Battery_Uniformity: start 62, 1 bit, big-endian, init-value=0, base-type=uint8, compu {raw=phys for phys 0..1, 0=NORMAL, 1=FAULT}, update-indication-bit-position=-1  # Battery Uniformity fault"
          signal BMSH_StoredEnergySys: start 61, 1 bit, big-endian, init-value=0, base-type=uint8, compu {raw=phys for phys 0..1, 0=NORMAL, 1=FAULT}, update-indication-bit-position=-1  # Stored Energy System fault"
          signal BMSH_Charge_Over: start 60, 1 bit, big-endian, init-value=0, base-type=uint8, compu {raw=phys for phys 0..1, 0=NORMAL, 1=FAULT}, update-indication-bit-position=-1  # Charge Over fault"
          signal BMSH_HVILcuitFailure: start 59, 1 bit, big-endian, init-value=0, base-type=uint8, compu {raw=phys for phys 0..1, 0=NORMAL, 1=FAULT}, update-indication-bit-position=-1  # HV interlock Failure"
          signal BMSH_Battery_Mismatching: start 58, 1 bit, big-endian, init-value=0, base-type=uint8, compu {raw=phys for phys 0..1, 0=NORMAL, 1=FAULT}, update-indication-bit-position=-1  # Battery Mismatching fault"
          signal BMSH_BatteryTempLightSts: start 57, 2 bit, big-endian, init-value=0, base-type=uint8, compu {raw=phys for phys 0..3, 0=OFF, 1=HIGH, 2=LOW, 3=NOTUSED}, update-indication-bit-position=-1  # Battery Temperature Light Status"
          signal BMSH_Charge_Over_Current: start 55, 2 bit, big-endian, init-value=0, base-type=uint8, compu {raw=phys for phys 0..3, 0=NORMAL, 1=WARMING, 2=ALARM, 3=ERROR}, update-indication-bit-position=-1  # Charge Over Current warning"
          signal BMSH_Discharge_Over_Current: start 53, 2 bit, big-endian, init-value=0, base-type=uint8, compu {raw=phys for phys 0..3, 0=NORMAL, 1=WARMING, 2=ALARM, 3=ERROR}, update-indication-bit-position=-1  # Discharge Over Current warning"
          signal BMSH_IsocircuitFailure: start 51, 2 bit, big-endian, init-value=0, base-type=uint8, compu {raw=phys for phys 0..3, 0=NOWARNING, 1=WARNING, 2=RESERVED, 3=ALARM}, update-indication-bit-position=-1  # insulation circuit Failure warning"
          signal BMSH_Cell_Voltage_Uniformity: start 49, 2 bit, big-endian, init-value=0, base-type=uint8, compu-method=CompuMethod_BMSH_Cell_Voltage_Uniformity, update-indication-bit-position=-1  # Cell Voltage Uniformity warning"
          signal BMSH_LowSOC: start 47, 2 bit, big-endian, init-value=0, base-type=uint8, compu {raw=phys for phys 0..3, 0=NOWARNING, 1=WARNING, 2=RESERVED, 3=ALARM}, update-indication-bit-position=-1  # SOC low warning"
          signal BMSH_CellUnderVol: start 45, 2 bit, big-endian, init-value=0, base-type=uint8, compu-method=CompuMethod_BMSH_CellUnderVol, update-indication-bit-position=-1  # Cell Under Voltage warning"
          signal BMSH_CellOverVol: start 43, 2 bit, big-endian, init-value=0, base-type=uint8, compu-method=CompuMethod_BMSH_CellOverVol, update-indication-bit-position=-1  # Cell Over Voltage warning"
          signal BMSH_OverSOC: start 41, 2 bit, big-endian, init-value=0, base-type=uint8, compu-method=CompuMethod_BMSH_OverSOC, update-indication-bit-position=-1  # SOC Over warning"
          signal BMSH_Battery_Under_Voltage: start 39, 2 bit, big-endian, init-value=0, base-type=uint8, compu-method=CompuMethod_BMSH_Battery_Under_Voltage, update-indication-bit-position=-1  # Battery Under Voltage warning"
          signal BMSH_Battery_Over_Voltage: start 37, 2 bit, big-endian, init-value=0, base-type=uint8, compu-method=CompuMethod_BMSH_Battery_Over_Voltage, update-indication-bit-position=-1  # Battery Over Voltage warning"
          signal BMSH_Low_Temperature: start 35, 2 bit, big-endian, init-value=0, base-type=uint8, compu-method=CompuMethod_BMSH_Low_Temperature, update-indication-bit-position=-1  # Low temperature warning"
          signal BMSH_Over_Temperature: start 33, 2 bit, big-endian, init-value=0, base-type=uint8, compu-method=CompuMethod_BMSH_Over_Temperature, update-indication-bit-position=-1  # Over temperature warning"
          signal BMSH_PacksubsystemVolt: start 23, 15 bit, big-endian, init-value=0, base-type=uint16, compu {raw=phys*10 for phys 0..2000; unit V}, update-indication-bit-position=-1  # subsystem voltage"
          signal BMSH_SOC_Jump: start 24, 1 bit, big-endian, init-value=0, base-type=uint8, compu {raw=phys for phys 0..1, 0=NORMAL, 1=FAULT}, update-indication-bit-position=-1  # SOC Jump warning"
          signal BMSH_PacksubsystemCurrent: start 7, 15 bit, big-endian, init-value=16000, base-type=uint16, compu {raw=phys*10+16000 for phys -1000..1000; unit Ampere}, update-indication-bit-position=-1  # subsystem current"
          signal BMSH_TempUniformity: start 8, 1 bit, big-endian, init-value=0, base-type=uint8, compu {raw=phys for phys 0..1, 0=NORMAL, 1=FAULT}, update-indication-bit-position=-1  # Temperature Uniformity fault"
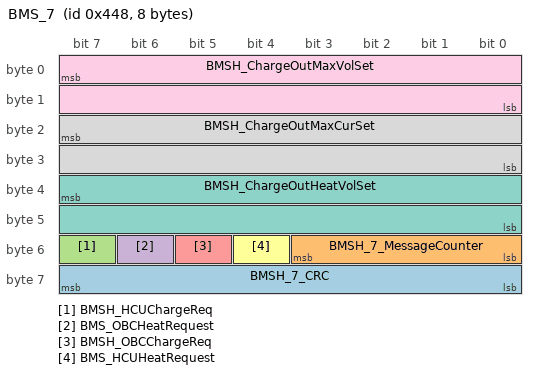
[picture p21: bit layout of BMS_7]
      frame BMS_7: id 0x448, from BMS, frame-length=8, can-addressing-mode=STANDARD
        carries pdu BMS_7: packing-byte-order=big-endian, start-position=7, update-indication-bit-position=-1
        pdu BMS_7: length=8, transmission-mode-false-timing=cyclic-timing={time-offset=0.0, time-period=0.1}, transmission-mode-true-timing=cyclic-timing={time-offset=0.0, time-period=0.1}
          transmission-mode-conditions:
            {data-filter={data-filter-type=ALWAYS, max=255, min=0, offset=0}, i-signal-in-i-pdu=BMSH_7_CRC}
            {data-filter={data-filter-type=ALWAYS, max=15, min=0, offset=0}, i-signal-in-i-pdu=BMSH_7_MessageCounter}
            {data-filter={data-filter-type=ALWAYS, max=1, min=0, offset=0}, i-signal-in-i-pdu=BMSH_HCUChargeReq}
            {data-filter={data-filter-type=ALWAYS, max=1, min=0, offset=0}, i-signal-in-i-pdu=BMS_OBCHeatRequest}
            {data-filter={data-filter-type=ALWAYS, max=1, min=0, offset=0}, i-signal-in-i-pdu=BMSH_OBCChargeReq}
            {data-filter={data-filter-type=ALWAYS, max=1, min=0, offset=0}, i-signal-in-i-pdu=BMS_HCUHeatRequest}
            {data-filter={data-filter-type=NEW-IS-WITHIN, max=20000, min=0, offset=0}, i-signal-in-i-pdu=BMSH_ChargeOutHeatVolSet}
            {data-filter={data-filter-type=NEW-IS-WITHIN, max=1000, min=0, offset=0}, i-signal-in-i-pdu=BMSH_ChargeOutMaxCurSet}
            {data-filter={data-filter-type=NEW-IS-WITHIN, max=20000, min=0, offset=0}, i-signal-in-i-pdu=BMSH_ChargeOutMaxVolSet}
          signal BMSH_7_CRC: start 63, 8 bit, big-endian, init-value=0, base-type=uint8, compu {raw=phys for phys 0..255}, update-indication-bit-position=-1  # SAE J1850 CRC-8"
          signal BMSH_7_MessageCounter: start 51, 4 bit, big-endian, init-value=0, base-type=uint8, compu {raw=phys for phys 0..15}, update-indication-bit-position=-1  # Alivecounter"
          signal BMSH_HCUChargeReq: start 55, 1 bit, big-endian, init-value=0, base-type=uint8, compu {raw=phys for phys 0..1, 0=NOREQUEST, 1=REQUEST}, update-indication-bit-position=-1  # HCU Charge Request"
          signal BMS_OBCHeatRequest: start 54, 1 bit, big-endian, init-value=0, base-type=uint8, compu {raw=phys for phys 0..1, 0=NOREQUEST, 1=REQUEST}, update-indication-bit-position=-1  # BMS battery OBC heat request"
          signal BMSH_OBCChargeReq: start 53, 1 bit, big-endian, init-value=0, base-type=uint8, compu {raw=phys for phys 0..1, 0=NOREQUEST, 1=REQUEST}, update-indication-bit-position=-1  # OBC Charge Request"
          signal BMS_HCUHeatRequest: start 52, 1 bit, big-endian, init-value=0, base-type=uint8, compu {raw=phys for phys 0..1, 0=NOREQUEST, 1=REQUEST}, update-indication-bit-position=-1  # BMS battery HCU heat request"
          signal BMSH_ChargeOutHeatVolSet: start 39, 16 bit, big-endian, init-value=0, base-type=uint16, compu {raw=phys*20 for phys 0..1000; unit V}, update-indication-bit-position=-1  # Charge Output Heat Voltage Set"
          signal BMSH_ChargeOutMaxCurSet: start 23, 16 bit, big-endian, init-value=0, base-type=uint16, compu {raw=phys*20 for phys 0..50; unit Ampere}, update-indication-bit-position=-1  # Charge Output Maximum Current Set"
          signal BMSH_ChargeOutMaxVolSet: start 7, 16 bit, big-endian, init-value=0, base-type=uint16, compu {raw=phys*20 for phys 0..1000; unit V}, update-indication-bit-position=-1  # Charge Output Maximum Voltage Set"
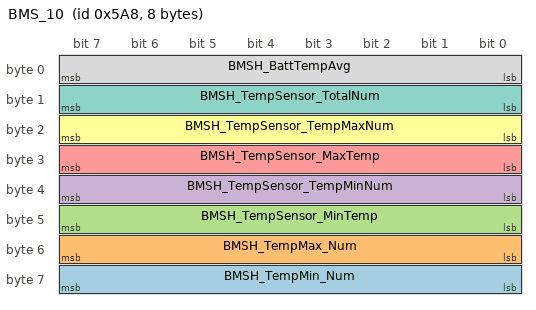
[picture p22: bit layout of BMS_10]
      frame BMS_10: id 0x5A8, from BMS, frame-length=8, can-addressing-mode=STANDARD
        carries pdu BMS_10: packing-byte-order=big-endian, start-position=7, update-indication-bit-position=-1
        pdu BMS_10: length=8, transmission-mode-false-timing=cyclic-timing={time-offset=0.0, time-period=1.0}, transmission-mode-true-timing=cyclic-timing={time-offset=0.0, time-period=1.0}
          transmission-mode-conditions:
            {data-filter={data-filter-type=ALWAYS, max=255, min=0, offset=0}, i-signal-in-i-pdu=BMSH_TempMin_Num}
            {data-filter={data-filter-type=ALWAYS, max=255, min=0, offset=0}, i-signal-in-i-pdu=BMSH_TempMax_Num}
            {data-filter={data-filter-type=ALWAYS, max=163, min=0}, i-signal-in-i-pdu=BMSH_TempSensor_MinTemp}
            {data-filter={data-filter-type=ALWAYS, max=255, min=0, offset=0}, i-signal-in-i-pdu=BMSH_TempSensor_TempMinNum}
            {data-filter={data-filter-type=ALWAYS, max=163, min=0}, i-signal-in-i-pdu=BMSH_TempSensor_MaxTemp}
            {data-filter={data-filter-type=ALWAYS, max=255, min=0, offset=0}, i-signal-in-i-pdu=BMSH_TempSensor_TempMaxNum}
            {data-filter={data-filter-type=ALWAYS, max=255, min=0, offset=0}, i-signal-in-i-pdu=BMSH_TempSensor_TotalNum}
            {data-filter={data-filter-type=ALWAYS, max=163, min=0}, i-signal-in-i-pdu=BMSH_BattTempAvg}
          signal BMSH_TempMin_Num: start 63, 8 bit, big-endian, init-value=0, base-type=uint8, compu {raw=phys for phys 0..255}, update-indication-bit-position=-1  # Temperature sensor minimum subsystem number"
          signal BMSH_TempMax_Num: start 55, 8 bit, big-endian, init-value=0, base-type=uint8, compu {raw=phys for phys 0..255}, update-indication-bit-position=-1  # Temperature sensor maximum subsystem number"
          signal BMSH_TempSensor_MinTemp: start 47, 8 bit, big-endian, init-value=40, base-type=uint8, compu {raw=phys+40 for phys -40..123; unit oC}, update-indication-bit-position=-1  # Temperature sensor minimum value"
          signal BMSH_TempSensor_TempMinNum: start 39, 8 bit, big-endian, init-value=0, base-type=uint8, compu {raw=phys for phys 0..255}, update-indication-bit-position=-1  # Temperature sensor minimum number"
          signal BMSH_TempSensor_MaxTemp: start 31, 8 bit, big-endian, init-value=40, base-type=uint8, compu {raw=phys+40 for phys -40..123; unit oC}, update-indication-bit-position=-1  # Temperature sensor maximum value"
          signal BMSH_TempSensor_TempMaxNum: start 23, 8 bit, big-endian, init-value=0, base-type=uint8, compu {raw=phys for phys 0..255}, update-indication-bit-position=-1  # Temperature sensor maximum number"
          signal BMSH_TempSensor_TotalNum: start 15, 8 bit, big-endian, init-value=0, base-type=uint8, compu {raw=phys for phys 0..255}, update-indication-bit-position=-1  # Temperature sensor total number"
          signal BMSH_BattTempAvg: start 7, 8 bit, big-endian, init-value=40, base-type=uint8, compu {raw=phys+40 for phys -40..123; unit oC}, update-indication-bit-position=-1  # Battery Temperatur Average"
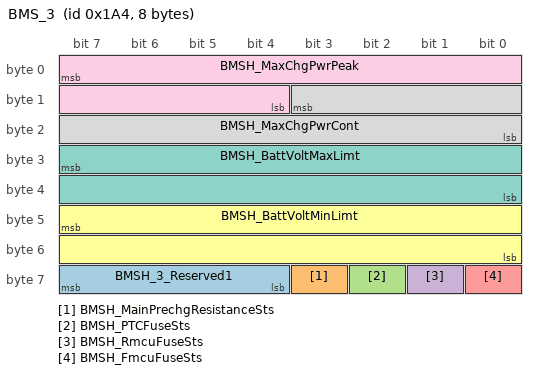
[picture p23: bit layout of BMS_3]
      frame BMS_3: id 0x1A4, from BMS, frame-length=8, can-addressing-mode=STANDARD
        carries pdu BMS_3: packing-byte-order=big-endian, start-position=7, update-indication-bit-position=-1
        pdu BMS_3: length=8, transmission-mode-false-timing=cyclic-timing={time-offset=0.0, time-period=0.01}, transmission-mode-true-timing=cyclic-timing={time-offset=0.0, time-period=0.01}
          transmission-mode-conditions:
            {data-filter={data-filter-type=ALWAYS, max=0, min=0, offset=0}, i-signal-in-i-pdu=BMSH_3_Reserved1}
            {data-filter={data-filter-type=ALWAYS, max=1, min=0, offset=0}, i-signal-in-i-pdu=BMSH_MainPrechgResistanceSts}
            {data-filter={data-filter-type=ALWAYS, max=1, min=0, offset=0}, i-signal-in-i-pdu=BMSH_PTCFuseSts}
            {data-filter={data-filter-type=ALWAYS, max=1, min=0, offset=0}, i-signal-in-i-pdu=BMSH_RmcuFuseSts}
            {data-filter={data-filter-type=ALWAYS, max=1, min=0, offset=0}, i-signal-in-i-pdu=BMSH_FmcuFuseSts}
            {data-filter={data-filter-type=NEW-IS-WITHIN, max=20000, min=0, offset=0}, i-signal-in-i-pdu=BMSH_BattVoltMinLimt}
            {data-filter={data-filter-type=NEW-IS-WITHIN, max=20000, min=0, offset=0}, i-signal-in-i-pdu=BMSH_BattVoltMaxLimt}
            {data-filter={data-filter-type=NEW-IS-WITHIN, max=3200, min=0, offset=0}, i-signal-in-i-pdu=BMSH_MaxChgPwrCont}
            {data-filter={data-filter-type=NEW-IS-WITHIN, max=3200, min=0, offset=0}, i-signal-in-i-pdu=BMSH_MaxChgPwrPeak}
          signal BMSH_3_Reserved1: start 63, 4 bit, big-endian, init-value=0, base-type=uint8, compu {raw=phys for phys 0}, update-indication-bit-position=-1
          signal BMSH_MainPrechgResistanceSts: start 59, 1 bit, big-endian, init-value=0, base-type=uint8, compu {raw=phys for phys 0..1, 0=NORMAL, 1=BROKEN}, update-indication-bit-position=-1  # Main Precharge Resistance Status"
          signal BMSH_PTCFuseSts: start 58, 1 bit, big-endian, init-value=0, base-type=uint8, compu {raw=phys for phys 0..1, 0=NORMAL, 1=BROKEN}, update-indication-bit-position=-1  # PTC Fuse Status"
          signal BMSH_RmcuFuseSts: start 57, 1 bit, big-endian, init-value=0, base-type=uint8, compu {raw=phys for phys 0..1, 0=NORMAL, 1=BROKEN}, update-indication-bit-position=-1  # Rear mcu Fuse Status"
          signal BMSH_FmcuFuseSts: start 56, 1 bit, big-endian, init-value=0, base-type=uint8, compu {raw=phys for phys 0..1, 0=NORMAL, 1=BROKEN}, update-indication-bit-position=-1  # Front mcu Fuse Status"
          signal BMSH_BattVoltMinLimt: start 47, 16 bit, big-endian, init-value=0, base-type=uint16, compu {raw=phys*20 for phys 0..1000; unit V}, update-indication-bit-position=-1  # Battery Voltage Minimum Limit"
          signal BMSH_BattVoltMaxLimt: start 31, 16 bit, big-endian, init-value=0, base-type=uint16, compu {raw=phys*20 for phys 0..1000; unit V}, update-indication-bit-position=-1  # Battery Voltage Maximum Limit"
          signal BMSH_MaxChgPwrCont: start 11, 12 bit, big-endian, init-value=0, base-type=uint16, compu {raw=phys*10 for phys 0..320; unit KW}, update-indication-bit-position=-1  # Maximum Charge Power constant"
          signal BMSH_MaxChgPwrPeak: start 7, 12 bit, big-endian, init-value=0, base-type=uint16, compu {raw=phys*10 for phys 0..320; unit KW}, update-indication-bit-position=-1  # Maximum Charge Power Peak"
      frame BMS_Vol_24: id 0x557, from BMS, frame-length=8, can-addressing-mode=STANDARD
        carries pdu BMS_Vol_24: packing-byte-order=big-endian, start-position=7, update-indication-bit-position=-1
        pdu BMS_Vol_24: length=8, transmission-mode-false-timing=cyclic-timing={time-offset=0.0, time-period=1.0}, transmission-mode-true-timing=cyclic-timing={time-offset=0.0, time-period=1.0}
          transmission-mode-conditions:
            {data-filter={data-filter-type=NEW-IS-WITHIN, max=5000, min=0, offset=0}, i-signal-in-i-pdu=BMS_BattCellOrder96Vol}
            {data-filter={data-filter-type=NEW-IS-WITHIN, max=5000, min=0, offset=0}, i-signal-in-i-pdu=BMS_BattCellOrder95Vol}
            {data-filter={data-filter-type=NEW-IS-WITHIN, max=5000, min=0, offset=0}, i-signal-in-i-pdu=BMS_BattCellOrder94Vol}
            {data-filter={data-filter-type=NEW-IS-WITHIN, max=5000, min=0, offset=0}, i-signal-in-i-pdu=BMS_BattCellOrder93Vol}
          signal BMS_BattCellOrder96Vol: start 55, 16 bit, big-endian, init-value=0, base-type=uint16, compu {raw=phys for phys 0..5000; unit mV}, update-indication-bit-position=-1  # Battery Cell voltage Order96"
          signal BMS_BattCellOrder95Vol: start 39, 16 bit, big-endian, init-value=0, base-type=uint16, compu {raw=phys for phys 0..5000; unit mV}, update-indication-bit-position=-1  # Battery Cell voltage Order95"
          signal BMS_BattCellOrder94Vol: start 23, 16 bit, big-endian, init-value=0, base-type=uint16, compu {raw=phys for phys 0..5000; unit mV}, update-indication-bit-position=-1  # Battery Cell voltage Order94"
          signal BMS_BattCellOrder93Vol: start 7, 16 bit, big-endian, init-value=0, base-type=uint16, compu {raw=phys for phys 0..5000; unit mV}, update-indication-bit-position=-1  # Battery Cell voltage Order93"
      frame BMS_Vol_23: id 0x556, from BMS, frame-length=8, can-addressing-mode=STANDARD
        carries pdu BMS_Vol_23: packing-byte-order=big-endian, start-position=7, update-indication-bit-position=-1
        pdu BMS_Vol_23: length=8, transmission-mode-false-timing=cyclic-timing={time-offset=0.0, time-period=1.0}, transmission-mode-true-timing=cyclic-timing={time-offset=0.0, time-period=1.0}
          transmission-mode-conditions:
            {data-filter={data-filter-type=NEW-IS-WITHIN, max=5000, min=0, offset=0}, i-signal-in-i-pdu=BMS_BattCellOrder92Vol}
            {data-filter={data-filter-type=NEW-IS-WITHIN, max=5000, min=0, offset=0}, i-signal-in-i-pdu=BMS_BattCellOrder91Vol}
            {data-filter={data-filter-type=NEW-IS-WITHIN, max=5000, min=0, offset=0}, i-signal-in-i-pdu=BMS_BattCellOrder90Vol}
            {data-filter={data-filter-type=NEW-IS-WITHIN, max=5000, min=0, offset=0}, i-signal-in-i-pdu=BMS_BattCellOrder89Vol}
          signal BMS_BattCellOrder92Vol: start 55, 16 bit, big-endian, init-value=0, base-type=uint16, compu {raw=phys for phys 0..5000; unit mV}, update-indication-bit-position=-1  # Battery Cell voltage Order92"
          signal BMS_BattCellOrder91Vol: start 39, 16 bit, big-endian, init-value=0, base-type=uint16, compu {raw=phys for phys 0..5000; unit mV}, update-indication-bit-position=-1  # Battery Cell voltage Order91"
          signal BMS_BattCellOrder90Vol: start 23, 16 bit, big-endian, init-value=0, base-type=uint16, compu {raw=phys for phys 0..5000; unit mV}, update-indication-bit-position=-1  # Battery Cell voltage Order90"
          signal BMS_BattCellOrder89Vol: start 7, 16 bit, big-endian, init-value=0, base-type=uint16, compu {raw=phys for phys 0..5000; unit mV}, update-indication-bit-position=-1  # Battery Cell voltage Order89"
      frame BMS_Vol_22: id 0x555, from BMS, frame-length=8, can-addressing-mode=STANDARD
        carries pdu BMS_Vol_22: packing-byte-order=big-endian, start-position=7, update-indication-bit-position=-1
        pdu BMS_Vol_22: length=8, transmission-mode-false-timing=cyclic-timing={time-offset=0.0, time-period=1.0}, transmission-mode-true-timing=cyclic-timing={time-offset=0.0, time-period=1.0}
          transmission-mode-conditions:
            {data-filter={data-filter-type=NEW-IS-WITHIN, max=5000, min=0, offset=0}, i-signal-in-i-pdu=BMS_BattCellOrder88Vol}
            {data-filter={data-filter-type=NEW-IS-WITHIN, max=5000, min=0, offset=0}, i-signal-in-i-pdu=BMS_BattCellOrder87Vol}
            {data-filter={data-filter-type=NEW-IS-WITHIN, max=5000, min=0, offset=0}, i-signal-in-i-pdu=BMS_BattCellOrder86Vol}
            {data-filter={data-filter-type=NEW-IS-WITHIN, max=5000, min=0, offset=0}, i-signal-in-i-pdu=BMS_BattCellOrder85Vol}
          signal BMS_BattCellOrder88Vol: start 55, 16 bit, big-endian, init-value=0, base-type=uint16, compu {raw=phys for phys 0..5000; unit mV}, update-indication-bit-position=-1  # Battery Cell voltage Order88"
          signal BMS_BattCellOrder87Vol: start 39, 16 bit, big-endian, init-value=0, base-type=uint16, compu {raw=phys for phys 0..5000; unit mV}, update-indication-bit-position=-1  # Battery Cell voltage Order87"
          signal BMS_BattCellOrder86Vol: start 23, 16 bit, big-endian, init-value=0, base-type=uint16, compu {raw=phys for phys 0..5000; unit mV}, update-indication-bit-position=-1  # Battery Cell voltage Order86"
          signal BMS_BattCellOrder85Vol: start 7, 16 bit, big-endian, init-value=0, base-type=uint16, compu {raw=phys for phys 0..5000; unit mV}, update-indication-bit-position=-1  # Battery Cell voltage Order85"
      frame BMS_Vol_21: id 0x554, from BMS, frame-length=8, can-addressing-mode=STANDARD
        carries pdu BMS_Vol_21: packing-byte-order=big-endian, start-position=7, update-indication-bit-position=-1
        pdu BMS_Vol_21: length=8, transmission-mode-false-timing=cyclic-timing={time-offset=0.0, time-period=1.0}, transmission-mode-true-timing=cyclic-timing={time-offset=0.0, time-period=1.0}
          transmission-mode-conditions:
            {data-filter={data-filter-type=NEW-IS-WITHIN, max=5000, min=0, offset=0}, i-signal-in-i-pdu=BMS_BattCellOrder84Vol}
            {data-filter={data-filter-type=NEW-IS-WITHIN, max=5000, min=0, offset=0}, i-signal-in-i-pdu=BMS_BattCellOrder83Vol}
            {data-filter={data-filter-type=NEW-IS-WITHIN, max=5000, min=0, offset=0}, i-signal-in-i-pdu=BMS_BattCellOrder82Vol}
            {data-filter={data-filter-type=NEW-IS-WITHIN, max=5000, min=0, offset=0}, i-signal-in-i-pdu=BMS_BattCellOrder81Vol}
          signal BMS_BattCellOrder84Vol: start 55, 16 bit, big-endian, init-value=0, base-type=uint16, compu {raw=phys for phys 0..5000; unit mV}, update-indication-bit-position=-1  # Battery Cell voltage Order84"
          signal BMS_BattCellOrder83Vol: start 39, 16 bit, big-endian, init-value=0, base-type=uint16, compu {raw=phys for phys 0..5000; unit mV}, update-indication-bit-position=-1  # Battery Cell voltage Order83"
          signal BMS_BattCellOrder82Vol: start 23, 16 bit, big-endian, init-value=0, base-type=uint16, compu {raw=phys for phys 0..5000; unit mV}, update-indication-bit-position=-1  # Battery Cell voltage Order82"
          signal BMS_BattCellOrder81Vol: start 7, 16 bit, big-endian, init-value=0, base-type=uint16, compu {raw=phys for phys 0..5000; unit mV}, update-indication-bit-position=-1  # Battery Cell voltage Order81"
      frame BMS_4: id 0x1AB, from BMS, frame-length=8, can-addressing-mode=STANDARD
        carries pdu BMS_4: packing-byte-order=big-endian, start-position=7, update-indication-bit-position=-1
        pdu BMS_4: length=8, transmission-mode-false-timing=cyclic-timing={time-offset=0.0, time-period=0.01}, transmission-mode-true-timing=cyclic-timing={time-offset=0.0, time-period=0.01}
          transmission-mode-conditions:
            {data-filter={data-filter-type=ALWAYS, max=0, min=0, offset=0}, i-signal-in-i-pdu=BMSH_4_Reserved1}
            {data-filter={data-filter-type=NEW-IS-WITHIN, max=64000, min=0}, i-signal-in-i-pdu=BMSH_MaxChargeCurrent}
            {data-filter={data-filter-type=NEW-IS-WITHIN, max=64000, min=0}, i-signal-in-i-pdu=BMSH_MaxDischargeCurrent}
            {data-filter={data-filter-type=NEW-IS-WITHIN, max=3200, min=0, offset=0}, i-signal-in-i-pdu=BMSH_MaxDchgPwrCont}
            {data-filter={data-filter-type=NEW-IS-WITHIN, max=3200, min=0, offset=0}, i-signal-in-i-pdu=BMSH_MaxDchgPwrPeak}
          signal BMSH_4_Reserved1: start 63, 8 bit, big-endian, init-value=0, base-type=uint8, compu {raw=phys for phys 0}, update-indication-bit-position=-1
          signal BMSH_MaxChargeCurrent: start 47, 16 bit, big-endian, init-value=32000, base-type=uint16, compu {raw=phys*20+32000 for phys -1600..1600; unit Ampere}, update-indication-bit-position=-1  # Maximum Charge Current"
          signal BMSH_MaxDischargeCurrent: start 31, 16 bit, big-endian, init-value=32000, base-type=uint16, compu {raw=phys*20+32000 for phys -1600..1600; unit Ampere}, update-indication-bit-position=-1  # Maximum Discharge Current"
          signal BMSH_MaxDchgPwrCont: start 11, 12 bit, big-endian, init-value=0, base-type=uint16, compu {raw=phys*10 for phys 0..320; unit KW}, update-indication-bit-position=-1  # Maximum Discharge Power Constant"
          signal BMSH_MaxDchgPwrPeak: start 7, 12 bit, big-endian, init-value=0, base-type=uint16, compu {raw=phys*10 for phys 0..320; unit KW}, update-indication-bit-position=-1  # Maximum Discharge Power Peak"
      frame BMS_11: id 0x5A9, from BMS, frame-length=8, can-addressing-mode=STANDARD
        carries pdu BMS_11: packing-byte-order=big-endian, start-position=7, update-indication-bit-position=-1
        pdu BMS_11: length=8, transmission-mode-false-timing=cyclic-timing={time-offset=0.0, time-period=1.0}, transmission-mode-true-timing=cyclic-timing={time-offset=0.0, time-period=1.0}
          transmission-mode-conditions:
            {data-filter={data-filter-type=NEW-IS-WITHIN, max=5000, min=0, offset=0}, i-signal-in-i-pdu=BMSH_CellVoltMin}
            {data-filter={data-filter-type=NEW-IS-WITHIN, max=5000, min=0, offset=0}, i-signal-in-i-pdu=BMSH_CellVoltMax}
            {data-filter={data-filter-type=ALWAYS, max=255, min=0, offset=0}, i-signal-in-i-pdu=BMSH_CellVoltMin_Num}
            {data-filter={data-filter-type=ALWAYS, max=255, min=0, offset=0}, i-signal-in-i-pdu=BMSH_CellVoltMax_Num}
            {data-filter={data-filter-type=ALWAYS, max=255, min=0, offset=0}, i-signal-in-i-pdu=BMSH_VoltMin_Num}
            {data-filter={data-filter-type=ALWAYS, max=255, min=0, offset=0}, i-signal-in-i-pdu=BMSH_VoltMax_Num}
          signal BMSH_CellVoltMin: start 55, 16 bit, big-endian, init-value=0, base-type=uint16, compu {raw=phys for phys 0..5000; unit mV}, update-indication-bit-position=-1  # Cell voltage sensor minimum value"
          signal BMSH_CellVoltMax: start 39, 16 bit, big-endian, init-value=0, base-type=uint16, compu {raw=phys for phys 0..5000; unit mV}, update-indication-bit-position=-1  # Cell voltage sensor maximum value"
          signal BMSH_CellVoltMin_Num: start 31, 8 bit, big-endian, init-value=0, base-type=uint8, compu {raw=phys for phys 0..255}, update-indication-bit-position=-1  # Cell voltage sensor minimum number"
          signal BMSH_CellVoltMax_Num: start 23, 8 bit, big-endian, init-value=0, base-type=uint8, compu {raw=phys for phys 0..255}, update-indication-bit-position=-1  # Cell voltage sensor maximum number"
          signal BMSH_VoltMin_Num: start 15, 8 bit, big-endian, init-value=0, base-type=uint8, compu {raw=phys for phys 0..255}, update-indication-bit-position=-1  # Cell voltage sensor minimum subsystem number"
          signal BMSH_VoltMax_Num: start 7, 8 bit, big-endian, init-value=0, base-type=uint8, compu {raw=phys for phys 0..255}, update-indication-bit-position=-1  # Cell voltage sensor maximum subsystem number"
package /DBC_SysDesc_Can_Network/Pkg_Ecu
  ecu instance BMS: com-configuration-gw-time-base=0.005, com-configuration-rx-time-base=0.01, com-configuration-tx-time-base=0.01, sleep-mode-supported=false, wake-up-over-bus-supported=false
    can communication controller Can_Network_CANNODE_0: can-controller-attributes=can-controller-configuration={prop-seg=2, sync-jump-width=1, time-seg-1=12, time-seg-2=5}
    can communication connector Conn_Can_Network_CANNODE_0_BMS: comm-controller=Can_Network_CANNODE_0
package /DBC_SysDesc_Can_Network/Pkg_CompuMethod
  compu method CompuMethod_ISGF_ModeSt: raw=phys for phys 0..15, 11=SERVICE, 12..15=RESERVED, 0=INIT_INITIALIZATION_, 1=LVSTANDBY_PRECHARGE_, 2=HVSTANDBY_DISABLE_, 3=TQCONTROL, 4=VOLTCONTROL, 5=SPDCONTROL, 6=OFFSETCALIBRATION, 7=POWERDOWN_DISCHARGE_, 8=AFTERRUN, 9=FAILURE, 10=OFF
  compu method CompuMethod_BMSH_Battery_Under_Voltage: raw=phys for phys 0..3, 0=NORMAL, 1=FAULTLEVELI, 2=FAULTLEVELII, 3=FAULTLEVELIII
  compu method CompuMethod_TMF_ModeSt: raw=phys for phys 0..15, 11=SERVICE, 12..15=RESERVED, 0=INIT_INITIALIZATION_, 1=LVSTANDBY_PRECHARGE_, 2=HVSTANDBY_DISABLE_, 3=TQCONTROL, 4=VOLTCONTROL, 5=SPDCONTROL, 6=OFFSETCALIBRATION, 7=POWERDOWN_DISCHARGE_, 8=AFTERRUN, 9=FAILURE, 10=OFF
  compu method CompuMethod_BMSH_InterHVILSts: raw=phys for phys 0..3, 0=NORMAL, 1=MALFUNCITON, 2=RESERVED, 3=RESERVED
  compu method CompuMethod_BMSH_WorkingMode: raw=phys for phys 0..3, 0=RUNNINGMODE, 1=SLEEPMODE, 2=RESERVED, 3=RESERVED
  compu method CompuMethod_BMSH_CellUnderVol: raw=phys for phys 0..3, 0=NORMAL, 1=FAULTLEVELI, 2=FAULTLEVELII, 3=FAULTLEVELIII
  compu method CompuMethod_BMSH_VehicleHVILSts: raw=phys for phys 0..3, 0=NORMAL, 1=MALFUNCITON, 2=RESERVED, 3=RESERVED
  compu method CompuMethod_HCU_BMS_stModeReq: raw=phys for phys 0..7, 0=STANDBY, 1=OPERATIONAL, 2=CHARGE, 3=POWERDOWN, 4=EMERGENYDISCHARGE, 5=HEAT, 6=RESERVED, 7=RESERVED
  compu method CompuMethod_BMSH_InterHVILSts_BMS_2: raw=phys for phys 0..3, 0=NORMAL, 1=MALFUNCITON, 2=RESERVED, 3=RESERVED
  compu method CompuMethod_BMSH_ChgFaultLevel: raw=phys for phys 0..15, 11..15=RESERVED, 0=DEFAULT, 1=NORMAL, 2=WARNING, 3=DERATEPOWER, 4=RESERVED, 5=SHUTDOWN_, 6=EMSHUTDOWN_, 7..10=RESERVED
  compu method CompuMethod_BMSH_InsulationSts: raw=phys for phys 0..3, 0=INSULATIONOK_DEFAULT_, 1=INSULATIONWARNING, 2=INSULATIONERROR, 3=INVALID
  compu method CompuMethod_OBC_ChargeSourceMode: raw=phys for phys 0, 0=NONE, 1=CONSTANTVOLTAGE, 2=CONSTANTCURRENT, 3=RESERVED
  compu method CompuMethod_BMSH_stMode_BMS_2: raw=phys for phys 0..15, 11=BATTHEAT, 12=HEATFINISH, 13=RESERVED, 14=RESERVED, 15=RESERVED, 0=INIT, 1=STANDBY, 2=PRECHARGE, 3=OPERATIONAL, 4=CHARGE, 5=POWERDOWN, 6=AFTERRUN, 7=SERVICE, 8=EMERGENYDISCHARGE, 9=FAULT, 10=HEATPRECHARGE
  compu method CompuMethod_BMSH_Low_Temperature: raw=phys for phys 0..3, 0=NORMAL, 1=FAULTLEVELI, 2=FAULTLEVELII, 3=FAULTLEVELIII
  compu method CompuMethod_BMSH_PackThermalSensorSts: raw=phys for phys 0..3, 0=NORMAL, 1=INLETSENSORERROR, 2=OUTLETSENSORERROR, 3=ALLERROR
  compu method CompuMethod_BMSH_DisChgFaultLevel: raw=phys for phys 0..15, 11..15=RESERVED, 0=DEFAULT, 1=NORMAL, 2=WARNING, 3=DERATEPOWER, 4=RESERVED, 5=SHUTDOWN_, 6=EMSHUTDOWN_, 7..10=RESERVED
  compu method CompuMethod_BMSH_Over_Temperature: raw=phys for phys 0..3, 0=NORMAL, 1=FAULTLEVELI, 2=FAULTLEVELII, 3=FAULTLEVELIII
  compu method CompuMethod_BMSH_PackChargingThermalSt: raw=phys for phys 0..7, 0=NONE, 1=HEATING, 2=COOLINGANDCHARGING, 3=CHARGING, 4=CHARGEFINISH, 5=THERMALERROR, 6=RESERVED, 7=RESERVED
  compu method CompuMethod_BMSH_Cell_Voltage_Uniformity: raw=phys for phys 0..1, 0=NORMAL, 1=FAUTLEVELI, 2=FAUTLEVELII, 3=FAUTLEVELIII
  compu method CompuMethod_OBC_WorkingMode: raw=phys for phys 0..7, 0=INIT, 1=STANDBY, 2=CHARGE, 3=HEAT, 4=FAULT, 5=OFF, 6=POWERDOWN, 7=RESERVED
  compu method CompuMethod_BMSH_MainPrechgSt: raw=phys for phys 0..7, 0=DEFAULT, 1=PRECHARGING, 2=PRECHGARGESUCEED, 3=PRECHARGEFAILUE, 4=PRECHARGELOCKED, 5=RESERVED, 6=RESERVED, 7=RESERVED
  compu method CompuMethod_BMSH_stMode: raw=phys for phys 0..15, 11=BATTHEAT, 12=HEATFINISH, 13=RESERVED, 14=RESERVED, 15=RESERVED, 0=INIT, 1=STANDBY, 2=PRECHARGE, 3=OPERATIONAL, 4=CHARGE, 5=POWERDOWN, 6=AFTERRUN, 7=SERVICE, 8=EMERGENYDISCHARGE, 9=FAULT, 10=HEATPRECHARGE
  compu method CompuMethod_BMSH_Battery_Over_Voltage: raw=phys for phys 0..3, 0=NORMAL, 1=FAULTLEVELI, 2=FAULTLEVELII, 3=FAULTLEVELIII
  compu method CompuMethod_BMSH_PackFaultLevel: raw=phys for phys 0..7, 0=NOFAULT, 1=ALARM, 2=DERATING, 3=SHUTDOWN, 4=EMERGENCYSHUTDOWN, 5=RESERVED, 6=RESERVED, 7=RESERVED
  compu method CompuMethod_OBC_ChgSts: raw=phys for phys 0..7, 0=NOCHARGE, 1=CHARGING, 2=CHARGEFINISHED, 3=CHARGESTOP, 4..7=RESERVED
  compu method CompuMethod_BMSH_OBCPrechgSt: raw=phys for phys 0..7, 0=DEFAULT, 1=PRECHARGING, 2=PRECHGARGESUCEED, 3=PRECHARGEFAILUE, 4=PRECHARGELOCKED, 5=RESERVED, 6=RESERVED, 7=RESERVED
  compu method CompuMethod_TMR_State: raw=phys for phys 0..15, 11=SERVICE_RESERVED_, 12..15=RESERVED, 0=INIT_INITIALIZATION_, 1=LVSTANDBY_PRECHARGE_, 2=HVSTANDBY_DISABLE_, 3=TQCONTROL, 4=VOLTCONTROL_RESERVED_, 5=SPDCONTROL_RESERVED_, 6=OFFSETCALIBRATION, 7=POWERDOWN_DISCHARGE_, 8=AFTERRUN_RESERVED_, 9=FAILURE, 10=OFF_RESERVED_
  compu method CompuMethod_OBD_DrivingCycle: raw=phys for phys 0..1, 0=PROPULSIONSYSTEMNOTACTIVE, 1=PROPULSIONSYSTEMACTIVE
  compu method CompuMethod_BMSH_CellOverVol: raw=phys for phys 0..3, 0=NORMAL, 1=FAULTLEVELI, 2=FAULTLEVELII, 3=FAULTLEVELIII
  compu method CompuMethod_BMSH_ThermalManageReq: raw=phys for phys 0..3, 0=DEFAULT_NOREQUEST, 1=HEATING, 2=COOLING, 3=BALANCETEMPERATUREREQUEST
  compu method CompuMethod_OBC_FaultLevelSts: raw=phys for phys 0..7, 0=NOFAULT, 1=LEVER1FAULT, 2=LEVER2FAULT, 3=LEVER3FAULT, 4..7=RESERVED
  compu method CompuMethod_OBC_CC_ConnectSts: raw=phys for phys 0..3, 0=NOTCONNECTED, 1=CONNECTED, 2=PARTIALCONNECTED, 3=INVALID
  compu method CompuMethod_BMSH_BattTypeCode: raw=phys for phys 0..255, 0=RESERVED, 1=LITHIUMIRONPHOSPHATEBATTERY, 255=OTHER, 2=LITHIUMMANGANATEBATTERY, 3=LITHIUMCOBALTBATTERY, 4=TERNARYMATERIALBATTERY, 5=POLYMERLITHIUMIONBATTERY, 6=SUPERCAPACITOR, 7=LITHIUMTITANATEBATTERY, 252=FUELCELL
  compu method CompuMethod_BMSH_OverSOC: raw=phys for phys 0..3, 0=NORMAL, 1=FAUTLEVELI, 2=FAUTLEVELII, 3=FAUTLEVELIII
  compu method CompuMethod_BMSH_InsulationSts_BMS_2: raw=phys for phys 0..3, 0=INSULATIONOK_DEFAULT_, 1=INSULATIONWARNING, 2=INSULATIONERROR, 3=INVALID
  compu method CompuMethod_ExternalTemperatureFailSts_GS: raw=phys for phys 0..3, 0=FAILNOTPRESENT, 1=SHORTGROUND, 2=SHORTPOWER_OPENCIRCUIT_, 3=RESERVED
  compu method CompuMethod_CrashOutputSts: raw=phys for phys 0..255, 0=NOCRASH, 1=BELTCRASH, 2=FRONTCRASH, 4=LEFTSIDECRASH, 16=REARCRASH, 8=RIGHTSIDECRASH
package /DBC_SysDesc_Can_Network/Pkg_Units
  19 x unit:
    mV
    oC
    V
    KWH
    C
    pct
    KW
    Ampere
    L_min
    rpm
    kw
    Kw
    KwH
    oC_s
    km_h
    NOUNIT
    km
    Minute
    k
